VERSION ""

NS_ :

BS_:

BU_: CHUD_LS VKM_LS RCRM_LS MSM_RR_LS MSM_LR_LS CGM_LS BSM_LS VPM_LS ISRVM_LS DCAC_LS TouchPad_LS RSC_LS LVMPC_LS EOCM2B_K1_LS EOCM2A_K1_LS LCM_LS TIM_B_LS V2V_LS TCP_LS CSM_LS EOCM2B_K2_LS EOCM2A_K2_LS TIM_A_LS LVMNav_LS HFP_LS EDI_LS ARB_LS RSE_LS Dummy_LS VIS2_LS ICS_LS FCM_LS EOCM_F_LS VICM_LS AGC_LS MSM_P_LS OTIM_LS HVSM_R_LS HVSM_F_LS DVB_T_LS SBZA_R_LS PSD_R_LS PSD_L_LS UHP_Low UPA_LS STC_LS SBZA_L_LS PTM_LS ONSTAR_LS APA_LS TestTool_LS PHS_LS PDIM_LS CHM_LS RSA_LS AMP_LS HUD_LS MSM_LS HBSM_LS SCL_LS ECC_LS RadioHead_LS PEPS_LS IPC_LS AOS_LS SDM_LS TIM_LS BCM_LS

BO_ 2152775680 Front_360_Camera_On_LS: 8 VPM_LS
 SG_ CrgBdVwLtCustSetVal : 49|2@0+ (1,0) [0|3] ""  CSM_LS,RadioHead_LS
 SG_ CrgBdVwLtCustSetAvl : 54|1@0+ (1,0) [0|1] ""  CSM_LS,RadioHead_LS
 SG_ TrlrMirVGlnCustSetVal : 51|2@0+ (1,0) [0|3] ""  CSM_LS,RadioHead_LS
 SG_ TrlrMirVGlnCustSetAvl : 55|1@0+ (1,0) [0|1] ""  CSM_LS,RadioHead_LS
 SG_ TrlrMirVEnCustSetVal : 30|2@0+ (1,0) [0|3] ""  CSM_LS,RadioHead_LS
 SG_ TrlrMirVEnCustSetAvl : 31|1@0+ (1,0) [0|1] ""  CSM_LS,RadioHead_LS
 SG_ TrlrArtcltnAnglCalStat : 62|2@0+ (1,0) [0|3] ""  CSM_LS,RadioHead_LS
 SG_ InvTrlrAx1CamRollAlgnd : 57|1@0+ (1,0) [0|1] ""  CSM_LS,RadioHead_LS
 SG_ InvTrlrAx1CamPtchAlgnd : 58|1@0+ (1,0) [0|1] ""  CSM_LS,RadioHead_LS
 SG_ InvTrlrAx1CamYAlgnd : 59|1@0+ (1,0) [0|1] ""  CSM_LS,RadioHead_LS
 SG_ InvTrlrAx1CamXAlgnd : 60|1@0+ (1,0) [0|1] ""  CSM_LS,RadioHead_LS
 SG_ RPDCA_Resrv3Avail : 17|1@0+ (1,0) [0|1] ""  CSM_LS,RadioHead_LS
 SG_ RPDCA_Resrv2Avail : 18|1@0+ (1,0) [0|1] ""  CSM_LS,RadioHead_LS
 SG_ RPDCA_Resrv1Avail : 19|1@0+ (1,0) [0|1] ""  CSM_LS,RadioHead_LS
 SG_ RPDCA_AlrtBrkAvail : 20|1@0+ (1,0) [0|1] ""  CSM_LS,RadioHead_LS
 SG_ RPDCA_AlrtAvail : 21|1@0+ (1,0) [0|1] ""  CSM_LS,RadioHead_LS
 SG_ RPDCA_OnAvail : 22|1@0+ (1,0) [0|1] ""  CSM_LS,RadioHead_LS
 SG_ RPDCA_OfAvail : 23|1@0+ (1,0) [0|1] ""  CSM_LS,RadioHead_LS
 SG_ JacknfDetRHapSReqSN : 47|2@0+ (1,0) [0|3] ""  MSM_P_LS,MSM_LS
 SG_ JacknfDetRHapSReq : 45|6@0+ (1,0) [0|63] ""  MSM_P_LS,MSM_LS
 SG_ JacknfDetLHapSReqSN : 39|2@0+ (1,0) [0|3] ""  MSM_P_LS,MSM_LS
 SG_ JacknfDetLHapSReq : 37|6@0+ (1,0) [0|63] ""  MSM_P_LS,MSM_LS
 SG_ JacknfDetCustSetVal : 53|2@0+ (1,0) [0|3] ""  CSM_LS,RadioHead_LS
 SG_ JacknfDetCustSetAvl : 63|1@0+ (1,0) [0|1] ""  CSM_LS,RadioHead_LS
 SG_ DispTrgdVidOn : 14|1@0+ (1,0) [0|1] ""  CSM_LS,RadioHead_LS
 SG_ a_360DegVidFetrPrsnt : 15|1@0+ (1,0) [0|1] ""  CSM_LS,RadioHead_LS
 SG_ TrgdVidRecFetrPrsnt : 7|1@0+ (1,0) [0|1] ""  CSM_LS,RadioHead_LS
 SG_ RrPdDetHptcStVbRq : 13|6@0+ (1,0) [0|63] "Pulse"  MSM_P_LS,MSM_LS
 SG_ RrPdDetHptcStVbRqSeqN : 6|2@0+ (1,0) [0|3] ""  MSM_P_LS,MSM_LS
 SG_ RrPedDetCstStVal : 4|3@0+ (1,0) [0|7] ""  CSM_LS,RadioHead_LS
 SG_ RrPedDetCstStAvl : 1|1@0+ (1,0) [0|1] ""  CSM_LS,RadioHead_LS
 SG_ PudlLmpReqstd : 28|1@0+ (1,0) [0|1] ""  BCM_LS
 SG_ SurdVwLightgCsCurrSetVal : 26|3@0+ (1,0) [0|7] ""  CSM_LS,RadioHead_LS
 SG_ DispSmrtTwVidOn : 16|1@0+ (1,0) [0|1] ""  CSM_LS,RadioHead_LS
 SG_ DispFrt360CamOn : 0|1@0+ (1,0) [0|1] ""  CSM_LS,RadioHead_LS
 SG_ SurdVwLightgCsSetAvail : 27|1@0+ (1,0) [0|1] ""  CSM_LS,RadioHead_LS

BO_ 2153857024 Teen_Driver_Event_Report_2_LS: 8 BCM_LS
 SG_ TnDrvTrCtrlEvntsRpt : 49|10@0+ (1,0) [0|1023] "counts"  CGM_LS,CSM_LS,RadioHead_LS
 SG_ TnDrvDrowDrvAlrtsRpt : 43|10@0+ (1,0) [0|1023] "counts"  CGM_LS,CSM_LS,RadioHead_LS
 SG_ TDRCADD_WOTEvnts : 11|1@0+ (1,0) [0|1] ""  CGM_LS,CSM_LS,RadioHead_LS
 SG_ TDRCADD_LDWEvnts : 10|1@0+ (1,0) [0|1] ""  CGM_LS,CSM_LS,RadioHead_LS
 SG_ TDRCADD_FCMBrEvts : 13|1@0+ (1,0) [0|1] ""  CGM_LS,CSM_LS,RadioHead_LS
 SG_ TDRCADD_DrwDrvAlrt : 12|1@0+ (1,0) [0|1] ""  CGM_LS,CSM_LS,RadioHead_LS
 SG_ TDRCADD_RCMBrEvts : 14|1@0+ (1,0) [0|1] ""  CGM_LS,CSM_LS,RadioHead_LS
 SG_ TDRCADD_FCImntAlrts : 15|1@0+ (1,0) [0|1] ""  CGM_LS,CSM_LS,RadioHead_LS
 SG_ TDRCADD_FCHdwyAlrt : 0|1@0+ (1,0) [0|1] ""  CGM_LS,CSM_LS,RadioHead_LS
 SG_ TDRCADD_StCtrlEvnts : 2|1@0+ (1,0) [0|1] ""  CGM_LS,CSM_LS,RadioHead_LS
 SG_ TDRCADD_ABSAtvEvt : 1|1@0+ (1,0) [0|1] ""  CGM_LS,CSM_LS,RadioHead_LS
 SG_ TDRCADD_TrCtrlEvnts : 3|1@0+ (1,0) [0|1] ""  CGM_LS,CSM_LS,RadioHead_LS
 SG_ TDRCADD_OvSpdEvnt : 4|1@0+ (1,0) [0|1] ""  CGM_LS,CSM_LS,RadioHead_LS
 SG_ TDRCADD_DistDrvn : 5|1@0+ (1,0) [0|1] ""  CGM_LS,CSM_LS,RadioHead_LS
 SG_ TDRCADD_MaxSpd : 6|1@0+ (1,0) [0|1] ""  CGM_LS,CSM_LS,RadioHead_LS
 SG_ TnDrvStblCtrlEvntsRpt : 37|10@0+ (1,0) [0|1023] "counts"  CGM_LS,CSM_LS,RadioHead_LS
 SG_ TnDrvABSAtvEvntsRpt : 31|10@0+ (1,0) [0|1023] "counts"  CGM_LS,CSM_LS,RadioHead_LS
 SG_ TeenDrvWOTEvntsRpt : 9|10@0+ (1,0) [0|1023] "counts"  CGM_LS,CSM_LS,RadioHead_LS

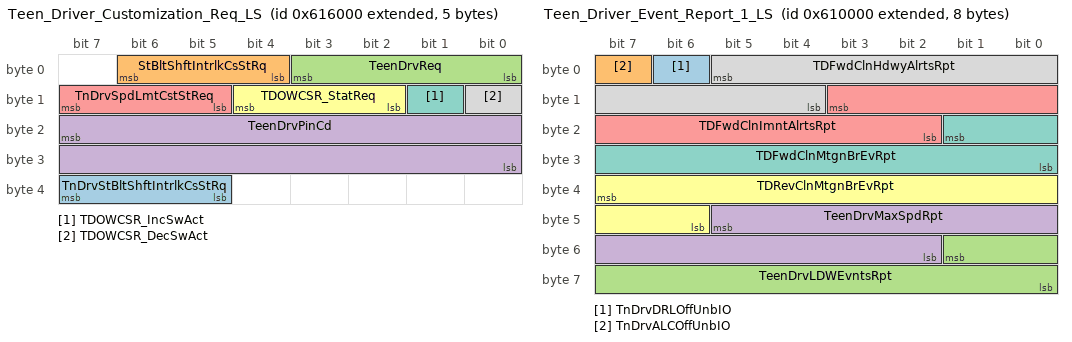
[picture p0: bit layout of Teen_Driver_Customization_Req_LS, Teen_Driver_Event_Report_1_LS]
BO_ 2153865216 Teen_Driver_Customization_Req_LS: 5 RadioHead_LS
 SG_ TnDrvStBltShftIntrlkCsStRq : 39|3@0+ (1,0) [0|7] ""  BCM_LS
 SG_ StBltShftIntrlkCsStRq : 6|3@0+ (1,0) [0|7] ""  BCM_LS
 SG_ TeenDrvReq : 3|4@0+ (1,0) [0|15] ""  BCM_LS
 SG_ TeenDrvPinCd : 23|16@0+ (1,0) [0|39321] ""  BCM_LS
 SG_ TnDrvSpdLmtCstStReq : 15|3@0+ (1,0) [0|7] ""  BCM_LS
 SG_ TDOWCSR_StatReq : 12|3@0+ (1,0) [0|7] ""  BCM_LS
 SG_ TDOWCSR_IncSwAct : 9|1@0+ (1,0) [0|1] ""  BCM_LS
 SG_ TDOWCSR_DecSwAct : 8|1@0+ (1,0) [0|1] ""  BCM_LS

BO_ 2153840640 Teen_Driver_Event_Report_1_LS: 8 BCM_LS
 SG_ TnDrvDRLOffUnbIO : 6|1@0+ (1,0) [0|1] ""  CGM_LS,IPC_LS
 SG_ TnDrvALCOffUnbIO : 7|1@0+ (1,0) [0|1] ""  CGM_LS,IPC_LS
 SG_ TeenDrvLDWEvntsRpt : 49|10@0+ (1,0) [0|1023] "counts"  CGM_LS,CSM_LS,RadioHead_LS
 SG_ TeenDrvMaxSpdRpt : 45|12@0+ (0.0625,0) [0|255.9375] "km/h"  CGM_LS,CSM_LS,RadioHead_LS
 SG_ TDFwdClnImntAlrtsRpt : 11|10@0+ (1,0) [0|1023] "counts"  CGM_LS,CSM_LS,RadioHead_LS
 SG_ TDRevClnMtgnBrEvRpt : 39|10@0+ (1,0) [0|1023] "counts"  CGM_LS,CSM_LS,RadioHead_LS
 SG_ TDFwdClnMtgnBrEvRpt : 17|10@0+ (1,0) [0|1023] "counts"  CGM_LS,CSM_LS,RadioHead_LS
 SG_ TDFwdClnHdwyAlrtsRpt : 5|10@0+ (1,0) [0|1023] "counts"  CGM_LS,CSM_LS,RadioHead_LS

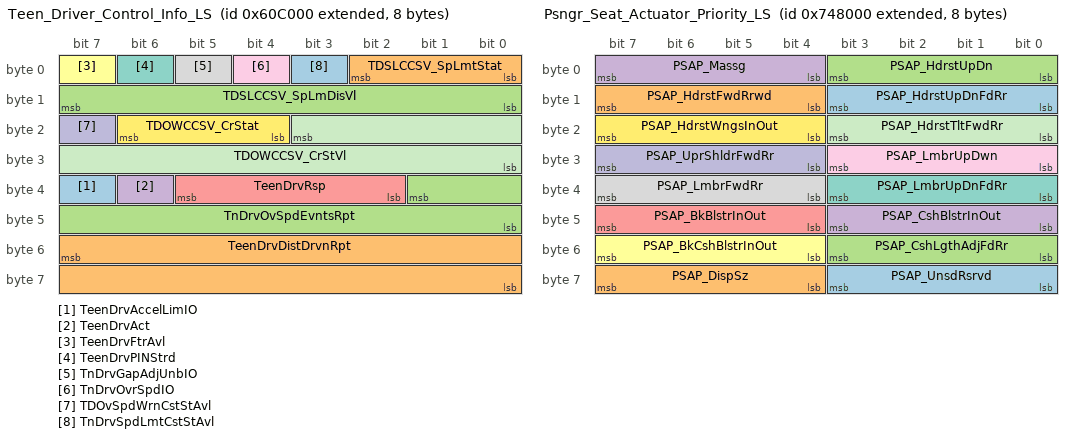
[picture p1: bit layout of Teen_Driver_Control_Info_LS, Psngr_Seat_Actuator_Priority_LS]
BO_ 2153824256 Teen_Driver_Control_Info_LS: 8 BCM_LS
 SG_ TeenDrvAccelLimIO : 39|1@0+ (1,0) [0|1] ""  IPC_LS,CGM_LS
 SG_ TeenDrvDistDrvnRpt : 55|16@0+ (1,0) [0|65535] "km"  EOCM2A_K2_LS,EOCM2B_K2_LS,CGM_LS,CSM_LS,RadioHead_LS
 SG_ TnDrvOvSpdEvntsRpt : 33|10@0+ (1,0) [0|1023] "counts"  EOCM2A_K2_LS,EOCM2B_K2_LS,CGM_LS,CSM_LS,RadioHead_LS
 SG_ TeenDrvAct : 38|1@0+ (1,0) [0|1] ""  EOCM2A_K2_LS,EOCM2B_K2_LS,V2V_LS,CGM_LS,SBZA_R_LS,IPC_LS,SBZA_L_LS,UPA_LS,APA_LS,LVMPC_LS,VIS2_LS,FCM_LS,EOCM_F_LS,CSM_LS,RadioHead_LS
 SG_ TeenDrvRsp : 37|4@0+ (1,0) [0|15] ""  EOCM2A_K2_LS,EOCM2B_K2_LS,CGM_LS,CSM_LS,RadioHead_LS
 SG_ TeenDrvFtrAvl : 7|1@0+ (1,0) [0|1] ""  EOCM2A_K2_LS,EOCM2B_K2_LS,CGM_LS,CSM_LS,RadioHead_LS
 SG_ TeenDrvPINStrd : 6|1@0+ (1,0) [0|1] ""  EOCM2A_K2_LS,EOCM2B_K2_LS,CGM_LS,CSM_LS,RadioHead_LS
 SG_ TnDrvGapAdjUnbIO : 5|1@0+ (1,0) [0|1] ""  EOCM2A_K2_LS,EOCM2B_K2_LS,CGM_LS,IPC_LS
 SG_ TnDrvOvrSpdIO : 4|1@0+ (1,0) [0|1] ""  EOCM2A_K2_LS,EOCM2B_K2_LS,CGM_LS,IPC_LS
 SG_ TDOvSpdWrnCstStAvl : 23|1@0+ (1,0) [0|1] ""  EOCM2A_K2_LS,EOCM2B_K2_LS,CGM_LS,CSM_LS,RadioHead_LS
 SG_ TDOWCCSV_CrStVl : 19|12@0+ (0.0625,0) [0|255.9375] "km/h"  EOCM2A_K2_LS,EOCM2B_K2_LS,CGM_LS,IPC_LS,CSM_LS,RadioHead_LS
 SG_ TDOWCCSV_CrStat : 22|3@0+ (1,0) [0|7] ""  EOCM2A_K2_LS,EOCM2B_K2_LS,CGM_LS,IPC_LS,CSM_LS,RadioHead_LS
 SG_ TnDrvSpdLmtCstStAvl : 3|1@0+ (1,0) [0|1] ""  EOCM2A_K2_LS,EOCM2B_K2_LS,CGM_LS,CSM_LS,RadioHead_LS
 SG_ TDSLCCSV_SpLmtStat : 2|3@0+ (1,0) [0|7] ""  EOCM2A_K2_LS,EOCM2B_K2_LS,CGM_LS,IPC_LS,CSM_LS,RadioHead_LS
 SG_ TDSLCCSV_SpLmDisVl : 15|8@0+ (2,0) [0|510] "km/h"  EOCM2A_K2_LS,EOCM2B_K2_LS,CGM_LS,IPC_LS,CSM_LS,RadioHead_LS

BO_ 2155151360 Psngr_Seat_Massage_Priority_LS: 8 MSM_P_LS
 SG_ PSMP_UnsdRsrvd : 56|1@0+ (1,0) [0|1] ""  CGM_LS,CSM_LS,RadioHead_LS
 SG_ PSMP_MaxDispVal : 59|3@0+ (1,0) [0|7] ""  CGM_LS,CSM_LS,RadioHead_LS
 SG_ PSMP_Type15 : 63|4@0+ (1,0) [0|15] ""  CGM_LS,CSM_LS,RadioHead_LS
 SG_ PSMP_Type14 : 51|4@0+ (1,0) [0|15] ""  CGM_LS,CSM_LS,RadioHead_LS
 SG_ PSMP_Type13 : 55|4@0+ (1,0) [0|15] ""  CGM_LS,CSM_LS,RadioHead_LS
 SG_ PSMP_Type12 : 43|4@0+ (1,0) [0|15] ""  CGM_LS,CSM_LS,RadioHead_LS
 SG_ PSMP_Type11 : 47|4@0+ (1,0) [0|15] ""  CGM_LS,CSM_LS,RadioHead_LS
 SG_ PSMP_Type10 : 35|4@0+ (1,0) [0|15] ""  CGM_LS,CSM_LS,RadioHead_LS
 SG_ PSMP_Type9 : 39|4@0+ (1,0) [0|15] ""  CGM_LS,CSM_LS,RadioHead_LS
 SG_ PSMP_Type8 : 27|4@0+ (1,0) [0|15] ""  CGM_LS,CSM_LS,RadioHead_LS
 SG_ PSMP_Type7 : 31|4@0+ (1,0) [0|15] ""  CGM_LS,CSM_LS,RadioHead_LS
 SG_ PSMP_Type6 : 19|4@0+ (1,0) [0|15] ""  CGM_LS,CSM_LS,RadioHead_LS
 SG_ PSMP_Type5 : 23|4@0+ (1,0) [0|15] ""  CGM_LS,CSM_LS,RadioHead_LS
 SG_ PSMP_Type4 : 11|4@0+ (1,0) [0|15] ""  CGM_LS,CSM_LS,RadioHead_LS
 SG_ PSMP_Type3 : 15|4@0+ (1,0) [0|15] ""  CGM_LS,CSM_LS,RadioHead_LS
 SG_ PSMP_Type2 : 3|4@0+ (1,0) [0|15] ""  CGM_LS,CSM_LS,RadioHead_LS
 SG_ PSMP_Type1 : 7|4@0+ (1,0) [0|15] ""  CGM_LS,CSM_LS,RadioHead_LS

BO_ 2155134976 Psngr_Seat_Control_Disp_Stat_LS: 6 MSM_P_LS
 SG_ PsngrSetRrwdMvmnt : 6|3@0+ (1,0) [0|7] ""  CGM_LS,MSM_RR_LS
 SG_ PSCDS_UnsdRsrvd : 42|3@0+ (1,0) [0|7] ""  CGM_LS,CSM_LS,RadioHead_LS
 SG_ PSCDS_DispReq : 43|1@0+ (1,0) [0|1] ""  CGM_LS,CSM_LS,RadioHead_LS
 SG_ PSCDS_DispSz : 45|2@0+ (1,0) [0|3] ""  CGM_LS,CSM_LS,RadioHead_LS
 SG_ PSCDS_CshLgAdjFdRr : 47|2@0+ (1,0) [0|3] ""  CGM_LS,CSM_LS,RadioHead_LS
 SG_ PSCDS_BkCshBlstInOt : 34|3@0+ (1,0) [0|7] ""  CGM_LS,CSM_LS,RadioHead_LS
 SG_ PSCDS_CshBlstrInOut : 36|2@0+ (1,0) [0|3] ""  CGM_LS,CSM_LS,RadioHead_LS
 SG_ PSCDS_BkBlstrInOut : 38|2@0+ (1,0) [0|3] ""  CGM_LS,CSM_LS,RadioHead_LS
 SG_ PSCDS_LmbrUDnFdRr : 25|3@0+ (1,0) [0|7] ""  CGM_LS,CSM_LS,RadioHead_LS
 SG_ PSCDS_LmbrFwdRr : 27|2@0+ (1,0) [0|3] ""  CGM_LS,CSM_LS,RadioHead_LS
 SG_ PSCDS_LmbrUpDwn : 29|2@0+ (1,0) [0|3] ""  CGM_LS,CSM_LS,RadioHead_LS
 SG_ PSCDS_UprShldrFdRr : 31|2@0+ (1,0) [0|3] ""  CGM_LS,CSM_LS,RadioHead_LS
 SG_ PSCDS_HdrstTltFwdRr : 17|2@0+ (1,0) [0|3] ""  CGM_LS,CSM_LS,RadioHead_LS
 SG_ PSCDS_HdrstWngInOt : 19|2@0+ (1,0) [0|3] ""  CGM_LS,CSM_LS,RadioHead_LS
 SG_ PSCDS_HdrstUDnFdRr : 22|3@0+ (1,0) [0|7] ""  CGM_LS,CSM_LS,RadioHead_LS
 SG_ PSCDS_HdrstFwdRrwd : 8|2@0+ (1,0) [0|3] ""  CGM_LS,CSM_LS,RadioHead_LS
 SG_ PSCDS_HdrstUpDn : 10|2@0+ (1,0) [0|3] ""  CGM_LS,CSM_LS,RadioHead_LS
 SG_ PSCDS_MassgIntsty : 13|3@0+ (1,0) [0|7] ""  CGM_LS,CSM_LS,RadioHead_LS
 SG_ PSCDS_MassgTyp : 1|4@0+ (1,0) [0|15] ""  CGM_LS,CSM_LS,RadioHead_LS
 SG_ PSCDS_Massg : 3|2@0+ (1,0) [0|3] ""  CGM_LS,CSM_LS,RadioHead_LS

BO_ 2155118592 Psngr_Seat_Actuator_Priority_LS: 8 MSM_P_LS
 SG_ PSAP_UnsdRsrvd : 59|4@0+ (1,0) [0|15] ""  CGM_LS,CSM_LS,RadioHead_LS
 SG_ PSAP_DispSz : 63|4@0+ (1,0) [0|15] ""  CGM_LS,CSM_LS,RadioHead_LS
 SG_ PSAP_CshLgthAdjFdRr : 51|4@0+ (1,0) [0|15] ""  CGM_LS,CSM_LS,RadioHead_LS
 SG_ PSAP_CshBlstrInOut : 43|4@0+ (1,0) [0|15] ""  CGM_LS,CSM_LS,RadioHead_LS
 SG_ PSAP_BkBlstrInOut : 47|4@0+ (1,0) [0|15] ""  CGM_LS,CSM_LS,RadioHead_LS
 SG_ PSAP_BkCshBlstrInOut : 55|4@0+ (1,0) [0|15] ""  CGM_LS,CSM_LS,RadioHead_LS
 SG_ PSAP_LmbrUpDnFdRr : 35|4@0+ (1,0) [0|15] ""  CGM_LS,CSM_LS,RadioHead_LS
 SG_ PSAP_LmbrFwdRr : 39|4@0+ (1,0) [0|15] ""  CGM_LS,CSM_LS,RadioHead_LS
 SG_ PSAP_LmbrUpDwn : 27|4@0+ (1,0) [0|15] ""  CGM_LS,CSM_LS,RadioHead_LS
 SG_ PSAP_UprShldrFwdRr : 31|4@0+ (1,0) [0|15] ""  CGM_LS,CSM_LS,RadioHead_LS
 SG_ PSAP_HdrstTltFwdRr : 19|4@0+ (1,0) [0|15] ""  CGM_LS,CSM_LS,RadioHead_LS
 SG_ PSAP_HdrstWngsInOut : 23|4@0+ (1,0) [0|15] ""  CGM_LS,CSM_LS,RadioHead_LS
 SG_ PSAP_HdrstUpDnFdRr : 11|4@0+ (1,0) [0|15] ""  CGM_LS,CSM_LS,RadioHead_LS
 SG_ PSAP_HdrstFwdRrwd : 15|4@0+ (1,0) [0|15] ""  CGM_LS,CSM_LS,RadioHead_LS
 SG_ PSAP_HdrstUpDn : 3|4@0+ (1,0) [0|15] ""  CGM_LS,CSM_LS,RadioHead_LS
 SG_ PSAP_Massg : 7|4@0+ (1,0) [0|15] ""  CGM_LS,CSM_LS,RadioHead_LS

BO_ 2155102208 Driver_Seat_Massage_Priority_LS: 8 MSM_LS
 SG_ DSMP_UnsdRsrvd : 56|1@0+ (1,0) [0|1] ""  CGM_LS,CSM_LS,RadioHead_LS
 SG_ DSMP_MaxDispVal : 59|3@0+ (1,0) [0|7] ""  CGM_LS,CSM_LS,RadioHead_LS
 SG_ DSMP_Type15 : 63|4@0+ (1,0) [0|15] ""  CGM_LS,CSM_LS,RadioHead_LS
 SG_ DSMP_Type14 : 51|4@0+ (1,0) [0|15] ""  CGM_LS,CSM_LS,RadioHead_LS
 SG_ DSMP_Type13 : 55|4@0+ (1,0) [0|15] ""  CGM_LS,CSM_LS,RadioHead_LS
 SG_ DSMP_Type12 : 43|4@0+ (1,0) [0|15] ""  CGM_LS,CSM_LS,RadioHead_LS
 SG_ DSMP_Type11 : 47|4@0+ (1,0) [0|15] ""  CGM_LS,CSM_LS,RadioHead_LS
 SG_ DSMP_Type10 : 35|4@0+ (1,0) [0|15] ""  CGM_LS,CSM_LS,RadioHead_LS
 SG_ DSMP_Type9 : 39|4@0+ (1,0) [0|15] ""  CGM_LS,CSM_LS,RadioHead_LS
 SG_ DSMP_Type8 : 27|4@0+ (1,0) [0|15] ""  CGM_LS,CSM_LS,RadioHead_LS
 SG_ DSMP_Type7 : 31|4@0+ (1,0) [0|15] ""  CGM_LS,CSM_LS,RadioHead_LS
 SG_ DSMP_Type6 : 19|4@0+ (1,0) [0|15] ""  CGM_LS,CSM_LS,RadioHead_LS
 SG_ DSMP_Type5 : 23|4@0+ (1,0) [0|15] ""  CGM_LS,CSM_LS,RadioHead_LS
 SG_ DSMP_Type4 : 11|4@0+ (1,0) [0|15] ""  CGM_LS,CSM_LS,RadioHead_LS
 SG_ DSMP_Type3 : 15|4@0+ (1,0) [0|15] ""  CGM_LS,CSM_LS,RadioHead_LS
 SG_ DSMP_Type2 : 3|4@0+ (1,0) [0|15] ""  CGM_LS,CSM_LS,RadioHead_LS
 SG_ DSMP_Type1 : 7|4@0+ (1,0) [0|15] ""  CGM_LS,CSM_LS,RadioHead_LS

BO_ 2155085824 Driver_Seat_Control_Disp_Stat_LS: 8 MSM_LS
 SG_ StrgColUpDwnPos : 63|8@0+ (1,0) [0|255] ""  EOCM2B_K1_LS,EOCM2A_K1_LS,CGM_LS
 SG_ CPMAPINFO4 : 5|1@0+ (1,0) [0|1] ""  EOCM2B_K1_LS,EOCM2A_K1_LS,CGM_LS
 SG_ StrgColInOutPos : 55|8@0+ (1,0) [0|255] ""  EOCM2B_K1_LS,EOCM2A_K1_LS,CGM_LS
 SG_ StrgColCommsFlt : 7|2@0+ (1,0) [0|3] ""  EOCM2B_K1_LS,EOCM2A_K1_LS,CGM_LS
 SG_ DSCDS_UnsdRsrvd : 42|3@0+ (1,0) [0|7] ""  CGM_LS,CSM_LS,RadioHead_LS
 SG_ DSCDS_DispReq : 43|1@0+ (1,0) [0|1] ""  CGM_LS,CSM_LS,RadioHead_LS
 SG_ DSCDS_DispSz : 45|2@0+ (1,0) [0|3] ""  CGM_LS,CSM_LS,RadioHead_LS
 SG_ DSCDS_CshLgAdjFdRr : 47|2@0+ (1,0) [0|3] ""  CGM_LS,CSM_LS,RadioHead_LS
 SG_ DSCDS_BkCshBlstInOt : 34|3@0+ (1,0) [0|7] ""  CGM_LS,CSM_LS,RadioHead_LS
 SG_ DSCDS_CshBlstrInOut : 36|2@0+ (1,0) [0|3] ""  CGM_LS,CSM_LS,RadioHead_LS
 SG_ DSCDS_BkBlstrInOut : 38|2@0+ (1,0) [0|3] ""  CGM_LS,CSM_LS,RadioHead_LS
 SG_ DSCDS_LmbrUDnFdRr : 25|3@0+ (1,0) [0|7] ""  CGM_LS,CSM_LS,RadioHead_LS
 SG_ DSCDS_LmbrFwdRr : 27|2@0+ (1,0) [0|3] ""  CGM_LS,CSM_LS,RadioHead_LS
 SG_ DSCDS_LmbrUpDwn : 29|2@0+ (1,0) [0|3] ""  CGM_LS,CSM_LS,RadioHead_LS
 SG_ DSCDS_UprShldrFdRr : 31|2@0+ (1,0) [0|3] ""  CGM_LS,CSM_LS,RadioHead_LS
 SG_ DSCDS_HdrstTltFwdRr : 17|2@0+ (1,0) [0|3] ""  CGM_LS,CSM_LS,RadioHead_LS
 SG_ DSCDS_HdrstWngInOt : 19|2@0+ (1,0) [0|3] ""  CGM_LS,CSM_LS,RadioHead_LS
 SG_ DSCDS_HdrstUDnFdRr : 22|3@0+ (1,0) [0|7] ""  CGM_LS,CSM_LS,RadioHead_LS
 SG_ DSCDS_HdrstFwdRrwd : 8|2@0+ (1,0) [0|3] ""  CGM_LS,CSM_LS,RadioHead_LS
 SG_ DSCDS_HdrstUpDn : 10|2@0+ (1,0) [0|3] ""  CGM_LS,CSM_LS,RadioHead_LS
 SG_ DSCDS_MassgIntsty : 13|3@0+ (1,0) [0|7] ""  CGM_LS,CSM_LS,RadioHead_LS
 SG_ DSCDS_MassgTyp : 1|4@0+ (1,0) [0|15] ""  CGM_LS,CSM_LS,RadioHead_LS
 SG_ DSCDS_Massg : 3|2@0+ (1,0) [0|3] ""  CGM_LS,CSM_LS,RadioHead_LS

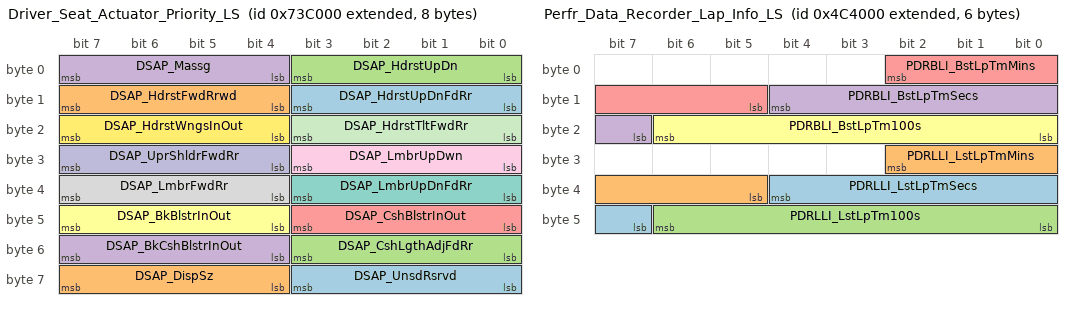
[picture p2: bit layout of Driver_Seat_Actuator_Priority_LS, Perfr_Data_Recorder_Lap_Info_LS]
BO_ 2155069440 Driver_Seat_Actuator_Priority_LS: 8 MSM_LS
 SG_ DSAP_UnsdRsrvd : 59|4@0+ (1,0) [0|15] ""  CGM_LS,CSM_LS,RadioHead_LS
 SG_ DSAP_DispSz : 63|4@0+ (1,0) [0|15] ""  CGM_LS,CSM_LS,RadioHead_LS
 SG_ DSAP_CshLgthAdjFdRr : 51|4@0+ (1,0) [0|15] ""  CGM_LS,CSM_LS,RadioHead_LS
 SG_ DSAP_BkCshBlstrInOut : 55|4@0+ (1,0) [0|15] ""  CGM_LS,CSM_LS,RadioHead_LS
 SG_ DSAP_CshBlstrInOut : 43|4@0+ (1,0) [0|15] ""  CGM_LS,CSM_LS,RadioHead_LS
 SG_ DSAP_BkBlstrInOut : 47|4@0+ (1,0) [0|15] ""  CGM_LS,CSM_LS,RadioHead_LS
 SG_ DSAP_LmbrUpDnFdRr : 35|4@0+ (1,0) [0|15] ""  CGM_LS,CSM_LS,RadioHead_LS
 SG_ DSAP_LmbrFwdRr : 39|4@0+ (1,0) [0|15] ""  CGM_LS,CSM_LS,RadioHead_LS
 SG_ DSAP_LmbrUpDwn : 27|4@0+ (1,0) [0|15] ""  CGM_LS,CSM_LS,RadioHead_LS
 SG_ DSAP_UprShldrFwdRr : 31|4@0+ (1,0) [0|15] ""  CGM_LS,CSM_LS,RadioHead_LS
 SG_ DSAP_HdrstTltFwdRr : 19|4@0+ (1,0) [0|15] ""  CGM_LS,CSM_LS,RadioHead_LS
 SG_ DSAP_HdrstWngsInOut : 23|4@0+ (1,0) [0|15] ""  CGM_LS,CSM_LS,RadioHead_LS
 SG_ DSAP_HdrstUpDnFdRr : 11|4@0+ (1,0) [0|15] ""  CGM_LS,CSM_LS,RadioHead_LS
 SG_ DSAP_HdrstFwdRrwd : 15|4@0+ (1,0) [0|15] ""  CGM_LS,CSM_LS,RadioHead_LS
 SG_ DSAP_HdrstUpDn : 3|4@0+ (1,0) [0|15] ""  CGM_LS,CSM_LS,RadioHead_LS
 SG_ DSAP_Massg : 7|4@0+ (1,0) [0|15] ""  CGM_LS,CSM_LS,RadioHead_LS

BO_ 2156937216 PassPhrase_Digits_17_to_24_LS: 8 ONSTAR_LS
 SG_ WiFiPssPhrsDgts17to24 : 7|64@0+ (1,0) [0|0] ""  CGM_LS,CSM_LS,RadioHead_LS

BO_ 2156929024 PassPhrase_Digits_9_to_16_LS: 8 ONSTAR_LS
 SG_ WiFiPssPhrsDgts9to16 : 7|64@0+ (1,0) [0|0] ""  CGM_LS,CSM_LS,RadioHead_LS

BO_ 2156920832 PassPhrase_Digits_1_to_8_LS: 8 ONSTAR_LS
 SG_ WiFiPssPhrsDgts1to8 : 7|64@0+ (1,0) [0|0] ""  CGM_LS,CSM_LS,RadioHead_LS

BO_ 2156871680 SSID_Digits_17_to_24_LS: 8 ONSTAR_LS
 SG_ WiFiSSIDDgts17to24 : 7|64@0+ (1,0) [0|0] ""  CGM_LS,RadioHead_LS

BO_ 2156863488 SSID_Digits_9_to_16_LS: 8 ONSTAR_LS
 SG_ WiFiSSIDDgts9to16 : 7|64@0+ (1,0) [0|0] ""  CGM_LS,RadioHead_LS

BO_ 2156855296 SSID_Digits_1_to_8_LS: 8 ONSTAR_LS
 SG_ WiFiSSIDDgts1to8 : 7|64@0+ (1,0) [0|0] ""  CGM_LS,RadioHead_LS

BO_ 2152480768 Perfr_Data_Recorder_Lap_Info_LS: 6 LVMPC_LS
 SG_ PDRLLI_LstLpTmSecs : 36|6@0+ (1,0) [0|63] "sec"  CGM_LS,IPC_LS
 SG_ PDRLLI_LstLpTmMins : 26|6@0+ (1,0) [0|63] "min"  CGM_LS,IPC_LS
 SG_ PDRLLI_LstLpTm100s : 46|7@0+ (0.01,0) [0|1.27] "sec"  CGM_LS,IPC_LS
 SG_ PDRBLI_BstLpTmSecs : 12|6@0+ (1,0) [0|63] "sec"  CGM_LS,IPC_LS
 SG_ PDRBLI_BstLpTmMins : 2|6@0+ (1,0) [0|63] "min"  CGM_LS,IPC_LS
 SG_ PDRBLI_BstLpTm100s : 22|7@0+ (0.01,0) [0|1.27] "sec"  CGM_LS,IPC_LS

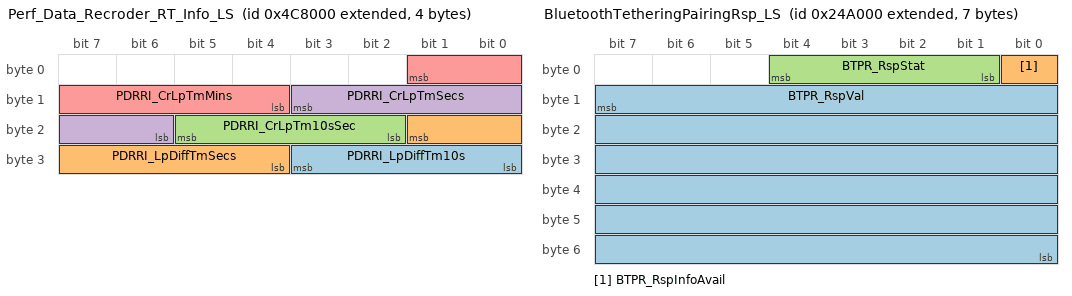
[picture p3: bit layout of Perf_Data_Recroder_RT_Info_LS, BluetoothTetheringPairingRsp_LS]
BO_ 2152497152 Perf_Data_Recroder_RT_Info_LS: 4 LVMPC_LS
 SG_ PDRRI_LpDiffTm10s : 27|4@0+ (0.1,0) [0|1.5] "sec"  CGM_LS,IPC_LS
 SG_ PDRRI_LpDiffTmSecs : 17|6@0+ (1,0) [0|63] "sec"  CGM_LS,IPC_LS
 SG_ PDRRI_CrLpTm10sSec : 21|4@0+ (0.1,0) [0|1.5] "sec"  CGM_LS,IPC_LS
 SG_ PDRRI_CrLpTmSecs : 11|6@0+ (1,0) [0|63] ""  CGM_LS,IPC_LS
 SG_ PDRRI_CrLpTmMins : 1|6@0+ (1,0) [0|63] "min"  CGM_LS,IPC_LS

BO_ 2153791488 ARB_State_LS: 1 ARB_LS
 SG_ ArtcldRngBrdSt : 2|3@0+ (1,0) [0|7] ""  CGM_LS,IPC_LS

BO_ 2149883904 BluetoothTetheringPairingRsp_LS: 7 RadioHead_LS
 SG_ BTPR_RspVal : 15|48@0+ (1,0) [0|281474976710655] ""  CGM_LS,ONSTAR_LS
 SG_ BTPR_RspInfoAvail : 0|1@0+ (1,0) [0|1] ""  CGM_LS,ONSTAR_LS
 SG_ BTPR_RspStat : 4|4@0+ (1,0) [0|15] ""  CGM_LS,ONSTAR_LS

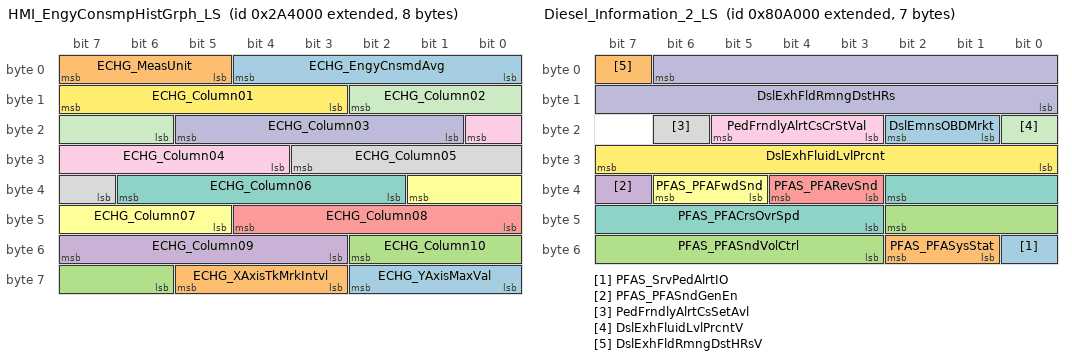
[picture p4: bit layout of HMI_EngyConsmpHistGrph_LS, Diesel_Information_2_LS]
BO_ 2150252544 HMI_EngyConsmpHistGrph_LS: 8 VICM_LS
 SG_ ECHG_YAxisMaxVal : 58|3@0+ (1,0) [0|7] ""  CGM_LS,CSM_LS,RadioHead_LS
 SG_ ECHG_XAxisTkMrkIntvl : 61|3@0+ (1,0) [0|7] ""  CGM_LS,CSM_LS,RadioHead_LS
 SG_ ECHG_Column10 : 50|5@0+ (1,0) [0|31] ""  CGM_LS,CSM_LS,RadioHead_LS
 SG_ ECHG_Column09 : 55|5@0+ (1,0) [0|31] ""  CGM_LS,CSM_LS,RadioHead_LS
 SG_ ECHG_Column08 : 44|5@0+ (1,0) [0|31] ""  CGM_LS,CSM_LS,RadioHead_LS
 SG_ ECHG_Column07 : 33|5@0+ (1,0) [0|31] ""  CGM_LS,CSM_LS,RadioHead_LS
 SG_ ECHG_Column06 : 38|5@0+ (1,0) [0|31] ""  CGM_LS,CSM_LS,RadioHead_LS
 SG_ ECHG_Column05 : 27|5@0+ (1,0) [0|31] ""  CGM_LS,CSM_LS,RadioHead_LS
 SG_ ECHG_Column04 : 16|5@0+ (1,0) [0|31] ""  CGM_LS,CSM_LS,RadioHead_LS
 SG_ ECHG_Column03 : 21|5@0+ (1,0) [0|31] ""  CGM_LS,CSM_LS,RadioHead_LS
 SG_ ECHG_Column02 : 10|5@0+ (1,0) [0|31] ""  CGM_LS,CSM_LS,RadioHead_LS
 SG_ ECHG_Column01 : 15|5@0+ (1,0) [0|31] ""  CGM_LS,CSM_LS,RadioHead_LS
 SG_ ECHG_EngyCnsmdAvg : 4|5@0+ (1,0) [0|31] ""  CGM_LS,CSM_LS,RadioHead_LS
 SG_ ECHG_MeasUnit : 7|3@0+ (1,0) [0|7] ""  CGM_LS,CSM_LS,RadioHead_LS

BO_ 2150391808 HMI_Hourmeter_Data_LS: 6 IPC_LS
 SG_ EngRunAtvTm : 31|24@0+ (1,0) [0|16777215] "min"  BCM_LS
 SG_ EngIdlAtvTm : 7|24@0+ (1,0) [0|16777215] "min"  BCM_LS

BO_ 2155913216 Diesel_Information_2_LS: 7 BCM_LS
 SG_ PFAS_SrvPedAlrtIO : 48|1@0+ (1,0) [0|1] ""  CGM_LS,IPC_LS
 SG_ PFAS_PFASysStat : 50|2@0+ (1,0) [0|3] ""  CGM_LS,IPC_LS
 SG_ PFAS_PFASndVolCtrl : 42|8@0+ (0.392157,0) [0|100.000035] "%"  CGM_LS,IPC_LS
 SG_ PFAS_PFASndGenEn : 39|1@0+ (1,0) [0|1] ""  CGM_LS,IPC_LS
 SG_ PFAS_PFARevSnd : 36|2@0+ (1,0) [0|3] ""  CGM_LS,IPC_LS
 SG_ PFAS_PFAFwdSnd : 38|2@0+ (1,0) [0|3] ""  CGM_LS,IPC_LS
 SG_ PFAS_PFACrsOvrSpd : 34|8@0+ (1,0) [0|255] "km/h"  CGM_LS,IPC_LS
 SG_ PedFrndlyAlrtCsSetAvl : 22|1@0+ (1,0) [0|1] ""  CGM_LS,CSM_LS,RadioHead_LS
 SG_ PedFrndlyAlrtCsCrStVal : 21|3@0+ (1,0) [0|7] ""  CGM_LS,CSM_LS,RadioHead_LS
 SG_ DslExhFldRmngDstHRs : 6|15@0+ (2,0) [0|65534] "km"  CSM_LS,CGM_LS,IPC_LS
 SG_ DslExhFluidLvlPrcntV : 16|1@0+ (1,0) [0|1] ""  CGM_LS,IPC_LS
 SG_ DslExhFluidLvlPrcnt : 31|8@0+ (0.392157,0) [0|100.000035] "%"  CGM_LS,IPC_LS
 SG_ DslEmnsOBDMrkt : 18|2@0+ (1,0) [0|3] ""  CGM_LS,IPC_LS
 SG_ DslExhFldRmngDstHRsV : 7|1@0+ (1,0) [0|1] ""  CSM_LS,CGM_LS,IPC_LS

BO_ 2034 CCP_Data_Transmission_Object_LS: 8 PTM_LS
 SG_ DgnInf : 7|64@0+ (1,0) [0|1.84467440737096E+019] ""  CGM_LS,TestTool_LS

BO_ 2032 CCP_Command_Receive_Object_LS: 8 TestTool_LS
 SG_ DgnInf : 7|64@0+ (1,0) [0|1.84467440737096E+019] ""  VIS2_LS,FCM_LS,PTM_LS

BO_ 2152095744 HSGMLAN_Customization_Setings_LS: 5 BCM_LS
 SG_ SPMCA_SusPrfMd6Avl : 32|1@0+ (1,0) [0|1] ""  CGM_LS,CSM_LS,RadioHead_LS
 SG_ SPMCA_SusPrfMd5Avl : 33|1@0+ (1,0) [0|1] ""  CGM_LS,CSM_LS,RadioHead_LS
 SG_ SPMCA_SusPrfMd4Avl : 34|1@0+ (1,0) [0|1] ""  CGM_LS,CSM_LS,RadioHead_LS
 SG_ SPMCA_SusPrfMd3Avl : 35|1@0+ (1,0) [0|1] ""  CGM_LS,CSM_LS,RadioHead_LS
 SG_ SPMCA_SusPrfMd2Avl : 36|1@0+ (1,0) [0|1] ""  CGM_LS,CSM_LS,RadioHead_LS
 SG_ SPMCA_SusPrfMd1Avl : 37|1@0+ (1,0) [0|1] ""  CGM_LS,CSM_LS,RadioHead_LS
 SG_ SPMCA_StrPrfMd6Avl : 24|1@0+ (1,0) [0|1] ""  CGM_LS,CSM_LS,RadioHead_LS
 SG_ SPMCA_StrPrfMd5Avl : 25|1@0+ (1,0) [0|1] ""  CGM_LS,CSM_LS,RadioHead_LS
 SG_ SPMCA_StrPrfMd4Avl : 26|1@0+ (1,0) [0|1] ""  CGM_LS,CSM_LS,RadioHead_LS
 SG_ SPMCA_StrPrfMd3Avl : 27|1@0+ (1,0) [0|1] ""  CGM_LS,CSM_LS,RadioHead_LS
 SG_ SPMCA_StrPrfMd2Avl : 28|1@0+ (1,0) [0|1] ""  CGM_LS,CSM_LS,RadioHead_LS
 SG_ SPMCA_StrPrfMd1Avl : 29|1@0+ (1,0) [0|1] ""  CGM_LS,CSM_LS,RadioHead_LS
 SG_ SPMCA_SndPrfMd6Avl : 16|1@0+ (1,0) [0|1] ""  CGM_LS,CSM_LS,RadioHead_LS
 SG_ SPMCA_SndPrfMd5Avl : 17|1@0+ (1,0) [0|1] ""  CGM_LS,CSM_LS,RadioHead_LS
 SG_ SPMCA_SndPrfMd4Avl : 18|1@0+ (1,0) [0|1] ""  CGM_LS,CSM_LS,RadioHead_LS
 SG_ SPMCA_SndPrfMd3Avl : 19|1@0+ (1,0) [0|1] ""  CGM_LS,CSM_LS,RadioHead_LS
 SG_ SPMCA_SndPrfMd2Avl : 20|1@0+ (1,0) [0|1] ""  CGM_LS,CSM_LS,RadioHead_LS
 SG_ SPMCA_SndPrfMd1Avl : 21|1@0+ (1,0) [0|1] ""  CGM_LS,CSM_LS,RadioHead_LS
 SG_ DPMCA_DispPrfMd6Avl : 8|1@0+ (1,0) [0|1] ""  CGM_LS,CSM_LS,RadioHead_LS
 SG_ DPMCA_DispPrfMd5Avl : 9|1@0+ (1,0) [0|1] ""  CGM_LS,CSM_LS,RadioHead_LS
 SG_ DPMCA_DispPrfMd4Avl : 10|1@0+ (1,0) [0|1] ""  CGM_LS,CSM_LS,RadioHead_LS
 SG_ DPMCA_DispPrfMd3Avl : 11|1@0+ (1,0) [0|1] ""  CGM_LS,CSM_LS,RadioHead_LS
 SG_ DPMCA_DispPrfMd2Avl : 12|1@0+ (1,0) [0|1] ""  CGM_LS,CSM_LS,RadioHead_LS
 SG_ DPMCA_DispPrfMd1Avl : 13|1@0+ (1,0) [0|1] ""  CGM_LS,CSM_LS,RadioHead_LS
 SG_ DPMCA_DrvlPrfMd6Avl : 0|1@0+ (1,0) [0|1] ""  CGM_LS,CSM_LS,RadioHead_LS
 SG_ DPMCA_DrvlPrfMd5Avl : 1|1@0+ (1,0) [0|1] ""  CGM_LS,CSM_LS,RadioHead_LS
 SG_ DPMCA_DrvlPrfMd4Avl : 2|1@0+ (1,0) [0|1] ""  CGM_LS,CSM_LS,RadioHead_LS
 SG_ DPMCA_DrvlPrfMd3Avl : 3|1@0+ (1,0) [0|1] ""  CGM_LS,CSM_LS,RadioHead_LS
 SG_ DPMCA_DrvlPrfMd2Avl : 4|1@0+ (1,0) [0|1] ""  CGM_LS,CSM_LS,RadioHead_LS
 SG_ DPMCA_DrvlPrfMd1Avl : 5|1@0+ (1,0) [0|1] ""  CGM_LS,CSM_LS,RadioHead_LS

BO_ 2156945408 SSID_AMM_1_LS: 8 CGM_LS
 SG_ WiFiSSIDDgts1to8_Mp : 7|64@0+ (1,0) [0|0] ""  EOCM2A_K1_LS,EOCM2B_K1_LS

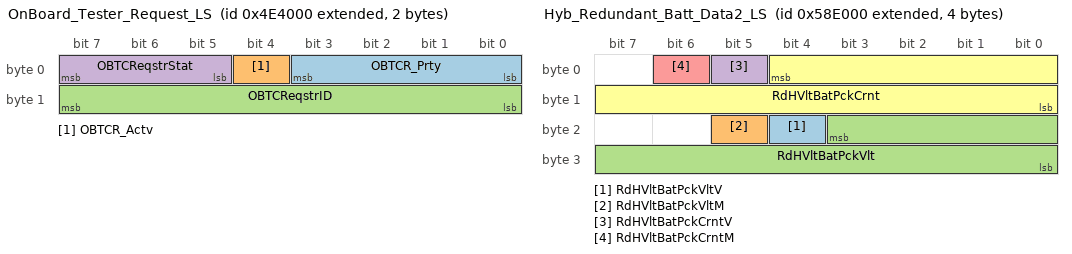
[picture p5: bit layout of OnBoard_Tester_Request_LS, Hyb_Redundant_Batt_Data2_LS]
BO_ 2152611840 OnBoard_Tester_Request_LS: 2 CSM_LS
 SG_ OBTCR_Prty : 3|4@0+ (1,0) [0|15] ""  CGM_LS,TCP_LS
 SG_ OBTCR_Actv : 4|1@0+ (1,0) [0|1] ""  CGM_LS,TCP_LS
 SG_ OBTCReqstrID : 15|8@0+ (1,0) [0|255] ""  CGM_LS,TCP_LS
 SG_ OBTCReqstrStat : 7|3@0+ (1,0) [0|7] ""  CGM_LS,TCP_LS

BO_ 2153308160 Hyb_Redundant_Batt_Data2_LS: 4 VICM_LS
 SG_ RdHVltBatPckVltV : 20|1@0+ (1,0) [0|1] ""  CGM_LS,IPC_LS,CSM_LS,RadioHead_LS
 SG_ RdHVltBatPckVltM : 21|1@0+ (1,0) [0|1] ""  CGM_LS,IPC_LS,CSM_LS,RadioHead_LS
 SG_ RdHVltBatPckVlt : 19|12@0+ (0.125,0) [0|511.875] "V"  CGM_LS,IPC_LS,CSM_LS,RadioHead_LS
 SG_ RdHVltBatPckCrntV : 5|1@0+ (1,0) [0|1] ""  CGM_LS,IPC_LS,CSM_LS,RadioHead_LS
 SG_ RdHVltBatPckCrntM : 6|1@0+ (1,0) [0|1] ""  CGM_LS,IPC_LS,CSM_LS,RadioHead_LS
 SG_ RdHVltBatPckCrnt : 4|13@0- (0.15,0) [-614.4|614.25] "A"  CGM_LS,IPC_LS,CSM_LS,RadioHead_LS

BO_ 2155970560 HVAC_PowerManager_Status_LS: 1 ECC_LS
 SG_ ClmCntLdShdLvlRq : 3|4@0+ (1,0) [0|15] ""  BCM_LS,CGM_LS,HVSM_R_LS,MSM_P_LS,HVSM_F_LS,MSM_LS
 SG_ ClmCntBatSaverIO : 5|1@0+ (1,0) [0|1] ""  CGM_LS,IPC_LS

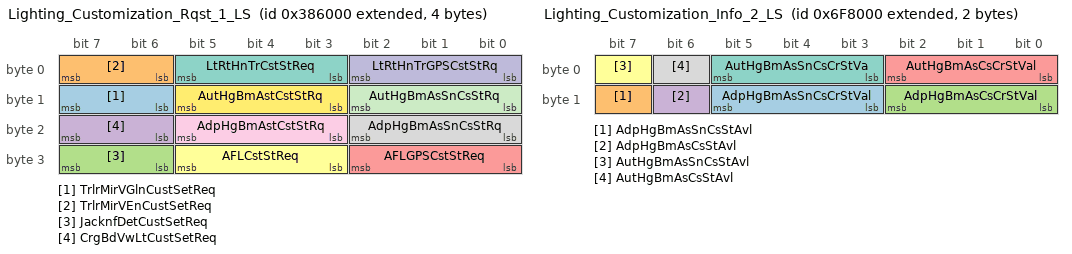
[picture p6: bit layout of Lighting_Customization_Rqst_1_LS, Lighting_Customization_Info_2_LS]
BO_ 2151178240 Lighting_Customization_Rqst_1_LS: 4 RadioHead_LS
 SG_ TrlrMirVGlnCustSetReq : 15|2@0+ (1,0) [0|3] ""  VPM_LS
 SG_ TrlrMirVEnCustSetReq : 7|2@0+ (1,0) [0|3] ""  VPM_LS
 SG_ JacknfDetCustSetReq : 31|2@0+ (1,0) [0|3] ""  VPM_LS
 SG_ CrgBdVwLtCustSetReq : 23|2@0+ (1,0) [0|3] ""  VPM_LS
 SG_ AFLGPSCstStReq : 26|3@0+ (1,0) [0|7] ""  EOCM2B_K2_LS,EOCM2A_K2_LS,VIS2_LS,FCM_LS,HBSM_LS,BCM_LS
 SG_ AFLCstStReq : 29|3@0+ (1,0) [0|7] ""  EOCM2B_K2_LS,EOCM2A_K2_LS,VIS2_LS,FCM_LS,HBSM_LS,BCM_LS
 SG_ LtRtHnTrCstStReq : 5|3@0+ (1,0) [0|7] ""  BCM_LS
 SG_ AdpHgBmAsSnCsStRq : 18|3@0+ (1,0) [0|7] ""  EOCM2B_K2_LS,EOCM2A_K2_LS,VIS2_LS,FCM_LS,HBSM_LS,BCM_LS
 SG_ AdpHgBmAstCstStRq : 21|3@0+ (1,0) [0|7] ""  EOCM2B_K2_LS,EOCM2A_K2_LS,VIS2_LS,FCM_LS,HBSM_LS,BCM_LS
 SG_ LtRtHnTrGPSCstStRq : 2|3@0+ (1,0) [0|7] ""  BCM_LS
 SG_ AutHgBmAsSnCsStRq : 10|3@0+ (1,0) [0|7] ""  EOCM2B_K2_LS,EOCM2A_K2_LS,VIS2_LS,EOCM_F_LS,FCM_LS,HBSM_LS,BCM_LS
 SG_ AutHgBmAstCstStRq : 13|3@0+ (1,0) [0|7] ""  EOCM2B_K2_LS,EOCM2A_K2_LS,VIS2_LS,EOCM_F_LS,FCM_LS,HBSM_LS,BCM_LS

BO_ 2154790912 Lighting_Customization_Info_2_LS: 2 BCM_LS
 SG_ AdpHgBmAsSnCsCrStVal : 13|3@0+ (1,0) [0|7] ""  CGM_LS,CSM_LS,RadioHead_LS
 SG_ AdpHgBmAsSnCsStAvl : 15|1@0+ (1,0) [0|1] ""  CGM_LS,CSM_LS,RadioHead_LS
 SG_ AdpHgBmAsCsCrStVal : 10|3@0+ (1,0) [0|7] ""  CGM_LS,CSM_LS,RadioHead_LS
 SG_ AdpHgBmAsCsStAvl : 14|1@0+ (1,0) [0|1] ""  CGM_LS,CSM_LS,RadioHead_LS
 SG_ AutHgBmAsCsCrStVal : 2|3@0+ (1,0) [0|7] ""  CGM_LS,CSM_LS,RadioHead_LS
 SG_ AutHgBmAsSnCsStAvl : 7|1@0+ (1,0) [0|1] ""  CGM_LS,CSM_LS,RadioHead_LS
 SG_ AutHgBmAsSnCsCrStVa : 5|3@0+ (1,0) [0|7] ""  CGM_LS,CSM_LS,RadioHead_LS
 SG_ AutHgBmAsCsStAvl : 6|1@0+ (1,0) [0|1] ""  CGM_LS,CSM_LS,RadioHead_LS

BO_TX_BU_ 2152775680 : CGM_LS,VPM_LS;
BO_TX_BU_ 2153865216 : CGM_LS,CSM_LS,RadioHead_LS;
BO_TX_BU_ 2156937216 : TCP_LS,ONSTAR_LS;
BO_TX_BU_ 2156929024 : TCP_LS,ONSTAR_LS;
BO_TX_BU_ 2156920832 : TCP_LS,ONSTAR_LS;
BO_TX_BU_ 2150252544 : BSM_LS,VICM_LS;
BO_TX_BU_ 2150391808 : CGM_LS,IPC_LS;
BO_TX_BU_ 2034 : VIS2_LS,FCM_LS,PTM_LS;
BO_TX_BU_ 2032 : CGM_LS,TestTool_LS;
BO_TX_BU_ 2156945408 : CSM_LS,ONSTAR_LS,CGM_LS;
BO_TX_BU_ 2153308160 : BSM_LS,VICM_LS;
BO_TX_BU_ 2151178240 : CGM_LS,CSM_LS,RadioHead_LS;
BO_TX_BU_ 2154790912 : EOCM2A_K2_LS,VIS2_LS,EOCM_F_LS,FCM_LS,HBSM_LS,BCM_LS;
BA_DEF_ SG_  "VNSigPrimaryTriggering" ENUM  "No","Yes","DLCLS","DLCHS","DLCCE","DLCFO";
BA_DEF_ SG_  "VNSigRemoteDiagnostics" ENUM  "No","Yes","DLCLS","DLCHS","DLCCE","DLCFO";
BA_DEF_ SG_  "VNSigInfotainment" ENUM  "No","Yes","DLCLS","DLCHS","DLCCE","DLCFO";
BA_DEF_ SG_  "VNSigParkedVehicle" ENUM  "No","Yes","DLCLS","DLCHS","DLCCE","DLCFO";
BA_DEF_ SG_  "VNSigIntermediate" ENUM  "No","Yes","DLCLS","DLCHS","DLCCE","DLCFO";
BA_DEF_ SG_  "VNSigUnused_4" ENUM  "No","Yes","DLCLS","DLCHS","DLCCE","DLCFO";
BA_DEF_ SG_  "SignalType" STRING ;
BA_DEF_ SG_  "PacketOrder" INT 0 65535;
BA_DEF_ SG_  "SignalLongName" STRING ;
BA_DEF_ SG_  "GenSigStartValue" INT 0 65535;
BA_DEF_ SG_  "VNSigDiagnostic" ENUM  "No","Yes","DLCLS","DLCHS","DLCCE","DLCFO";
BA_DEF_ SG_  "VNSigAllNodes" ENUM  "No","Yes","DLCLS","DLCHS","DLCCE","DLCFO";
BA_DEF_ SG_  "GenSigDeltaValue" INT 0 0;
BA_DEF_ SG_  "GenSigInactiveValue" INT 0 0;
BA_DEF_ SG_  "GenSigSendType" ENUM  "not used","not used","not used","not used","not used","not used","not used","NoSigSendType","not used","not used","OnAnyChange","OnChangeIfActive","OnDelta","DLCLS","DLCHS","DLCCE","DLCFO";
BA_DEF_ SG_  "GenSigSendOnInit" ENUM  "Not Initialized","Application","Handler","DLCLS","DLCHS","DLCCE","DLCFO";
BA_DEF_ BO_  "AppGenMsgCycleTime" INT 0 0;
BA_DEF_ BO_  "TpTxIndex" INT 0 99;
BA_DEF_ BO_  "GenMsgILSupport" ENUM  "No","Yes","DLCLS","DLCHS","DLCCE","DLCFO";
BA_DEF_ BO_  "TpApplType" STRING ;
BA_DEF_ BO_  "Prio" INT 0 7;
BA_DEF_ BO_  "MessageSubnet" ENUM  "LS","MS","HS","CE","PE","HV","FO","S1","HE","LE","HE2","DLCLS","DLCHS","DLCCE","DLCFO";
BA_DEF_ BO_  "GenMsgMandatoryToSupervision" ENUM  "No","Yes","DLCLS","DLCHS","DLCCE","DLCFO";
BA_DEF_ BO_  "DiagState" ENUM  "No","Yes","DLCLS","DLCHS","DLCCE","DLCFO";
BA_DEF_ BO_  "GenMsgStartDelayTime" INT 0 100000;
BA_DEF_ BO_  "GenMsgDelayTime" INT 0 100000;
BA_DEF_ BO_  "GenMsgCycleTime" INT 0 100000;
BA_DEF_ BO_  "GenMsgSendType" ENUM  "cyclicX","spontanX","cyclicIfActiveX","spontanWithDelay","cyclicAndSpontanX","cyclicAndSpontanWithDelay","spontanWithRepitition","cyclicIfActiveAndSpontanWD","DLCLS","DLCHS","DLCCE","DLCFO";
BA_DEF_ BO_  "DiagResponse" ENUM  "No","Yes","DLCLS","DLCHS","DLCCE","DLCFO";
BA_DEF_ BO_  "DiagRequest" ENUM  "No","Yes","DLCLS","DLCHS","DLCCE","DLCFO";
BA_DEF_ BO_  "NmMessage" ENUM  "No","Yes","DLCLS","DLCHS","DLCCE","DLCFO";
BA_DEF_REL_ BU_SG_REL_  "GenSigSuprvRespComment" STRING ;
BA_DEF_REL_ BU_SG_REL_  "GenSigVBitResp" ENUM  "No","Yes","DLCLS","DLCHS","DLCCE","DLCFO";
BA_DEF_REL_ BU_SG_REL_  "GenSigVBitRespComment" STRING ;
BA_DEF_REL_ BU_SG_REL_  "GenSigVDAFailComment" STRING ;
BA_DEF_REL_ BU_SG_REL_  "GenSigVDAFailResp" ENUM  "No","Yes","DLCLS","DLCHS","DLCCE","DLCFO";
BA_DEF_REL_ BU_SG_REL_  "GenSigRxStartValue" STRING ;
BA_DEF_REL_ BU_SG_REL_  "GenSigSuprvRespSubValue" INT 0 65535;
BA_DEF_REL_ BU_SG_REL_  "GenSigSuprvResp" ENUM  "None","Notify App","Substitute Default","DLCLS","DLCHS","DLCCE","DLCFO";
BA_DEF_REL_ BU_SG_REL_  "GenSigTimeoutMsg" HEX -2147483648 268435455;
BA_DEF_REL_ BU_SG_REL_  "GenSigTimeoutTime" INT 0 15000;
BA_DEF_DEF_  "VNSigPrimaryTriggering" "No";
BA_DEF_DEF_  "VNSigRemoteDiagnostics" "No";
BA_DEF_DEF_  "VNSigInfotainment" "No";
BA_DEF_DEF_  "VNSigParkedVehicle" "No";
BA_DEF_DEF_  "VNSigIntermediate" "No";
BA_DEF_DEF_  "VNSigUnused_4" "No";
BA_DEF_DEF_  "SignalType" "";
BA_DEF_DEF_  "PacketOrder" 0;
BA_DEF_DEF_  "SignalLongName" "";
BA_DEF_DEF_  "GenSigStartValue" 0;
BA_DEF_DEF_  "VNSigDiagnostic" "No";
BA_DEF_DEF_  "VNSigAllNodes" "No";
BA_DEF_DEF_  "GenSigDeltaValue" 0;
BA_DEF_DEF_  "GenSigInactiveValue" 0;
BA_DEF_DEF_  "GenSigSendType" "NoSigSendType";
BA_DEF_DEF_  "GenSigSendOnInit" "Not Initialized";
BA_DEF_DEF_  "AppGenMsgCycleTime" 0;
BA_DEF_DEF_  "TpTxIndex" 0;
BA_DEF_DEF_  "GenMsgILSupport" "Yes";
BA_DEF_DEF_  "TpApplType" "";
BA_DEF_DEF_  "Prio" 4;
BA_DEF_DEF_  "MessageSubnet" "FO";
BA_DEF_DEF_  "GenMsgMandatoryToSupervision" "No";
BA_DEF_DEF_  "DiagState" "No";
BA_DEF_DEF_  "GenMsgStartDelayTime" 0;
BA_DEF_DEF_  "GenMsgDelayTime" 0;
BA_DEF_DEF_  "GenMsgCycleTime" 0;
BA_DEF_DEF_  "GenMsgSendType" "spontanX";
BA_DEF_DEF_  "DiagResponse" "No";
BA_DEF_DEF_  "DiagRequest" "No";
BA_DEF_DEF_  "NmMessage" "No";
BA_DEF_DEF_REL_ "GenSigSuprvRespComment" "";
BA_DEF_DEF_REL_ "GenSigVBitResp" "No";
BA_DEF_DEF_REL_ "GenSigVBitRespComment" "";
BA_DEF_DEF_REL_ "GenSigVDAFailComment" "";
BA_DEF_DEF_REL_ "GenSigVDAFailResp" "No";
BA_DEF_DEF_REL_ "GenSigRxStartValue" "";
BA_DEF_DEF_REL_ "GenSigSuprvRespSubValue" 0;
BA_DEF_DEF_REL_ "GenSigSuprvResp" "None";
BA_DEF_DEF_REL_ "GenSigTimeoutMsg" 0;
BA_DEF_DEF_REL_ "GenSigTimeoutTime" 0;
BA_ "MessageSubnet" BO_ 2152775680 0;
BA_ "GenMsgDelayTime" BO_ 2152775680 100;
BA_ "MessageSubnet" BO_ 2153857024 0;
BA_ "GenMsgDelayTime" BO_ 2153857024 100;
BA_ "MessageSubnet" BO_ 2153865216 0;
BA_ "GenMsgDelayTime" BO_ 2153865216 100;
BA_ "MessageSubnet" BO_ 2153840640 0;
BA_ "GenMsgDelayTime" BO_ 2153840640 100;
BA_ "MessageSubnet" BO_ 2153824256 0;
BA_ "GenMsgDelayTime" BO_ 2153824256 100;
BA_ "MessageSubnet" BO_ 2155151360 0;
BA_ "GenMsgDelayTime" BO_ 2155151360 100;
BA_ "MessageSubnet" BO_ 2155134976 0;
BA_ "GenMsgDelayTime" BO_ 2155134976 100;
BA_ "MessageSubnet" BO_ 2155118592 0;
BA_ "GenMsgDelayTime" BO_ 2155118592 100;
BA_ "MessageSubnet" BO_ 2155102208 0;
BA_ "GenMsgDelayTime" BO_ 2155102208 100;
BA_ "MessageSubnet" BO_ 2155085824 0;
BA_ "GenMsgDelayTime" BO_ 2155085824 100;
BA_ "MessageSubnet" BO_ 2155069440 0;
BA_ "GenMsgDelayTime" BO_ 2155069440 100;
BA_ "MessageSubnet" BO_ 2156937216 0;
BA_ "GenMsgDelayTime" BO_ 2156937216 100;
BA_ "MessageSubnet" BO_ 2156929024 0;
BA_ "GenMsgDelayTime" BO_ 2156929024 100;
BA_ "MessageSubnet" BO_ 2156920832 0;
BA_ "GenMsgDelayTime" BO_ 2156920832 100;
BA_ "MessageSubnet" BO_ 2156871680 0;
BA_ "GenMsgDelayTime" BO_ 2156871680 100;
BA_ "MessageSubnet" BO_ 2156863488 0;
BA_ "GenMsgDelayTime" BO_ 2156863488 100;
BA_ "MessageSubnet" BO_ 2156855296 0;
BA_ "GenMsgDelayTime" BO_ 2156855296 100;
BA_ "MessageSubnet" BO_ 2152480768 0;
BA_ "GenMsgDelayTime" BO_ 2152480768 1000;
BA_ "MessageSubnet" BO_ 2152497152 0;
BA_ "GenMsgDelayTime" BO_ 2152497152 1000;
BA_ "GenMsgCycleTime" BO_ 2152497152 1000;
BA_ "GenMsgSendType" BO_ 2152497152 0;
BA_ "MessageSubnet" BO_ 2153791488 0;
BA_ "GenMsgDelayTime" BO_ 2153791488 100;
BA_ "MessageSubnet" BO_ 2149883904 0;
BA_ "GenMsgDelayTime" BO_ 2149883904 100;
BA_ "MessageSubnet" BO_ 2150252544 0;
BA_ "GenMsgDelayTime" BO_ 2150252544 100;
BA_ "MessageSubnet" BO_ 2150391808 0;
BA_ "GenMsgDelayTime" BO_ 2150391808 100;
BA_ "MessageSubnet" BO_ 2155913216 0;
BA_ "GenMsgCycleTime" BO_ 2155913216 1000;
BA_ "GenMsgSendType" BO_ 2155913216 0;
BA_ "Prio" BO_ 2034 0;
BA_ "MessageSubnet" BO_ 2034 0;
BA_ "DiagResponse" BO_ 2034 1;
BA_ "Prio" BO_ 2032 0;
BA_ "MessageSubnet" BO_ 2032 0;
BA_ "DiagRequest" BO_ 2032 1;
BA_ "MessageSubnet" BO_ 2152095744 0;
BA_ "GenMsgStartDelayTime" BO_ 2152095744 120;
BA_ "GenMsgCycleTime" BO_ 2152095744 2000;
BA_ "GenMsgSendType" BO_ 2152095744 0;
BA_ "MessageSubnet" BO_ 2156945408 0;
BA_ "GenMsgDelayTime" BO_ 2156945408 100;
BA_ "MessageSubnet" BO_ 2152611840 0;
BA_ "GenMsgDelayTime" BO_ 2152611840 100;
BA_ "GenMsgCycleTime" BO_ 2152611840 3000;
BA_ "GenMsgSendType" BO_ 2152611840 0;
BA_ "MessageSubnet" BO_ 2153308160 0;
BA_ "GenMsgStartDelayTime" BO_ 2153308160 100;
BA_ "GenMsgCycleTime" BO_ 2153308160 1000;
BA_ "GenMsgSendType" BO_ 2153308160 0;
BA_ "MessageSubnet" BO_ 2155970560 0;
BA_ "GenMsgDelayTime" BO_ 2155970560 100;
BA_ "MessageSubnet" BO_ 2151178240 0;
BA_ "GenMsgDelayTime" BO_ 2151178240 100;
BA_ "MessageSubnet" BO_ 2154790912 0;
BA_ "GenMsgDelayTime" BO_ 2154790912 100;
BA_ "GenSigSendType" SG_ 2152775680 CrgBdVwLtCustSetVal 10;
BA_ "GenSigSendOnInit" SG_ 2152775680 CrgBdVwLtCustSetVal 2;
BA_ "SignalType" SG_ 2152775680 CrgBdVwLtCustSetVal "ENM";
BA_ "SignalLongName" SG_ 2152775680 CrgBdVwLtCustSetVal "Cargo Bed View Auto Lighting Customization Current Setting Value";
BA_ "VNSigAllNodes" SG_ 2152775680 CrgBdVwLtCustSetVal 1;
BA_ "GenSigSendType" SG_ 2152775680 CrgBdVwLtCustSetAvl 10;
BA_ "GenSigSendOnInit" SG_ 2152775680 CrgBdVwLtCustSetAvl 2;
BA_ "SignalType" SG_ 2152775680 CrgBdVwLtCustSetAvl "BLN";
BA_ "SignalLongName" SG_ 2152775680 CrgBdVwLtCustSetAvl "Cargo Bed View Auto Lighting Customization Setting Available";
BA_ "VNSigAllNodes" SG_ 2152775680 CrgBdVwLtCustSetAvl 1;
BA_ "GenSigSendType" SG_ 2152775680 TrlrMirVGlnCustSetVal 10;
BA_ "GenSigSendOnInit" SG_ 2152775680 TrlrMirVGlnCustSetVal 2;
BA_ "SignalType" SG_ 2152775680 TrlrMirVGlnCustSetVal "ENM";
BA_ "SignalLongName" SG_ 2152775680 TrlrMirVGlnCustSetVal "Trailering Mirror Video Guidelines Customization Current Setting Value";
BA_ "VNSigAllNodes" SG_ 2152775680 TrlrMirVGlnCustSetVal 1;
BA_ "GenSigSendType" SG_ 2152775680 TrlrMirVGlnCustSetAvl 10;
BA_ "GenSigSendOnInit" SG_ 2152775680 TrlrMirVGlnCustSetAvl 2;
BA_ "SignalType" SG_ 2152775680 TrlrMirVGlnCustSetAvl "BLN";
BA_ "SignalLongName" SG_ 2152775680 TrlrMirVGlnCustSetAvl "Trailering Mirror Video Guidelines Customization Setting Available";
BA_ "VNSigAllNodes" SG_ 2152775680 TrlrMirVGlnCustSetAvl 1;
BA_ "GenSigSendType" SG_ 2152775680 TrlrMirVEnCustSetVal 10;
BA_ "GenSigSendOnInit" SG_ 2152775680 TrlrMirVEnCustSetVal 2;
BA_ "SignalType" SG_ 2152775680 TrlrMirVEnCustSetVal "ENM";
BA_ "SignalLongName" SG_ 2152775680 TrlrMirVEnCustSetVal "Trailering Mirror Video Enable Customization Current Setting Value";
BA_ "VNSigAllNodes" SG_ 2152775680 TrlrMirVEnCustSetVal 1;
BA_ "GenSigSendType" SG_ 2152775680 TrlrMirVEnCustSetAvl 10;
BA_ "GenSigSendOnInit" SG_ 2152775680 TrlrMirVEnCustSetAvl 2;
BA_ "SignalType" SG_ 2152775680 TrlrMirVEnCustSetAvl "BLN";
BA_ "SignalLongName" SG_ 2152775680 TrlrMirVEnCustSetAvl "Trailering Mirror Video Enable Customization Setting Available";
BA_ "VNSigAllNodes" SG_ 2152775680 TrlrMirVEnCustSetAvl 1;
BA_ "GenSigSendType" SG_ 2152775680 TrlrArtcltnAnglCalStat 10;
BA_ "SignalType" SG_ 2152775680 TrlrArtcltnAnglCalStat "ENM";
BA_ "SignalLongName" SG_ 2152775680 TrlrArtcltnAnglCalStat "Trailer Articulation Angle Calibration Status";
BA_ "VNSigAllNodes" SG_ 2152775680 TrlrArtcltnAnglCalStat 1;
BA_ "GenSigSendType" SG_ 2152775680 InvTrlrAx1CamRollAlgnd 10;
BA_ "SignalType" SG_ 2152775680 InvTrlrAx1CamRollAlgnd "BLN";
BA_ "SignalLongName" SG_ 2152775680 InvTrlrAx1CamRollAlgnd "Invisible Trailer Aux1 Camera Roll Aligned";
BA_ "VNSigAllNodes" SG_ 2152775680 InvTrlrAx1CamRollAlgnd 1;
BA_ "GenSigSendType" SG_ 2152775680 InvTrlrAx1CamPtchAlgnd 10;
BA_ "SignalType" SG_ 2152775680 InvTrlrAx1CamPtchAlgnd "BLN";
BA_ "SignalLongName" SG_ 2152775680 InvTrlrAx1CamPtchAlgnd "Invisible Trailer Aux1 Camera Pitch Aligned";
BA_ "VNSigAllNodes" SG_ 2152775680 InvTrlrAx1CamPtchAlgnd 1;
BA_ "GenSigSendType" SG_ 2152775680 InvTrlrAx1CamYAlgnd 10;
BA_ "SignalType" SG_ 2152775680 InvTrlrAx1CamYAlgnd "BLN";
BA_ "SignalLongName" SG_ 2152775680 InvTrlrAx1CamYAlgnd "Invisible Trailer Aux1 Camera Y Aligned";
BA_ "VNSigAllNodes" SG_ 2152775680 InvTrlrAx1CamYAlgnd 1;
BA_ "GenSigSendType" SG_ 2152775680 InvTrlrAx1CamXAlgnd 10;
BA_ "SignalType" SG_ 2152775680 InvTrlrAx1CamXAlgnd "BLN";
BA_ "SignalLongName" SG_ 2152775680 InvTrlrAx1CamXAlgnd "Invisible Trailer Aux1 Camera X Aligned";
BA_ "VNSigAllNodes" SG_ 2152775680 InvTrlrAx1CamXAlgnd 1;
BA_ "GenSigSendType" SG_ 2152775680 RPDCA_Resrv3Avail 10;
BA_ "GenSigSendOnInit" SG_ 2152775680 RPDCA_Resrv3Avail 2;
BA_ "SignalType" SG_ 2152775680 RPDCA_Resrv3Avail "BLN";
BA_ "PacketOrder" SG_ 2152775680 RPDCA_Resrv3Avail 7;
BA_ "SignalLongName" SG_ 2152775680 RPDCA_Resrv3Avail "Rear Pedestrian Detection Customization Available : Reserved3 Available";
BA_ "VNSigAllNodes" SG_ 2152775680 RPDCA_Resrv3Avail 1;
BA_ "GenSigSendType" SG_ 2152775680 RPDCA_Resrv2Avail 10;
BA_ "GenSigSendOnInit" SG_ 2152775680 RPDCA_Resrv2Avail 2;
BA_ "SignalType" SG_ 2152775680 RPDCA_Resrv2Avail "BLN";
BA_ "PacketOrder" SG_ 2152775680 RPDCA_Resrv2Avail 6;
BA_ "SignalLongName" SG_ 2152775680 RPDCA_Resrv2Avail "Rear Pedestrian Detection Customization Available : Reserved2 Available";
BA_ "VNSigAllNodes" SG_ 2152775680 RPDCA_Resrv2Avail 1;
BA_ "GenSigSendType" SG_ 2152775680 RPDCA_Resrv1Avail 10;
BA_ "GenSigSendOnInit" SG_ 2152775680 RPDCA_Resrv1Avail 2;
BA_ "SignalType" SG_ 2152775680 RPDCA_Resrv1Avail "BLN";
BA_ "PacketOrder" SG_ 2152775680 RPDCA_Resrv1Avail 5;
BA_ "SignalLongName" SG_ 2152775680 RPDCA_Resrv1Avail "Rear Pedestrian Detection Customization Available : Reserved1 Available";
BA_ "VNSigAllNodes" SG_ 2152775680 RPDCA_Resrv1Avail 1;
BA_ "GenSigSendType" SG_ 2152775680 RPDCA_AlrtBrkAvail 10;
BA_ "GenSigSendOnInit" SG_ 2152775680 RPDCA_AlrtBrkAvail 2;
BA_ "PacketOrder" SG_ 2152775680 RPDCA_AlrtBrkAvail 4;
BA_ "SignalType" SG_ 2152775680 RPDCA_AlrtBrkAvail "BLN";
BA_ "SignalLongName" SG_ 2152775680 RPDCA_AlrtBrkAvail "Rear Pedestrian Detection Customization Available : Alert and Brake Available";
BA_ "VNSigAllNodes" SG_ 2152775680 RPDCA_AlrtBrkAvail 1;
BA_ "GenSigSendType" SG_ 2152775680 RPDCA_AlrtAvail 10;
BA_ "GenSigSendOnInit" SG_ 2152775680 RPDCA_AlrtAvail 2;
BA_ "PacketOrder" SG_ 2152775680 RPDCA_AlrtAvail 3;
BA_ "SignalType" SG_ 2152775680 RPDCA_AlrtAvail "BLN";
BA_ "SignalLongName" SG_ 2152775680 RPDCA_AlrtAvail "Rear Pedestrian Detection Customization Available : Alert Available";
BA_ "VNSigAllNodes" SG_ 2152775680 RPDCA_AlrtAvail 1;
BA_ "GenSigSendType" SG_ 2152775680 RPDCA_OnAvail 10;
BA_ "GenSigSendOnInit" SG_ 2152775680 RPDCA_OnAvail 2;
BA_ "SignalType" SG_ 2152775680 RPDCA_OnAvail "BLN";
BA_ "PacketOrder" SG_ 2152775680 RPDCA_OnAvail 2;
BA_ "SignalLongName" SG_ 2152775680 RPDCA_OnAvail "Rear Pedestrian Detection Customization Available : On Available";
BA_ "GenSigStartValue" SG_ 2152775680 RPDCA_OnAvail 1;
BA_ "VNSigAllNodes" SG_ 2152775680 RPDCA_OnAvail 1;
BA_ "GenSigSendType" SG_ 2152775680 RPDCA_OfAvail 10;
BA_ "GenSigSendOnInit" SG_ 2152775680 RPDCA_OfAvail 2;
BA_ "SignalType" SG_ 2152775680 RPDCA_OfAvail "BLN";
BA_ "PacketOrder" SG_ 2152775680 RPDCA_OfAvail 1;
BA_ "SignalLongName" SG_ 2152775680 RPDCA_OfAvail "Rear Pedestrian Detection Customization Available : Off Available";
BA_ "GenSigStartValue" SG_ 2152775680 RPDCA_OfAvail 1;
BA_ "VNSigAllNodes" SG_ 2152775680 RPDCA_OfAvail 1;
BA_ "GenSigDeltaValue" SG_ 2152775680 JacknfDetRHapSReqSN 1;
BA_ "GenSigSendType" SG_ 2152775680 JacknfDetRHapSReqSN 12;
BA_ "GenSigSendOnInit" SG_ 2152775680 JacknfDetRHapSReqSN 2;
BA_ "SignalType" SG_ 2152775680 JacknfDetRHapSReqSN "UNM";
BA_ "SignalLongName" SG_ 2152775680 JacknfDetRHapSReqSN "Jack Knife Detection Right Haptic Seat Request Sequence Number";
BA_ "VNSigAllNodes" SG_ 2152775680 JacknfDetRHapSReqSN 1;
BA_ "GenSigDeltaValue" SG_ 2152775680 JacknfDetRHapSReq 1;
BA_ "GenSigSendType" SG_ 2152775680 JacknfDetRHapSReq 12;
BA_ "GenSigSendOnInit" SG_ 2152775680 JacknfDetRHapSReq 2;
BA_ "SignalType" SG_ 2152775680 JacknfDetRHapSReq "UNM";
BA_ "SignalLongName" SG_ 2152775680 JacknfDetRHapSReq "Jack Knife Detection Right Haptic Seat Request";
BA_ "VNSigAllNodes" SG_ 2152775680 JacknfDetRHapSReq 1;
BA_ "GenSigDeltaValue" SG_ 2152775680 JacknfDetLHapSReqSN 1;
BA_ "GenSigSendType" SG_ 2152775680 JacknfDetLHapSReqSN 12;
BA_ "GenSigSendOnInit" SG_ 2152775680 JacknfDetLHapSReqSN 2;
BA_ "SignalType" SG_ 2152775680 JacknfDetLHapSReqSN "UNM";
BA_ "SignalLongName" SG_ 2152775680 JacknfDetLHapSReqSN "Jack Knife Detection Left Haptic Seat Request Sequence Number";
BA_ "VNSigAllNodes" SG_ 2152775680 JacknfDetLHapSReqSN 1;
BA_ "GenSigDeltaValue" SG_ 2152775680 JacknfDetLHapSReq 1;
BA_ "GenSigSendType" SG_ 2152775680 JacknfDetLHapSReq 12;
BA_ "GenSigSendOnInit" SG_ 2152775680 JacknfDetLHapSReq 2;
BA_ "SignalType" SG_ 2152775680 JacknfDetLHapSReq "UNM";
BA_ "SignalLongName" SG_ 2152775680 JacknfDetLHapSReq "Jack Knife Detection Left Haptic Seat Request";
BA_ "VNSigAllNodes" SG_ 2152775680 JacknfDetLHapSReq 1;
BA_ "GenSigSendType" SG_ 2152775680 JacknfDetCustSetVal 10;
BA_ "GenSigSendOnInit" SG_ 2152775680 JacknfDetCustSetVal 2;
BA_ "SignalType" SG_ 2152775680 JacknfDetCustSetVal "ENM";
BA_ "SignalLongName" SG_ 2152775680 JacknfDetCustSetVal "Jack Knife Detection Customization Current Setting Value";
BA_ "VNSigAllNodes" SG_ 2152775680 JacknfDetCustSetVal 1;
BA_ "GenSigSendType" SG_ 2152775680 JacknfDetCustSetAvl 10;
BA_ "GenSigSendOnInit" SG_ 2152775680 JacknfDetCustSetAvl 2;
BA_ "SignalType" SG_ 2152775680 JacknfDetCustSetAvl "BLN";
BA_ "SignalLongName" SG_ 2152775680 JacknfDetCustSetAvl "Jack Knife Detection Customization Setting Available";
BA_ "VNSigAllNodes" SG_ 2152775680 JacknfDetCustSetAvl 1;
BA_ "GenSigSendType" SG_ 2152775680 DispTrgdVidOn 10;
BA_ "GenSigSendOnInit" SG_ 2152775680 DispTrgdVidOn 2;
BA_ "SignalType" SG_ 2152775680 DispTrgdVidOn "BLN";
BA_ "SignalLongName" SG_ 2152775680 DispTrgdVidOn "Display Triggered Video On";
BA_ "VNSigAllNodes" SG_ 2152775680 DispTrgdVidOn 1;
BA_ "GenSigSendType" SG_ 2152775680 a_360DegVidFetrPrsnt 10;
BA_ "GenSigSendOnInit" SG_ 2152775680 a_360DegVidFetrPrsnt 2;
BA_ "SignalType" SG_ 2152775680 a_360DegVidFetrPrsnt "BLN";
BA_ "SignalLongName" SG_ 2152775680 a_360DegVidFetrPrsnt "360 Degree Video Feature Present";
BA_ "VNSigAllNodes" SG_ 2152775680 a_360DegVidFetrPrsnt 1;
BA_ "GenSigSendType" SG_ 2152775680 TrgdVidRecFetrPrsnt 10;
BA_ "GenSigSendOnInit" SG_ 2152775680 TrgdVidRecFetrPrsnt 2;
BA_ "SignalType" SG_ 2152775680 TrgdVidRecFetrPrsnt "BLN";
BA_ "SignalLongName" SG_ 2152775680 TrgdVidRecFetrPrsnt "Triggered Video Recorder Feature Present";
BA_ "VNSigAllNodes" SG_ 2152775680 TrgdVidRecFetrPrsnt 1;
BA_ "GenSigDeltaValue" SG_ 2152775680 RrPdDetHptcStVbRq 1;
BA_ "GenSigSendType" SG_ 2152775680 RrPdDetHptcStVbRq 12;
BA_ "SignalType" SG_ 2152775680 RrPdDetHptcStVbRq "UNM";
BA_ "SignalLongName" SG_ 2152775680 RrPdDetHptcStVbRq "Rear Pedestrian Detection Haptic Seat Vibration Request";
BA_ "VNSigAllNodes" SG_ 2152775680 RrPdDetHptcStVbRq 1;
BA_ "GenSigDeltaValue" SG_ 2152775680 RrPdDetHptcStVbRqSeqN 1;
BA_ "GenSigSendType" SG_ 2152775680 RrPdDetHptcStVbRqSeqN 12;
BA_ "SignalType" SG_ 2152775680 RrPdDetHptcStVbRqSeqN "UNM";
BA_ "SignalLongName" SG_ 2152775680 RrPdDetHptcStVbRqSeqN "Rear Pedestrian Detection Haptic Seat Vibration Request Sequence Number";
BA_ "VNSigAllNodes" SG_ 2152775680 RrPdDetHptcStVbRqSeqN 1;
BA_ "GenSigSendType" SG_ 2152775680 RrPedDetCstStVal 10;
BA_ "GenSigSendOnInit" SG_ 2152775680 RrPedDetCstStVal 2;
BA_ "SignalType" SG_ 2152775680 RrPedDetCstStVal "ENM";
BA_ "SignalLongName" SG_ 2152775680 RrPedDetCstStVal "Rear Pedestrian Detection Customization Current Setting Value";
BA_ "VNSigAllNodes" SG_ 2152775680 RrPedDetCstStVal 1;
BA_ "GenSigSendType" SG_ 2152775680 RrPedDetCstStAvl 10;
BA_ "GenSigSendOnInit" SG_ 2152775680 RrPedDetCstStAvl 2;
BA_ "SignalType" SG_ 2152775680 RrPedDetCstStAvl "BLN";
BA_ "SignalLongName" SG_ 2152775680 RrPedDetCstStAvl "Rear Pedestrian Detection Customization Setting Available";
BA_ "VNSigAllNodes" SG_ 2152775680 RrPedDetCstStAvl 1;
BA_ "GenSigSendType" SG_ 2152775680 PudlLmpReqstd 10;
BA_ "SignalType" SG_ 2152775680 PudlLmpReqstd "BLN";
BA_ "SignalLongName" SG_ 2152775680 PudlLmpReqstd "Puddle Lamp Requested";
BA_ "VNSigAllNodes" SG_ 2152775680 PudlLmpReqstd 1;
BA_ "GenSigSendType" SG_ 2152775680 SurdVwLightgCsCurrSetVal 10;
BA_ "GenSigSendOnInit" SG_ 2152775680 SurdVwLightgCsCurrSetVal 2;
BA_ "SignalType" SG_ 2152775680 SurdVwLightgCsCurrSetVal "ENM";
BA_ "SignalLongName" SG_ 2152775680 SurdVwLightgCsCurrSetVal "Surround View Lighting Customization Current Setting Value";
BA_ "VNSigAllNodes" SG_ 2152775680 SurdVwLightgCsCurrSetVal 1;
BA_ "GenSigSendType" SG_ 2152775680 DispSmrtTwVidOn 10;
BA_ "GenSigSendOnInit" SG_ 2152775680 DispSmrtTwVidOn 2;
BA_ "SignalType" SG_ 2152775680 DispSmrtTwVidOn "BLN";
BA_ "SignalLongName" SG_ 2152775680 DispSmrtTwVidOn "Display Smart Tow Video On";
BA_ "VNSigAllNodes" SG_ 2152775680 DispSmrtTwVidOn 1;
BA_ "GenSigSendType" SG_ 2152775680 DispFrt360CamOn 10;
BA_ "GenSigSendOnInit" SG_ 2152775680 DispFrt360CamOn 2;
BA_ "SignalType" SG_ 2152775680 DispFrt360CamOn "BLN";
BA_ "SignalLongName" SG_ 2152775680 DispFrt360CamOn "Display Front 360 Camera On";
BA_ "VNSigAllNodes" SG_ 2152775680 DispFrt360CamOn 1;
BA_ "GenSigSendType" SG_ 2152775680 SurdVwLightgCsSetAvail 10;
BA_ "GenSigSendOnInit" SG_ 2152775680 SurdVwLightgCsSetAvail 2;
BA_ "SignalType" SG_ 2152775680 SurdVwLightgCsSetAvail "BLN";
BA_ "SignalLongName" SG_ 2152775680 SurdVwLightgCsSetAvail "Surround View Lighting Customization Setting Available";
BA_ "VNSigAllNodes" SG_ 2152775680 SurdVwLightgCsSetAvail 1;
BA_ "GenSigDeltaValue" SG_ 2153857024 TnDrvTrCtrlEvntsRpt 1;
BA_ "GenSigSendType" SG_ 2153857024 TnDrvTrCtrlEvntsRpt 12;
BA_ "GenSigSendOnInit" SG_ 2153857024 TnDrvTrCtrlEvntsRpt 2;
BA_ "SignalType" SG_ 2153857024 TnDrvTrCtrlEvntsRpt "UNM";
BA_ "SignalLongName" SG_ 2153857024 TnDrvTrCtrlEvntsRpt "Teen Driver Traction Control Events Report";
BA_ "VNSigAllNodes" SG_ 2153857024 TnDrvTrCtrlEvntsRpt 1;
BA_ "GenSigDeltaValue" SG_ 2153857024 TnDrvDrowDrvAlrtsRpt 1;
BA_ "GenSigSendType" SG_ 2153857024 TnDrvDrowDrvAlrtsRpt 12;
BA_ "GenSigSendOnInit" SG_ 2153857024 TnDrvDrowDrvAlrtsRpt 2;
BA_ "SignalType" SG_ 2153857024 TnDrvDrowDrvAlrtsRpt "UNM";
BA_ "SignalLongName" SG_ 2153857024 TnDrvDrowDrvAlrtsRpt "Teen Driver Drowsy Driver Alerts Report";
BA_ "VNSigAllNodes" SG_ 2153857024 TnDrvDrowDrvAlrtsRpt 1;
BA_ "GenSigSendType" SG_ 2153857024 TDRCADD_WOTEvnts 10;
BA_ "GenSigSendOnInit" SG_ 2153857024 TDRCADD_WOTEvnts 2;
BA_ "SignalType" SG_ 2153857024 TDRCADD_WOTEvnts "BLN";
BA_ "PacketOrder" SG_ 2153857024 TDRCADD_WOTEvnts 12;
BA_ "SignalLongName" SG_ 2153857024 TDRCADD_WOTEvnts "Teen Driver Report Card Available Display Data : Wide Open Throttle Events";
BA_ "VNSigAllNodes" SG_ 2153857024 TDRCADD_WOTEvnts 1;
BA_ "GenSigSendType" SG_ 2153857024 TDRCADD_LDWEvnts 10;
BA_ "GenSigSendOnInit" SG_ 2153857024 TDRCADD_LDWEvnts 2;
BA_ "SignalType" SG_ 2153857024 TDRCADD_LDWEvnts "BLN";
BA_ "PacketOrder" SG_ 2153857024 TDRCADD_LDWEvnts 13;
BA_ "SignalLongName" SG_ 2153857024 TDRCADD_LDWEvnts "Teen Driver Report Card Available Display Data : Lane Departure Warning Events";
BA_ "VNSigAllNodes" SG_ 2153857024 TDRCADD_LDWEvnts 1;
BA_ "GenSigSendType" SG_ 2153857024 TDRCADD_FCMBrEvts 10;
BA_ "GenSigSendOnInit" SG_ 2153857024 TDRCADD_FCMBrEvts 2;
BA_ "SignalType" SG_ 2153857024 TDRCADD_FCMBrEvts "BLN";
BA_ "PacketOrder" SG_ 2153857024 TDRCADD_FCMBrEvts 10;
BA_ "SignalLongName" SG_ 2153857024 TDRCADD_FCMBrEvts "Teen Driver Report Card Available Display Data : Forward Collision Mitigation Braking Events";
BA_ "VNSigAllNodes" SG_ 2153857024 TDRCADD_FCMBrEvts 1;
BA_ "GenSigSendType" SG_ 2153857024 TDRCADD_DrwDrvAlrt 10;
BA_ "GenSigSendOnInit" SG_ 2153857024 TDRCADD_DrwDrvAlrt 2;
BA_ "SignalType" SG_ 2153857024 TDRCADD_DrwDrvAlrt "BLN";
BA_ "PacketOrder" SG_ 2153857024 TDRCADD_DrwDrvAlrt 11;
BA_ "SignalLongName" SG_ 2153857024 TDRCADD_DrwDrvAlrt "Teen Driver Report Card Available Display Data : Drowsy Driver Alerts";
BA_ "VNSigAllNodes" SG_ 2153857024 TDRCADD_DrwDrvAlrt 1;
BA_ "GenSigSendType" SG_ 2153857024 TDRCADD_RCMBrEvts 10;
BA_ "GenSigSendOnInit" SG_ 2153857024 TDRCADD_RCMBrEvts 2;
BA_ "SignalType" SG_ 2153857024 TDRCADD_RCMBrEvts "BLN";
BA_ "PacketOrder" SG_ 2153857024 TDRCADD_RCMBrEvts 9;
BA_ "SignalLongName" SG_ 2153857024 TDRCADD_RCMBrEvts "Teen Driver Report Card Available Display Data : Reverse Collision Mitigation Braking Events";
BA_ "VNSigAllNodes" SG_ 2153857024 TDRCADD_RCMBrEvts 1;
BA_ "GenSigSendType" SG_ 2153857024 TDRCADD_FCImntAlrts 10;
BA_ "GenSigSendOnInit" SG_ 2153857024 TDRCADD_FCImntAlrts 2;
BA_ "SignalType" SG_ 2153857024 TDRCADD_FCImntAlrts "BLN";
BA_ "PacketOrder" SG_ 2153857024 TDRCADD_FCImntAlrts 8;
BA_ "SignalLongName" SG_ 2153857024 TDRCADD_FCImntAlrts "Teen Driver Report Card Available Display Data : Forward Collision Imminent Alerts";
BA_ "VNSigAllNodes" SG_ 2153857024 TDRCADD_FCImntAlrts 1;
BA_ "GenSigSendType" SG_ 2153857024 TDRCADD_FCHdwyAlrt 10;
BA_ "GenSigSendOnInit" SG_ 2153857024 TDRCADD_FCHdwyAlrt 2;
BA_ "SignalType" SG_ 2153857024 TDRCADD_FCHdwyAlrt "BLN";
BA_ "PacketOrder" SG_ 2153857024 TDRCADD_FCHdwyAlrt 7;
BA_ "SignalLongName" SG_ 2153857024 TDRCADD_FCHdwyAlrt "Teen Driver Report Card Available Display Data : Forward Collision Headway Alerts";
BA_ "VNSigAllNodes" SG_ 2153857024 TDRCADD_FCHdwyAlrt 1;
BA_ "GenSigSendType" SG_ 2153857024 TDRCADD_StCtrlEvnts 10;
BA_ "GenSigSendOnInit" SG_ 2153857024 TDRCADD_StCtrlEvnts 2;
BA_ "SignalType" SG_ 2153857024 TDRCADD_StCtrlEvnts "BLN";
BA_ "PacketOrder" SG_ 2153857024 TDRCADD_StCtrlEvnts 5;
BA_ "SignalLongName" SG_ 2153857024 TDRCADD_StCtrlEvnts "Teen Driver Report Card Available Display Data : Stability Control Events";
BA_ "VNSigAllNodes" SG_ 2153857024 TDRCADD_StCtrlEvnts 1;
BA_ "GenSigSendType" SG_ 2153857024 TDRCADD_ABSAtvEvt 10;
BA_ "GenSigSendOnInit" SG_ 2153857024 TDRCADD_ABSAtvEvt 2;
BA_ "SignalType" SG_ 2153857024 TDRCADD_ABSAtvEvt "BLN";
BA_ "PacketOrder" SG_ 2153857024 TDRCADD_ABSAtvEvt 6;
BA_ "SignalLongName" SG_ 2153857024 TDRCADD_ABSAtvEvt "Teen Driver Report Card Available Display Data : Antilock Braking System Active Events";
BA_ "VNSigAllNodes" SG_ 2153857024 TDRCADD_ABSAtvEvt 1;
BA_ "GenSigSendType" SG_ 2153857024 TDRCADD_TrCtrlEvnts 10;
BA_ "GenSigSendOnInit" SG_ 2153857024 TDRCADD_TrCtrlEvnts 2;
BA_ "SignalType" SG_ 2153857024 TDRCADD_TrCtrlEvnts "BLN";
BA_ "PacketOrder" SG_ 2153857024 TDRCADD_TrCtrlEvnts 4;
BA_ "SignalLongName" SG_ 2153857024 TDRCADD_TrCtrlEvnts "Teen Driver Report Card Available Display Data : Traction Control Events";
BA_ "VNSigAllNodes" SG_ 2153857024 TDRCADD_TrCtrlEvnts 1;
BA_ "GenSigSendType" SG_ 2153857024 TDRCADD_OvSpdEvnt 10;
BA_ "GenSigSendOnInit" SG_ 2153857024 TDRCADD_OvSpdEvnt 2;
BA_ "SignalType" SG_ 2153857024 TDRCADD_OvSpdEvnt "BLN";
BA_ "PacketOrder" SG_ 2153857024 TDRCADD_OvSpdEvnt 3;
BA_ "SignalLongName" SG_ 2153857024 TDRCADD_OvSpdEvnt "Teen Driver Report Card Available Display Data : Overspeed Events";
BA_ "VNSigAllNodes" SG_ 2153857024 TDRCADD_OvSpdEvnt 1;
BA_ "GenSigSendType" SG_ 2153857024 TDRCADD_DistDrvn 10;
BA_ "GenSigSendOnInit" SG_ 2153857024 TDRCADD_DistDrvn 2;
BA_ "SignalType" SG_ 2153857024 TDRCADD_DistDrvn "BLN";
BA_ "PacketOrder" SG_ 2153857024 TDRCADD_DistDrvn 2;
BA_ "SignalLongName" SG_ 2153857024 TDRCADD_DistDrvn "Teen Driver Report Card Available Display Data : Distance Driven";
BA_ "VNSigAllNodes" SG_ 2153857024 TDRCADD_DistDrvn 1;
BA_ "GenSigSendType" SG_ 2153857024 TDRCADD_MaxSpd 10;
BA_ "GenSigSendOnInit" SG_ 2153857024 TDRCADD_MaxSpd 2;
BA_ "SignalType" SG_ 2153857024 TDRCADD_MaxSpd "BLN";
BA_ "PacketOrder" SG_ 2153857024 TDRCADD_MaxSpd 1;
BA_ "SignalLongName" SG_ 2153857024 TDRCADD_MaxSpd "Teen Driver Report Card Available Display Data : Maximum Speed";
BA_ "VNSigAllNodes" SG_ 2153857024 TDRCADD_MaxSpd 1;
BA_ "GenSigDeltaValue" SG_ 2153857024 TnDrvStblCtrlEvntsRpt 1;
BA_ "GenSigSendType" SG_ 2153857024 TnDrvStblCtrlEvntsRpt 12;
BA_ "GenSigSendOnInit" SG_ 2153857024 TnDrvStblCtrlEvntsRpt 2;
BA_ "SignalType" SG_ 2153857024 TnDrvStblCtrlEvntsRpt "UNM";
BA_ "SignalLongName" SG_ 2153857024 TnDrvStblCtrlEvntsRpt "Teen Driver Stability Control Events Report";
BA_ "VNSigAllNodes" SG_ 2153857024 TnDrvStblCtrlEvntsRpt 1;
BA_ "GenSigDeltaValue" SG_ 2153857024 TnDrvABSAtvEvntsRpt 1;
BA_ "GenSigSendType" SG_ 2153857024 TnDrvABSAtvEvntsRpt 12;
BA_ "GenSigSendOnInit" SG_ 2153857024 TnDrvABSAtvEvntsRpt 2;
BA_ "SignalType" SG_ 2153857024 TnDrvABSAtvEvntsRpt "UNM";
BA_ "SignalLongName" SG_ 2153857024 TnDrvABSAtvEvntsRpt "Teen Driver Antilock Brake System Active Events Report";
BA_ "VNSigAllNodes" SG_ 2153857024 TnDrvABSAtvEvntsRpt 1;
BA_ "GenSigDeltaValue" SG_ 2153857024 TeenDrvWOTEvntsRpt 1;
BA_ "GenSigSendType" SG_ 2153857024 TeenDrvWOTEvntsRpt 12;
BA_ "GenSigSendOnInit" SG_ 2153857024 TeenDrvWOTEvntsRpt 2;
BA_ "SignalType" SG_ 2153857024 TeenDrvWOTEvntsRpt "UNM";
BA_ "SignalLongName" SG_ 2153857024 TeenDrvWOTEvntsRpt "Teen Driver Wide Open Throttle Events Report";
BA_ "VNSigAllNodes" SG_ 2153857024 TeenDrvWOTEvntsRpt 1;
BA_ "GenSigSendType" SG_ 2153865216 TnDrvStBltShftIntrlkCsStRq 10;
BA_ "SignalType" SG_ 2153865216 TnDrvStBltShftIntrlkCsStRq "ENM";
BA_ "SignalLongName" SG_ 2153865216 TnDrvStBltShftIntrlkCsStRq "Teen Driver Seat Belt Shift Interlock Customization Setting Request";
BA_ "VNSigAllNodes" SG_ 2153865216 TnDrvStBltShftIntrlkCsStRq 1;
BA_ "GenSigSendType" SG_ 2153865216 StBltShftIntrlkCsStRq 10;
BA_ "SignalType" SG_ 2153865216 StBltShftIntrlkCsStRq "ENM";
BA_ "SignalLongName" SG_ 2153865216 StBltShftIntrlkCsStRq "Seat Belt Shift Interlock Customization Setting Request";
BA_ "VNSigAllNodes" SG_ 2153865216 StBltShftIntrlkCsStRq 1;
BA_ "GenSigSendType" SG_ 2153865216 TeenDrvReq 10;
BA_ "SignalType" SG_ 2153865216 TeenDrvReq "ENM";
BA_ "SignalLongName" SG_ 2153865216 TeenDrvReq "Teen Driver Request";
BA_ "VNSigAllNodes" SG_ 2153865216 TeenDrvReq 1;
BA_ "GenSigDeltaValue" SG_ 2153865216 TeenDrvPinCd 1;
BA_ "GenSigSendType" SG_ 2153865216 TeenDrvPinCd 12;
BA_ "SignalType" SG_ 2153865216 TeenDrvPinCd "BCD";
BA_ "SignalLongName" SG_ 2153865216 TeenDrvPinCd "Teen Driver PIN Code";
BA_ "VNSigAllNodes" SG_ 2153865216 TeenDrvPinCd 1;
BA_ "GenSigSendType" SG_ 2153865216 TnDrvSpdLmtCstStReq 10;
BA_ "SignalType" SG_ 2153865216 TnDrvSpdLmtCstStReq "ENM";
BA_ "SignalLongName" SG_ 2153865216 TnDrvSpdLmtCstStReq "Teen Driver Speed Limit Customization Setting Request";
BA_ "VNSigAllNodes" SG_ 2153865216 TnDrvSpdLmtCstStReq 1;
BA_ "GenSigSendType" SG_ 2153865216 TDOWCSR_StatReq 10;
BA_ "SignalType" SG_ 2153865216 TDOWCSR_StatReq "ENM";
BA_ "PacketOrder" SG_ 2153865216 TDOWCSR_StatReq 1;
BA_ "SignalLongName" SG_ 2153865216 TDOWCSR_StatReq "Teen Driver Overspeed Warning Customization Setting Request : Status Request";
BA_ "VNSigAllNodes" SG_ 2153865216 TDOWCSR_StatReq 1;
BA_ "GenSigSendType" SG_ 2153865216 TDOWCSR_IncSwAct 10;
BA_ "SignalType" SG_ 2153865216 TDOWCSR_IncSwAct "BLN";
BA_ "PacketOrder" SG_ 2153865216 TDOWCSR_IncSwAct 2;
BA_ "SignalLongName" SG_ 2153865216 TDOWCSR_IncSwAct "Teen Driver Overspeed Warning Customization Setting Request : Increment  Switch Active";
BA_ "VNSigAllNodes" SG_ 2153865216 TDOWCSR_IncSwAct 1;
BA_ "GenSigSendType" SG_ 2153865216 TDOWCSR_DecSwAct 10;
BA_ "SignalType" SG_ 2153865216 TDOWCSR_DecSwAct "BLN";
BA_ "PacketOrder" SG_ 2153865216 TDOWCSR_DecSwAct 3;
BA_ "SignalLongName" SG_ 2153865216 TDOWCSR_DecSwAct "Teen Driver Overspeed Warning Customization Setting Request : Decrement  Switch Active";
BA_ "VNSigAllNodes" SG_ 2153865216 TDOWCSR_DecSwAct 1;
BA_ "GenSigSendType" SG_ 2153840640 TnDrvDRLOffUnbIO 10;
BA_ "SignalType" SG_ 2153840640 TnDrvDRLOffUnbIO "BLN";
BA_ "SignalLongName" SG_ 2153840640 TnDrvDRLOffUnbIO "Teen Driver Daytime Running Lights Off Unavailable Indication On";
BA_ "VNSigAllNodes" SG_ 2153840640 TnDrvDRLOffUnbIO 1;
BA_ "GenSigSendType" SG_ 2153840640 TnDrvALCOffUnbIO 10;
BA_ "SignalType" SG_ 2153840640 TnDrvALCOffUnbIO "BLN";
BA_ "SignalLongName" SG_ 2153840640 TnDrvALCOffUnbIO "Teen Driver Automatic Light Control Off Unavailable Indication On";
BA_ "VNSigAllNodes" SG_ 2153840640 TnDrvALCOffUnbIO 1;
BA_ "GenSigDeltaValue" SG_ 2153840640 TeenDrvLDWEvntsRpt 1;
BA_ "GenSigSendType" SG_ 2153840640 TeenDrvLDWEvntsRpt 12;
BA_ "GenSigSendOnInit" SG_ 2153840640 TeenDrvLDWEvntsRpt 2;
BA_ "SignalType" SG_ 2153840640 TeenDrvLDWEvntsRpt "UNM";
BA_ "SignalLongName" SG_ 2153840640 TeenDrvLDWEvntsRpt "Teen Driver Lane Departure Warning Events Report";
BA_ "VNSigAllNodes" SG_ 2153840640 TeenDrvLDWEvntsRpt 1;
BA_ "GenSigDeltaValue" SG_ 2153840640 TeenDrvMaxSpdRpt 1;
BA_ "GenSigSendType" SG_ 2153840640 TeenDrvMaxSpdRpt 12;
BA_ "GenSigSendOnInit" SG_ 2153840640 TeenDrvMaxSpdRpt 2;
BA_ "SignalType" SG_ 2153840640 TeenDrvMaxSpdRpt "UNM";
BA_ "SignalLongName" SG_ 2153840640 TeenDrvMaxSpdRpt "Teen Driver Maximum Speed Report";
BA_ "VNSigAllNodes" SG_ 2153840640 TeenDrvMaxSpdRpt 1;
BA_ "GenSigDeltaValue" SG_ 2153840640 TDFwdClnImntAlrtsRpt 1;
BA_ "GenSigSendType" SG_ 2153840640 TDFwdClnImntAlrtsRpt 12;
BA_ "GenSigSendOnInit" SG_ 2153840640 TDFwdClnImntAlrtsRpt 2;
BA_ "SignalType" SG_ 2153840640 TDFwdClnImntAlrtsRpt "UNM";
BA_ "SignalLongName" SG_ 2153840640 TDFwdClnImntAlrtsRpt "Teen Driver Forward Collision Imminent Alerts Report";
BA_ "VNSigAllNodes" SG_ 2153840640 TDFwdClnImntAlrtsRpt 1;
BA_ "GenSigDeltaValue" SG_ 2153840640 TDRevClnMtgnBrEvRpt 1;
BA_ "GenSigSendType" SG_ 2153840640 TDRevClnMtgnBrEvRpt 12;
BA_ "GenSigSendOnInit" SG_ 2153840640 TDRevClnMtgnBrEvRpt 2;
BA_ "SignalType" SG_ 2153840640 TDRevClnMtgnBrEvRpt "UNM";
BA_ "SignalLongName" SG_ 2153840640 TDRevClnMtgnBrEvRpt "Teen Driver Reverse Collision Mitigation Braking Events Report";
BA_ "VNSigAllNodes" SG_ 2153840640 TDRevClnMtgnBrEvRpt 1;
BA_ "GenSigDeltaValue" SG_ 2153840640 TDFwdClnMtgnBrEvRpt 1;
BA_ "GenSigSendType" SG_ 2153840640 TDFwdClnMtgnBrEvRpt 12;
BA_ "GenSigSendOnInit" SG_ 2153840640 TDFwdClnMtgnBrEvRpt 2;
BA_ "SignalType" SG_ 2153840640 TDFwdClnMtgnBrEvRpt "UNM";
BA_ "SignalLongName" SG_ 2153840640 TDFwdClnMtgnBrEvRpt "Teen Driver Forward Collision Mitigation Braking Events Report";
BA_ "VNSigAllNodes" SG_ 2153840640 TDFwdClnMtgnBrEvRpt 1;
BA_ "GenSigDeltaValue" SG_ 2153840640 TDFwdClnHdwyAlrtsRpt 1;
BA_ "GenSigSendType" SG_ 2153840640 TDFwdClnHdwyAlrtsRpt 12;
BA_ "GenSigSendOnInit" SG_ 2153840640 TDFwdClnHdwyAlrtsRpt 2;
BA_ "SignalType" SG_ 2153840640 TDFwdClnHdwyAlrtsRpt "UNM";
BA_ "SignalLongName" SG_ 2153840640 TDFwdClnHdwyAlrtsRpt "Teen Driver Forward Collision Headway Alerts Report";
BA_ "VNSigAllNodes" SG_ 2153840640 TDFwdClnHdwyAlrtsRpt 1;
BA_ "GenSigSendType" SG_ 2153824256 TeenDrvAccelLimIO 10;
BA_ "GenSigSendOnInit" SG_ 2153824256 TeenDrvAccelLimIO 2;
BA_ "SignalType" SG_ 2153824256 TeenDrvAccelLimIO "BLN";
BA_ "SignalLongName" SG_ 2153824256 TeenDrvAccelLimIO "Teen Driver Acceleration Limit Indication On";
BA_ "VNSigAllNodes" SG_ 2153824256 TeenDrvAccelLimIO 1;
BA_ "GenSigDeltaValue" SG_ 2153824256 TeenDrvDistDrvnRpt 1;
BA_ "GenSigSendType" SG_ 2153824256 TeenDrvDistDrvnRpt 12;
BA_ "GenSigSendOnInit" SG_ 2153824256 TeenDrvDistDrvnRpt 2;
BA_ "SignalType" SG_ 2153824256 TeenDrvDistDrvnRpt "UNM";
BA_ "SignalLongName" SG_ 2153824256 TeenDrvDistDrvnRpt "Teen Driver Distance Driven Report";
BA_ "VNSigAllNodes" SG_ 2153824256 TeenDrvDistDrvnRpt 1;
BA_ "GenSigDeltaValue" SG_ 2153824256 TnDrvOvSpdEvntsRpt 1;
BA_ "GenSigSendType" SG_ 2153824256 TnDrvOvSpdEvntsRpt 12;
BA_ "GenSigSendOnInit" SG_ 2153824256 TnDrvOvSpdEvntsRpt 2;
BA_ "SignalType" SG_ 2153824256 TnDrvOvSpdEvntsRpt "UNM";
BA_ "SignalLongName" SG_ 2153824256 TnDrvOvSpdEvntsRpt "Teen Driver Overspeed Events Report";
BA_ "VNSigAllNodes" SG_ 2153824256 TnDrvOvSpdEvntsRpt 1;
BA_ "GenSigSendType" SG_ 2153824256 TeenDrvAct 10;
BA_ "GenSigSendOnInit" SG_ 2153824256 TeenDrvAct 2;
BA_ "SignalType" SG_ 2153824256 TeenDrvAct "BLN";
BA_ "SignalLongName" SG_ 2153824256 TeenDrvAct "Teen Driver Active";
BA_ "VNSigAllNodes" SG_ 2153824256 TeenDrvAct 1;
BA_ "GenSigSendType" SG_ 2153824256 TeenDrvRsp 10;
BA_ "GenSigSendOnInit" SG_ 2153824256 TeenDrvRsp 2;
BA_ "SignalType" SG_ 2153824256 TeenDrvRsp "ENM";
BA_ "SignalLongName" SG_ 2153824256 TeenDrvRsp "Teen Driver Response";
BA_ "VNSigAllNodes" SG_ 2153824256 TeenDrvRsp 1;
BA_ "GenSigSendType" SG_ 2153824256 TeenDrvFtrAvl 10;
BA_ "GenSigSendOnInit" SG_ 2153824256 TeenDrvFtrAvl 2;
BA_ "SignalType" SG_ 2153824256 TeenDrvFtrAvl "BLN";
BA_ "SignalLongName" SG_ 2153824256 TeenDrvFtrAvl "Teen Driver Feature Available";
BA_ "VNSigAllNodes" SG_ 2153824256 TeenDrvFtrAvl 1;
BA_ "GenSigSendType" SG_ 2153824256 TeenDrvPINStrd 10;
BA_ "GenSigSendOnInit" SG_ 2153824256 TeenDrvPINStrd 2;
BA_ "SignalType" SG_ 2153824256 TeenDrvPINStrd "BLN";
BA_ "SignalLongName" SG_ 2153824256 TeenDrvPINStrd "Teen Driver PIN Stored";
BA_ "VNSigAllNodes" SG_ 2153824256 TeenDrvPINStrd 1;
BA_ "GenSigSendType" SG_ 2153824256 TnDrvGapAdjUnbIO 10;
BA_ "SignalType" SG_ 2153824256 TnDrvGapAdjUnbIO "BLN";
BA_ "SignalLongName" SG_ 2153824256 TnDrvGapAdjUnbIO "Teen Driver Gap Adjust Unavailable Indication On";
BA_ "VNSigAllNodes" SG_ 2153824256 TnDrvGapAdjUnbIO 1;
BA_ "GenSigSendType" SG_ 2153824256 TnDrvOvrSpdIO 10;
BA_ "SignalType" SG_ 2153824256 TnDrvOvrSpdIO "BLN";
BA_ "SignalLongName" SG_ 2153824256 TnDrvOvrSpdIO "Teen Driver Overspeed Indication On";
BA_ "VNSigAllNodes" SG_ 2153824256 TnDrvOvrSpdIO 1;
BA_ "GenSigSendType" SG_ 2153824256 TDOvSpdWrnCstStAvl 10;
BA_ "GenSigSendOnInit" SG_ 2153824256 TDOvSpdWrnCstStAvl 2;
BA_ "SignalType" SG_ 2153824256 TDOvSpdWrnCstStAvl "BLN";
BA_ "SignalLongName" SG_ 2153824256 TDOvSpdWrnCstStAvl "Teen Driver Overspeed Warning Customization Setting Available";
BA_ "VNSigAllNodes" SG_ 2153824256 TDOvSpdWrnCstStAvl 1;
BA_ "GenSigDeltaValue" SG_ 2153824256 TDOWCCSV_CrStVl 1;
BA_ "GenSigSendType" SG_ 2153824256 TDOWCCSV_CrStVl 12;
BA_ "GenSigSendOnInit" SG_ 2153824256 TDOWCCSV_CrStVl 2;
BA_ "SignalType" SG_ 2153824256 TDOWCCSV_CrStVl "UNM";
BA_ "PacketOrder" SG_ 2153824256 TDOWCCSV_CrStVl 2;
BA_ "SignalLongName" SG_ 2153824256 TDOWCCSV_CrStVl "Teen Driver Overspeed Warning Customization Current Setting Value : Current Setting Value";
BA_ "VNSigAllNodes" SG_ 2153824256 TDOWCCSV_CrStVl 1;
BA_ "GenSigSendType" SG_ 2153824256 TDOWCCSV_CrStat 10;
BA_ "GenSigSendOnInit" SG_ 2153824256 TDOWCCSV_CrStat 2;
BA_ "SignalType" SG_ 2153824256 TDOWCCSV_CrStat "ENM";
BA_ "PacketOrder" SG_ 2153824256 TDOWCCSV_CrStat 1;
BA_ "SignalLongName" SG_ 2153824256 TDOWCCSV_CrStat "Teen Driver Overspeed Warning Customization Current Setting Value : Current Status";
BA_ "VNSigAllNodes" SG_ 2153824256 TDOWCCSV_CrStat 1;
BA_ "GenSigSendType" SG_ 2153824256 TnDrvSpdLmtCstStAvl 10;
BA_ "GenSigSendOnInit" SG_ 2153824256 TnDrvSpdLmtCstStAvl 2;
BA_ "SignalType" SG_ 2153824256 TnDrvSpdLmtCstStAvl "BLN";
BA_ "SignalLongName" SG_ 2153824256 TnDrvSpdLmtCstStAvl "Teen Driver Speed Limit Customization Setting Available";
BA_ "VNSigAllNodes" SG_ 2153824256 TnDrvSpdLmtCstStAvl 1;
BA_ "GenSigSendType" SG_ 2153824256 TDSLCCSV_SpLmtStat 10;
BA_ "GenSigSendOnInit" SG_ 2153824256 TDSLCCSV_SpLmtStat 2;
BA_ "SignalType" SG_ 2153824256 TDSLCCSV_SpLmtStat "ENM";
BA_ "PacketOrder" SG_ 2153824256 TDSLCCSV_SpLmtStat 1;
BA_ "SignalLongName" SG_ 2153824256 TDSLCCSV_SpLmtStat "Teen Driver Speed Limit Customization Current Setting Value : Speed Limit Status";
BA_ "VNSigAllNodes" SG_ 2153824256 TDSLCCSV_SpLmtStat 1;
BA_ "GenSigDeltaValue" SG_ 2153824256 TDSLCCSV_SpLmDisVl 1;
BA_ "GenSigSendType" SG_ 2153824256 TDSLCCSV_SpLmDisVl 12;
BA_ "GenSigSendOnInit" SG_ 2153824256 TDSLCCSV_SpLmDisVl 2;
BA_ "SignalType" SG_ 2153824256 TDSLCCSV_SpLmDisVl "UNM";
BA_ "PacketOrder" SG_ 2153824256 TDSLCCSV_SpLmDisVl 2;
BA_ "SignalLongName" SG_ 2153824256 TDSLCCSV_SpLmDisVl "Teen Driver Speed Limit Customization Current Setting Value : Speed Limit Display Value";
BA_ "VNSigAllNodes" SG_ 2153824256 TDSLCCSV_SpLmDisVl 1;
BA_ "GenSigSendType" SG_ 2155151360 PSMP_UnsdRsrvd 10;
BA_ "GenSigSendOnInit" SG_ 2155151360 PSMP_UnsdRsrvd 2;
BA_ "SignalType" SG_ 2155151360 PSMP_UnsdRsrvd "BLN";
BA_ "PacketOrder" SG_ 2155151360 PSMP_UnsdRsrvd 17;
BA_ "SignalLongName" SG_ 2155151360 PSMP_UnsdRsrvd "Passenger Seat Massage Priority : Unused and Reserved";
BA_ "VNSigAllNodes" SG_ 2155151360 PSMP_UnsdRsrvd 1;
BA_ "GenSigDeltaValue" SG_ 2155151360 PSMP_MaxDispVal 1;
BA_ "GenSigSendType" SG_ 2155151360 PSMP_MaxDispVal 12;
BA_ "GenSigSendOnInit" SG_ 2155151360 PSMP_MaxDispVal 2;
BA_ "SignalType" SG_ 2155151360 PSMP_MaxDispVal "UNM";
BA_ "PacketOrder" SG_ 2155151360 PSMP_MaxDispVal 16;
BA_ "SignalLongName" SG_ 2155151360 PSMP_MaxDispVal "Passenger Seat Massage Priority : Maximum Display Value";
BA_ "VNSigAllNodes" SG_ 2155151360 PSMP_MaxDispVal 1;
BA_ "GenSigDeltaValue" SG_ 2155151360 PSMP_Type15 1;
BA_ "GenSigSendType" SG_ 2155151360 PSMP_Type15 12;
BA_ "GenSigSendOnInit" SG_ 2155151360 PSMP_Type15 2;
BA_ "SignalType" SG_ 2155151360 PSMP_Type15 "UNM";
BA_ "PacketOrder" SG_ 2155151360 PSMP_Type15 15;
BA_ "SignalLongName" SG_ 2155151360 PSMP_Type15 "Passenger Seat Massage Priority : Type 15";
BA_ "VNSigAllNodes" SG_ 2155151360 PSMP_Type15 1;
BA_ "GenSigDeltaValue" SG_ 2155151360 PSMP_Type14 1;
BA_ "GenSigSendType" SG_ 2155151360 PSMP_Type14 12;
BA_ "GenSigSendOnInit" SG_ 2155151360 PSMP_Type14 2;
BA_ "SignalType" SG_ 2155151360 PSMP_Type14 "UNM";
BA_ "PacketOrder" SG_ 2155151360 PSMP_Type14 14;
BA_ "SignalLongName" SG_ 2155151360 PSMP_Type14 "Passenger Seat Massage Priority : Type 14";
BA_ "VNSigAllNodes" SG_ 2155151360 PSMP_Type14 1;
BA_ "GenSigDeltaValue" SG_ 2155151360 PSMP_Type13 1;
BA_ "GenSigSendType" SG_ 2155151360 PSMP_Type13 12;
BA_ "GenSigSendOnInit" SG_ 2155151360 PSMP_Type13 2;
BA_ "SignalType" SG_ 2155151360 PSMP_Type13 "UNM";
BA_ "PacketOrder" SG_ 2155151360 PSMP_Type13 13;
BA_ "SignalLongName" SG_ 2155151360 PSMP_Type13 "Passenger Seat Massage Priority : Type 13";
BA_ "VNSigAllNodes" SG_ 2155151360 PSMP_Type13 1;
BA_ "GenSigDeltaValue" SG_ 2155151360 PSMP_Type12 1;
BA_ "GenSigSendType" SG_ 2155151360 PSMP_Type12 12;
BA_ "GenSigSendOnInit" SG_ 2155151360 PSMP_Type12 2;
BA_ "SignalType" SG_ 2155151360 PSMP_Type12 "UNM";
BA_ "PacketOrder" SG_ 2155151360 PSMP_Type12 12;
BA_ "SignalLongName" SG_ 2155151360 PSMP_Type12 "Passenger Seat Massage Priority : Type 12";
BA_ "VNSigAllNodes" SG_ 2155151360 PSMP_Type12 1;
BA_ "GenSigDeltaValue" SG_ 2155151360 PSMP_Type11 1;
BA_ "GenSigSendType" SG_ 2155151360 PSMP_Type11 12;
BA_ "GenSigSendOnInit" SG_ 2155151360 PSMP_Type11 2;
BA_ "SignalType" SG_ 2155151360 PSMP_Type11 "UNM";
BA_ "PacketOrder" SG_ 2155151360 PSMP_Type11 11;
BA_ "SignalLongName" SG_ 2155151360 PSMP_Type11 "Passenger Seat Massage Priority : Type 11";
BA_ "VNSigAllNodes" SG_ 2155151360 PSMP_Type11 1;
BA_ "GenSigDeltaValue" SG_ 2155151360 PSMP_Type10 1;
BA_ "GenSigSendType" SG_ 2155151360 PSMP_Type10 12;
BA_ "GenSigSendOnInit" SG_ 2155151360 PSMP_Type10 2;
BA_ "SignalType" SG_ 2155151360 PSMP_Type10 "UNM";
BA_ "PacketOrder" SG_ 2155151360 PSMP_Type10 10;
BA_ "SignalLongName" SG_ 2155151360 PSMP_Type10 "Passenger Seat Massage Priority : Type 10";
BA_ "VNSigAllNodes" SG_ 2155151360 PSMP_Type10 1;
BA_ "GenSigDeltaValue" SG_ 2155151360 PSMP_Type9 1;
BA_ "GenSigSendType" SG_ 2155151360 PSMP_Type9 12;
BA_ "GenSigSendOnInit" SG_ 2155151360 PSMP_Type9 2;
BA_ "SignalType" SG_ 2155151360 PSMP_Type9 "UNM";
BA_ "PacketOrder" SG_ 2155151360 PSMP_Type9 9;
BA_ "SignalLongName" SG_ 2155151360 PSMP_Type9 "Passenger Seat Massage Priority : Type 9";
BA_ "VNSigAllNodes" SG_ 2155151360 PSMP_Type9 1;
BA_ "GenSigDeltaValue" SG_ 2155151360 PSMP_Type8 1;
BA_ "GenSigSendType" SG_ 2155151360 PSMP_Type8 12;
BA_ "GenSigSendOnInit" SG_ 2155151360 PSMP_Type8 2;
BA_ "SignalType" SG_ 2155151360 PSMP_Type8 "UNM";
BA_ "PacketOrder" SG_ 2155151360 PSMP_Type8 8;
BA_ "SignalLongName" SG_ 2155151360 PSMP_Type8 "Passenger Seat Massage Priority : Type 8";
BA_ "VNSigAllNodes" SG_ 2155151360 PSMP_Type8 1;
BA_ "GenSigDeltaValue" SG_ 2155151360 PSMP_Type7 1;
BA_ "GenSigSendType" SG_ 2155151360 PSMP_Type7 12;
BA_ "GenSigSendOnInit" SG_ 2155151360 PSMP_Type7 2;
BA_ "SignalType" SG_ 2155151360 PSMP_Type7 "UNM";
BA_ "PacketOrder" SG_ 2155151360 PSMP_Type7 7;
BA_ "SignalLongName" SG_ 2155151360 PSMP_Type7 "Passenger Seat Massage Priority : Type 7";
BA_ "VNSigAllNodes" SG_ 2155151360 PSMP_Type7 1;
BA_ "GenSigDeltaValue" SG_ 2155151360 PSMP_Type6 1;
BA_ "GenSigSendType" SG_ 2155151360 PSMP_Type6 12;
BA_ "GenSigSendOnInit" SG_ 2155151360 PSMP_Type6 2;
BA_ "SignalType" SG_ 2155151360 PSMP_Type6 "UNM";
BA_ "PacketOrder" SG_ 2155151360 PSMP_Type6 6;
BA_ "SignalLongName" SG_ 2155151360 PSMP_Type6 "Passenger Seat Massage Priority : Type 6";
BA_ "VNSigAllNodes" SG_ 2155151360 PSMP_Type6 1;
BA_ "GenSigDeltaValue" SG_ 2155151360 PSMP_Type5 1;
BA_ "GenSigSendType" SG_ 2155151360 PSMP_Type5 12;
BA_ "GenSigSendOnInit" SG_ 2155151360 PSMP_Type5 2;
BA_ "SignalType" SG_ 2155151360 PSMP_Type5 "UNM";
BA_ "PacketOrder" SG_ 2155151360 PSMP_Type5 5;
BA_ "SignalLongName" SG_ 2155151360 PSMP_Type5 "Passenger Seat Massage Priority : Type 5";
BA_ "VNSigAllNodes" SG_ 2155151360 PSMP_Type5 1;
BA_ "GenSigDeltaValue" SG_ 2155151360 PSMP_Type4 1;
BA_ "GenSigSendType" SG_ 2155151360 PSMP_Type4 12;
BA_ "GenSigSendOnInit" SG_ 2155151360 PSMP_Type4 2;
BA_ "SignalType" SG_ 2155151360 PSMP_Type4 "UNM";
BA_ "PacketOrder" SG_ 2155151360 PSMP_Type4 4;
BA_ "SignalLongName" SG_ 2155151360 PSMP_Type4 "Passenger Seat Massage Priority : Type 4";
BA_ "VNSigAllNodes" SG_ 2155151360 PSMP_Type4 1;
BA_ "GenSigDeltaValue" SG_ 2155151360 PSMP_Type3 1;
BA_ "GenSigSendType" SG_ 2155151360 PSMP_Type3 12;
BA_ "GenSigSendOnInit" SG_ 2155151360 PSMP_Type3 2;
BA_ "SignalType" SG_ 2155151360 PSMP_Type3 "UNM";
BA_ "PacketOrder" SG_ 2155151360 PSMP_Type3 3;
BA_ "SignalLongName" SG_ 2155151360 PSMP_Type3 "Passenger Seat Massage Priority : Type 3";
BA_ "VNSigAllNodes" SG_ 2155151360 PSMP_Type3 1;
BA_ "GenSigDeltaValue" SG_ 2155151360 PSMP_Type2 1;
BA_ "GenSigSendType" SG_ 2155151360 PSMP_Type2 12;
BA_ "GenSigSendOnInit" SG_ 2155151360 PSMP_Type2 2;
BA_ "SignalType" SG_ 2155151360 PSMP_Type2 "UNM";
BA_ "PacketOrder" SG_ 2155151360 PSMP_Type2 2;
BA_ "SignalLongName" SG_ 2155151360 PSMP_Type2 "Passenger Seat Massage Priority : Type 2";
BA_ "VNSigAllNodes" SG_ 2155151360 PSMP_Type2 1;
BA_ "GenSigDeltaValue" SG_ 2155151360 PSMP_Type1 1;
BA_ "GenSigSendType" SG_ 2155151360 PSMP_Type1 12;
BA_ "GenSigSendOnInit" SG_ 2155151360 PSMP_Type1 2;
BA_ "SignalType" SG_ 2155151360 PSMP_Type1 "UNM";
BA_ "PacketOrder" SG_ 2155151360 PSMP_Type1 1;
BA_ "SignalLongName" SG_ 2155151360 PSMP_Type1 "Passenger Seat Massage Priority : Type 1";
BA_ "VNSigAllNodes" SG_ 2155151360 PSMP_Type1 1;
BA_ "GenSigSendType" SG_ 2155134976 PsngrSetRrwdMvmnt 10;
BA_ "GenSigSendOnInit" SG_ 2155134976 PsngrSetRrwdMvmnt 2;
BA_ "SignalType" SG_ 2155134976 PsngrSetRrwdMvmnt "ENM";
BA_ "SignalLongName" SG_ 2155134976 PsngrSetRrwdMvmnt "Passenger Seat Rearward Movement";
BA_ "VNSigAllNodes" SG_ 2155134976 PsngrSetRrwdMvmnt 1;
BA_ "GenSigDeltaValue" SG_ 2155134976 PSCDS_UnsdRsrvd 1;
BA_ "GenSigSendType" SG_ 2155134976 PSCDS_UnsdRsrvd 12;
BA_ "GenSigSendOnInit" SG_ 2155134976 PSCDS_UnsdRsrvd 2;
BA_ "SignalType" SG_ 2155134976 PSCDS_UnsdRsrvd "UNM";
BA_ "PacketOrder" SG_ 2155134976 PSCDS_UnsdRsrvd 19;
BA_ "SignalLongName" SG_ 2155134976 PSCDS_UnsdRsrvd "Passenger Seat Control Display Status : Unused and Reserved";
BA_ "VNSigAllNodes" SG_ 2155134976 PSCDS_UnsdRsrvd 1;
BA_ "GenSigSendType" SG_ 2155134976 PSCDS_DispReq 10;
BA_ "GenSigSendOnInit" SG_ 2155134976 PSCDS_DispReq 2;
BA_ "SignalType" SG_ 2155134976 PSCDS_DispReq "BLN";
BA_ "PacketOrder" SG_ 2155134976 PSCDS_DispReq 18;
BA_ "SignalLongName" SG_ 2155134976 PSCDS_DispReq "Passenger Seat Control Display Status : Display Request";
BA_ "VNSigAllNodes" SG_ 2155134976 PSCDS_DispReq 1;
BA_ "GenSigSendType" SG_ 2155134976 PSCDS_DispSz 10;
BA_ "GenSigSendOnInit" SG_ 2155134976 PSCDS_DispSz 2;
BA_ "SignalType" SG_ 2155134976 PSCDS_DispSz "ENM";
BA_ "PacketOrder" SG_ 2155134976 PSCDS_DispSz 17;
BA_ "SignalLongName" SG_ 2155134976 PSCDS_DispSz "Passenger Seat Control Display Status : Display Size";
BA_ "VNSigAllNodes" SG_ 2155134976 PSCDS_DispSz 1;
BA_ "GenSigSendType" SG_ 2155134976 PSCDS_CshLgAdjFdRr 10;
BA_ "GenSigSendOnInit" SG_ 2155134976 PSCDS_CshLgAdjFdRr 2;
BA_ "SignalType" SG_ 2155134976 PSCDS_CshLgAdjFdRr "ENM";
BA_ "PacketOrder" SG_ 2155134976 PSCDS_CshLgAdjFdRr 16;
BA_ "SignalLongName" SG_ 2155134976 PSCDS_CshLgAdjFdRr "Passenger Seat Control Display Status : Cushion Length Adjustment Forward/Rearward";
BA_ "VNSigAllNodes" SG_ 2155134976 PSCDS_CshLgAdjFdRr 1;
BA_ "GenSigSendType" SG_ 2155134976 PSCDS_BkCshBlstInOt 10;
BA_ "GenSigSendOnInit" SG_ 2155134976 PSCDS_BkCshBlstInOt 2;
BA_ "SignalType" SG_ 2155134976 PSCDS_BkCshBlstInOt "ENM";
BA_ "PacketOrder" SG_ 2155134976 PSCDS_BkCshBlstInOt 15;
BA_ "SignalLongName" SG_ 2155134976 PSCDS_BkCshBlstInOt "Passenger Seat Control Display Status : Back and Cushion Bolster In/Out";
BA_ "VNSigAllNodes" SG_ 2155134976 PSCDS_BkCshBlstInOt 1;
BA_ "GenSigSendType" SG_ 2155134976 PSCDS_CshBlstrInOut 10;
BA_ "GenSigSendOnInit" SG_ 2155134976 PSCDS_CshBlstrInOut 2;
BA_ "SignalType" SG_ 2155134976 PSCDS_CshBlstrInOut "ENM";
BA_ "PacketOrder" SG_ 2155134976 PSCDS_CshBlstrInOut 14;
BA_ "SignalLongName" SG_ 2155134976 PSCDS_CshBlstrInOut "Passenger Seat Control Display Status : Cushion Bolster In/Out";
BA_ "VNSigAllNodes" SG_ 2155134976 PSCDS_CshBlstrInOut 1;
BA_ "GenSigSendType" SG_ 2155134976 PSCDS_BkBlstrInOut 10;
BA_ "GenSigSendOnInit" SG_ 2155134976 PSCDS_BkBlstrInOut 2;
BA_ "SignalType" SG_ 2155134976 PSCDS_BkBlstrInOut "ENM";
BA_ "PacketOrder" SG_ 2155134976 PSCDS_BkBlstrInOut 13;
BA_ "SignalLongName" SG_ 2155134976 PSCDS_BkBlstrInOut "Passenger Seat Control Display Status : Back Bolster In/Out";
BA_ "VNSigAllNodes" SG_ 2155134976 PSCDS_BkBlstrInOut 1;
BA_ "GenSigSendType" SG_ 2155134976 PSCDS_LmbrUDnFdRr 10;
BA_ "GenSigSendOnInit" SG_ 2155134976 PSCDS_LmbrUDnFdRr 2;
BA_ "SignalType" SG_ 2155134976 PSCDS_LmbrUDnFdRr "ENM";
BA_ "PacketOrder" SG_ 2155134976 PSCDS_LmbrUDnFdRr 12;
BA_ "SignalLongName" SG_ 2155134976 PSCDS_LmbrUDnFdRr "Passenger Seat Control Display Status : Lumbar Up/Down and Forward/Rearward";
BA_ "VNSigAllNodes" SG_ 2155134976 PSCDS_LmbrUDnFdRr 1;
BA_ "GenSigSendType" SG_ 2155134976 PSCDS_LmbrFwdRr 10;
BA_ "GenSigSendOnInit" SG_ 2155134976 PSCDS_LmbrFwdRr 2;
BA_ "SignalType" SG_ 2155134976 PSCDS_LmbrFwdRr "ENM";
BA_ "PacketOrder" SG_ 2155134976 PSCDS_LmbrFwdRr 11;
BA_ "SignalLongName" SG_ 2155134976 PSCDS_LmbrFwdRr "Passenger Seat Control Display Status : Lumbar Forward/Rearward";
BA_ "VNSigAllNodes" SG_ 2155134976 PSCDS_LmbrFwdRr 1;
BA_ "GenSigSendType" SG_ 2155134976 PSCDS_LmbrUpDwn 10;
BA_ "GenSigSendOnInit" SG_ 2155134976 PSCDS_LmbrUpDwn 2;
BA_ "SignalType" SG_ 2155134976 PSCDS_LmbrUpDwn "ENM";
BA_ "PacketOrder" SG_ 2155134976 PSCDS_LmbrUpDwn 10;
BA_ "SignalLongName" SG_ 2155134976 PSCDS_LmbrUpDwn "Passenger Seat Control Display Status : Lumbar Up/Down";
BA_ "VNSigAllNodes" SG_ 2155134976 PSCDS_LmbrUpDwn 1;
BA_ "GenSigSendType" SG_ 2155134976 PSCDS_UprShldrFdRr 10;
BA_ "GenSigSendOnInit" SG_ 2155134976 PSCDS_UprShldrFdRr 2;
BA_ "SignalType" SG_ 2155134976 PSCDS_UprShldrFdRr "ENM";
BA_ "PacketOrder" SG_ 2155134976 PSCDS_UprShldrFdRr 9;
BA_ "SignalLongName" SG_ 2155134976 PSCDS_UprShldrFdRr "Passenger Seat Control Display Status : Upper Shoulder Forward/Rearward";
BA_ "VNSigAllNodes" SG_ 2155134976 PSCDS_UprShldrFdRr 1;
BA_ "GenSigSendType" SG_ 2155134976 PSCDS_HdrstTltFwdRr 10;
BA_ "GenSigSendOnInit" SG_ 2155134976 PSCDS_HdrstTltFwdRr 2;
BA_ "SignalType" SG_ 2155134976 PSCDS_HdrstTltFwdRr "ENM";
BA_ "PacketOrder" SG_ 2155134976 PSCDS_HdrstTltFwdRr 8;
BA_ "SignalLongName" SG_ 2155134976 PSCDS_HdrstTltFwdRr "Passenger Seat Control Display Status : Headrest Tilt Forward/Rearward";
BA_ "VNSigAllNodes" SG_ 2155134976 PSCDS_HdrstTltFwdRr 1;
BA_ "GenSigSendType" SG_ 2155134976 PSCDS_HdrstWngInOt 10;
BA_ "GenSigSendOnInit" SG_ 2155134976 PSCDS_HdrstWngInOt 2;
BA_ "SignalType" SG_ 2155134976 PSCDS_HdrstWngInOt "ENM";
BA_ "PacketOrder" SG_ 2155134976 PSCDS_HdrstWngInOt 7;
BA_ "SignalLongName" SG_ 2155134976 PSCDS_HdrstWngInOt "Passenger Seat Control Display Status : Headrest Wings In/Out";
BA_ "VNSigAllNodes" SG_ 2155134976 PSCDS_HdrstWngInOt 1;
BA_ "GenSigSendType" SG_ 2155134976 PSCDS_HdrstUDnFdRr 10;
BA_ "GenSigSendOnInit" SG_ 2155134976 PSCDS_HdrstUDnFdRr 2;
BA_ "SignalType" SG_ 2155134976 PSCDS_HdrstUDnFdRr "ENM";
BA_ "PacketOrder" SG_ 2155134976 PSCDS_HdrstUDnFdRr 6;
BA_ "SignalLongName" SG_ 2155134976 PSCDS_HdrstUDnFdRr "Passenger Seat Control Display Status : Headrest Forward/Rearward and Up/Down";
BA_ "VNSigAllNodes" SG_ 2155134976 PSCDS_HdrstUDnFdRr 1;
BA_ "GenSigSendType" SG_ 2155134976 PSCDS_HdrstFwdRrwd 10;
BA_ "GenSigSendOnInit" SG_ 2155134976 PSCDS_HdrstFwdRrwd 2;
BA_ "SignalType" SG_ 2155134976 PSCDS_HdrstFwdRrwd "ENM";
BA_ "PacketOrder" SG_ 2155134976 PSCDS_HdrstFwdRrwd 5;
BA_ "SignalLongName" SG_ 2155134976 PSCDS_HdrstFwdRrwd "Passenger Seat Control Display Status : Headrest Forward/Rearward";
BA_ "VNSigAllNodes" SG_ 2155134976 PSCDS_HdrstFwdRrwd 1;
BA_ "GenSigSendType" SG_ 2155134976 PSCDS_HdrstUpDn 10;
BA_ "GenSigSendOnInit" SG_ 2155134976 PSCDS_HdrstUpDn 2;
BA_ "SignalType" SG_ 2155134976 PSCDS_HdrstUpDn "ENM";
BA_ "PacketOrder" SG_ 2155134976 PSCDS_HdrstUpDn 4;
BA_ "SignalLongName" SG_ 2155134976 PSCDS_HdrstUpDn "Passenger Seat Control Display Status : Headrest Up/Down";
BA_ "VNSigAllNodes" SG_ 2155134976 PSCDS_HdrstUpDn 1;
BA_ "GenSigSendType" SG_ 2155134976 PSCDS_MassgIntsty 10;
BA_ "GenSigSendOnInit" SG_ 2155134976 PSCDS_MassgIntsty 2;
BA_ "SignalType" SG_ 2155134976 PSCDS_MassgIntsty "ENM";
BA_ "PacketOrder" SG_ 2155134976 PSCDS_MassgIntsty 3;
BA_ "SignalLongName" SG_ 2155134976 PSCDS_MassgIntsty "Passenger Seat Control Display Status : Massage Intensity";
BA_ "VNSigAllNodes" SG_ 2155134976 PSCDS_MassgIntsty 1;
BA_ "GenSigSendType" SG_ 2155134976 PSCDS_MassgTyp 10;
BA_ "GenSigSendOnInit" SG_ 2155134976 PSCDS_MassgTyp 2;
BA_ "SignalType" SG_ 2155134976 PSCDS_MassgTyp "ENM";
BA_ "PacketOrder" SG_ 2155134976 PSCDS_MassgTyp 2;
BA_ "SignalLongName" SG_ 2155134976 PSCDS_MassgTyp "Passenger Seat Control Display Status : Massage Type";
BA_ "VNSigAllNodes" SG_ 2155134976 PSCDS_MassgTyp 1;
BA_ "GenSigSendType" SG_ 2155134976 PSCDS_Massg 10;
BA_ "GenSigSendOnInit" SG_ 2155134976 PSCDS_Massg 2;
BA_ "SignalType" SG_ 2155134976 PSCDS_Massg "ENM";
BA_ "PacketOrder" SG_ 2155134976 PSCDS_Massg 1;
BA_ "SignalLongName" SG_ 2155134976 PSCDS_Massg "Passenger Seat Control Display Status : Massage";
BA_ "VNSigAllNodes" SG_ 2155134976 PSCDS_Massg 1;
BA_ "GenSigDeltaValue" SG_ 2155118592 PSAP_UnsdRsrvd 1;
BA_ "GenSigSendType" SG_ 2155118592 PSAP_UnsdRsrvd 12;
BA_ "GenSigSendOnInit" SG_ 2155118592 PSAP_UnsdRsrvd 2;
BA_ "SignalType" SG_ 2155118592 PSAP_UnsdRsrvd "UNM";
BA_ "PacketOrder" SG_ 2155118592 PSAP_UnsdRsrvd 16;
BA_ "SignalLongName" SG_ 2155118592 PSAP_UnsdRsrvd "Passenger Seat Actuator Priority : Unused and Reserved";
BA_ "VNSigAllNodes" SG_ 2155118592 PSAP_UnsdRsrvd 1;
BA_ "GenSigDeltaValue" SG_ 2155118592 PSAP_DispSz 1;
BA_ "GenSigSendType" SG_ 2155118592 PSAP_DispSz 12;
BA_ "GenSigSendOnInit" SG_ 2155118592 PSAP_DispSz 2;
BA_ "SignalType" SG_ 2155118592 PSAP_DispSz "UNM";
BA_ "PacketOrder" SG_ 2155118592 PSAP_DispSz 15;
BA_ "SignalLongName" SG_ 2155118592 PSAP_DispSz "Passenger Seat Actuator Priority : Display Size";
BA_ "VNSigAllNodes" SG_ 2155118592 PSAP_DispSz 1;
BA_ "GenSigDeltaValue" SG_ 2155118592 PSAP_CshLgthAdjFdRr 1;
BA_ "GenSigSendType" SG_ 2155118592 PSAP_CshLgthAdjFdRr 12;
BA_ "GenSigSendOnInit" SG_ 2155118592 PSAP_CshLgthAdjFdRr 2;
BA_ "SignalType" SG_ 2155118592 PSAP_CshLgthAdjFdRr "UNM";
BA_ "PacketOrder" SG_ 2155118592 PSAP_CshLgthAdjFdRr 14;
BA_ "SignalLongName" SG_ 2155118592 PSAP_CshLgthAdjFdRr "Passenger Seat Actuator Priority : Cushion Length Adjustment Forward/Rearward";
BA_ "VNSigAllNodes" SG_ 2155118592 PSAP_CshLgthAdjFdRr 1;
BA_ "GenSigDeltaValue" SG_ 2155118592 PSAP_CshBlstrInOut 1;
BA_ "GenSigSendType" SG_ 2155118592 PSAP_CshBlstrInOut 12;
BA_ "GenSigSendOnInit" SG_ 2155118592 PSAP_CshBlstrInOut 2;
BA_ "SignalType" SG_ 2155118592 PSAP_CshBlstrInOut "UNM";
BA_ "PacketOrder" SG_ 2155118592 PSAP_CshBlstrInOut 12;
BA_ "SignalLongName" SG_ 2155118592 PSAP_CshBlstrInOut "Passenger Seat Actuator Priority : Cushion Bolster In/Out";
BA_ "VNSigAllNodes" SG_ 2155118592 PSAP_CshBlstrInOut 1;
BA_ "GenSigDeltaValue" SG_ 2155118592 PSAP_BkBlstrInOut 1;
BA_ "GenSigSendType" SG_ 2155118592 PSAP_BkBlstrInOut 12;
BA_ "GenSigSendOnInit" SG_ 2155118592 PSAP_BkBlstrInOut 2;
BA_ "SignalType" SG_ 2155118592 PSAP_BkBlstrInOut "UNM";
BA_ "PacketOrder" SG_ 2155118592 PSAP_BkBlstrInOut 11;
BA_ "SignalLongName" SG_ 2155118592 PSAP_BkBlstrInOut "Passenger Seat Actuator Priority : Back Bolster In/Out";
BA_ "VNSigAllNodes" SG_ 2155118592 PSAP_BkBlstrInOut 1;
BA_ "GenSigDeltaValue" SG_ 2155118592 PSAP_BkCshBlstrInOut 1;
BA_ "GenSigSendType" SG_ 2155118592 PSAP_BkCshBlstrInOut 12;
BA_ "GenSigSendOnInit" SG_ 2155118592 PSAP_BkCshBlstrInOut 2;
BA_ "SignalType" SG_ 2155118592 PSAP_BkCshBlstrInOut "UNM";
BA_ "PacketOrder" SG_ 2155118592 PSAP_BkCshBlstrInOut 13;
BA_ "SignalLongName" SG_ 2155118592 PSAP_BkCshBlstrInOut "Passenger Seat Actuator Priority : Back and Cushion Bolster In/Out";
BA_ "VNSigAllNodes" SG_ 2155118592 PSAP_BkCshBlstrInOut 1;
BA_ "GenSigDeltaValue" SG_ 2155118592 PSAP_LmbrUpDnFdRr 1;
BA_ "GenSigSendType" SG_ 2155118592 PSAP_LmbrUpDnFdRr 12;
BA_ "GenSigSendOnInit" SG_ 2155118592 PSAP_LmbrUpDnFdRr 2;
BA_ "SignalType" SG_ 2155118592 PSAP_LmbrUpDnFdRr "UNM";
BA_ "PacketOrder" SG_ 2155118592 PSAP_LmbrUpDnFdRr 10;
BA_ "SignalLongName" SG_ 2155118592 PSAP_LmbrUpDnFdRr "Passenger Seat Actuator Priority : Lumbar Up/Down and Forward/Rearward";
BA_ "VNSigAllNodes" SG_ 2155118592 PSAP_LmbrUpDnFdRr 1;
BA_ "GenSigDeltaValue" SG_ 2155118592 PSAP_LmbrFwdRr 1;
BA_ "GenSigSendType" SG_ 2155118592 PSAP_LmbrFwdRr 12;
BA_ "GenSigSendOnInit" SG_ 2155118592 PSAP_LmbrFwdRr 2;
BA_ "SignalType" SG_ 2155118592 PSAP_LmbrFwdRr "UNM";
BA_ "PacketOrder" SG_ 2155118592 PSAP_LmbrFwdRr 9;
BA_ "SignalLongName" SG_ 2155118592 PSAP_LmbrFwdRr "Passenger Seat Actuator Priority : Lumbar Forward/Rearward";
BA_ "VNSigAllNodes" SG_ 2155118592 PSAP_LmbrFwdRr 1;
BA_ "GenSigDeltaValue" SG_ 2155118592 PSAP_LmbrUpDwn 1;
BA_ "GenSigSendType" SG_ 2155118592 PSAP_LmbrUpDwn 12;
BA_ "GenSigSendOnInit" SG_ 2155118592 PSAP_LmbrUpDwn 2;
BA_ "SignalType" SG_ 2155118592 PSAP_LmbrUpDwn "UNM";
BA_ "PacketOrder" SG_ 2155118592 PSAP_LmbrUpDwn 8;
BA_ "SignalLongName" SG_ 2155118592 PSAP_LmbrUpDwn "Passenger Seat Actuator Priority : Lumbar Up/Down";
BA_ "VNSigAllNodes" SG_ 2155118592 PSAP_LmbrUpDwn 1;
BA_ "GenSigDeltaValue" SG_ 2155118592 PSAP_UprShldrFwdRr 1;
BA_ "GenSigSendType" SG_ 2155118592 PSAP_UprShldrFwdRr 12;
BA_ "GenSigSendOnInit" SG_ 2155118592 PSAP_UprShldrFwdRr 2;
BA_ "SignalType" SG_ 2155118592 PSAP_UprShldrFwdRr "UNM";
BA_ "PacketOrder" SG_ 2155118592 PSAP_UprShldrFwdRr 7;
BA_ "SignalLongName" SG_ 2155118592 PSAP_UprShldrFwdRr "Passenger Seat Actuator Priority : Upper Shoulder Forward/Rearward";
BA_ "VNSigAllNodes" SG_ 2155118592 PSAP_UprShldrFwdRr 1;
BA_ "GenSigDeltaValue" SG_ 2155118592 PSAP_HdrstTltFwdRr 1;
BA_ "GenSigSendType" SG_ 2155118592 PSAP_HdrstTltFwdRr 12;
BA_ "GenSigSendOnInit" SG_ 2155118592 PSAP_HdrstTltFwdRr 2;
BA_ "SignalType" SG_ 2155118592 PSAP_HdrstTltFwdRr "UNM";
BA_ "PacketOrder" SG_ 2155118592 PSAP_HdrstTltFwdRr 6;
BA_ "SignalLongName" SG_ 2155118592 PSAP_HdrstTltFwdRr "Passenger Seat Actuator Priority : Headrest Tilt Forward/Rearward";
BA_ "VNSigAllNodes" SG_ 2155118592 PSAP_HdrstTltFwdRr 1;
BA_ "GenSigDeltaValue" SG_ 2155118592 PSAP_HdrstWngsInOut 1;
BA_ "GenSigSendType" SG_ 2155118592 PSAP_HdrstWngsInOut 12;
BA_ "GenSigSendOnInit" SG_ 2155118592 PSAP_HdrstWngsInOut 2;
BA_ "SignalType" SG_ 2155118592 PSAP_HdrstWngsInOut "UNM";
BA_ "PacketOrder" SG_ 2155118592 PSAP_HdrstWngsInOut 5;
BA_ "SignalLongName" SG_ 2155118592 PSAP_HdrstWngsInOut "Passenger Seat Actuator Priority : Headrest Wings Inward/Outward";
BA_ "VNSigAllNodes" SG_ 2155118592 PSAP_HdrstWngsInOut 1;
BA_ "GenSigDeltaValue" SG_ 2155118592 PSAP_HdrstUpDnFdRr 1;
BA_ "GenSigSendType" SG_ 2155118592 PSAP_HdrstUpDnFdRr 12;
BA_ "GenSigSendOnInit" SG_ 2155118592 PSAP_HdrstUpDnFdRr 2;
BA_ "SignalType" SG_ 2155118592 PSAP_HdrstUpDnFdRr "UNM";
BA_ "PacketOrder" SG_ 2155118592 PSAP_HdrstUpDnFdRr 4;
BA_ "SignalLongName" SG_ 2155118592 PSAP_HdrstUpDnFdRr "Passenger Seat Actuator Priority : Headrest Up/Down and Forward/Rearward";
BA_ "VNSigAllNodes" SG_ 2155118592 PSAP_HdrstUpDnFdRr 1;
BA_ "GenSigDeltaValue" SG_ 2155118592 PSAP_HdrstFwdRrwd 1;
BA_ "GenSigSendType" SG_ 2155118592 PSAP_HdrstFwdRrwd 12;
BA_ "GenSigSendOnInit" SG_ 2155118592 PSAP_HdrstFwdRrwd 2;
BA_ "SignalType" SG_ 2155118592 PSAP_HdrstFwdRrwd "UNM";
BA_ "PacketOrder" SG_ 2155118592 PSAP_HdrstFwdRrwd 3;
BA_ "SignalLongName" SG_ 2155118592 PSAP_HdrstFwdRrwd "Passenger Seat Actuator Priority : Headrest Forward/Rearward";
BA_ "VNSigAllNodes" SG_ 2155118592 PSAP_HdrstFwdRrwd 1;
BA_ "GenSigDeltaValue" SG_ 2155118592 PSAP_HdrstUpDn 1;
BA_ "GenSigSendType" SG_ 2155118592 PSAP_HdrstUpDn 12;
BA_ "GenSigSendOnInit" SG_ 2155118592 PSAP_HdrstUpDn 2;
BA_ "SignalType" SG_ 2155118592 PSAP_HdrstUpDn "UNM";
BA_ "PacketOrder" SG_ 2155118592 PSAP_HdrstUpDn 2;
BA_ "SignalLongName" SG_ 2155118592 PSAP_HdrstUpDn "Passenger Seat Actuator Priority : Headrest Up/Down";
BA_ "VNSigAllNodes" SG_ 2155118592 PSAP_HdrstUpDn 1;
BA_ "GenSigDeltaValue" SG_ 2155118592 PSAP_Massg 1;
BA_ "GenSigSendType" SG_ 2155118592 PSAP_Massg 12;
BA_ "GenSigSendOnInit" SG_ 2155118592 PSAP_Massg 2;
BA_ "SignalType" SG_ 2155118592 PSAP_Massg "UNM";
BA_ "PacketOrder" SG_ 2155118592 PSAP_Massg 1;
BA_ "SignalLongName" SG_ 2155118592 PSAP_Massg "Passenger Seat Actuator Priority : Massage";
BA_ "VNSigAllNodes" SG_ 2155118592 PSAP_Massg 1;
BA_ "GenSigSendType" SG_ 2155102208 DSMP_UnsdRsrvd 10;
BA_ "GenSigSendOnInit" SG_ 2155102208 DSMP_UnsdRsrvd 2;
BA_ "SignalType" SG_ 2155102208 DSMP_UnsdRsrvd "BLN";
BA_ "PacketOrder" SG_ 2155102208 DSMP_UnsdRsrvd 17;
BA_ "SignalLongName" SG_ 2155102208 DSMP_UnsdRsrvd "Driver Seat Massage Priority : Unused and Reserved";
BA_ "VNSigAllNodes" SG_ 2155102208 DSMP_UnsdRsrvd 1;
BA_ "GenSigSendType" SG_ 2155102208 DSMP_MaxDispVal 12;
BA_ "GenSigSendOnInit" SG_ 2155102208 DSMP_MaxDispVal 2;
BA_ "SignalType" SG_ 2155102208 DSMP_MaxDispVal "UNM";
BA_ "PacketOrder" SG_ 2155102208 DSMP_MaxDispVal 16;
BA_ "SignalLongName" SG_ 2155102208 DSMP_MaxDispVal "Driver Seat Massage Priority : Maximum Display Value";
BA_ "VNSigAllNodes" SG_ 2155102208 DSMP_MaxDispVal 1;
BA_ "GenSigDeltaValue" SG_ 2155102208 DSMP_Type15 1;
BA_ "GenSigSendType" SG_ 2155102208 DSMP_Type15 12;
BA_ "GenSigSendOnInit" SG_ 2155102208 DSMP_Type15 2;
BA_ "SignalType" SG_ 2155102208 DSMP_Type15 "UNM";
BA_ "PacketOrder" SG_ 2155102208 DSMP_Type15 15;
BA_ "SignalLongName" SG_ 2155102208 DSMP_Type15 "Driver Seat Massage Priority : Type 15";
BA_ "VNSigAllNodes" SG_ 2155102208 DSMP_Type15 1;
BA_ "GenSigDeltaValue" SG_ 2155102208 DSMP_Type14 1;
BA_ "GenSigSendType" SG_ 2155102208 DSMP_Type14 12;
BA_ "GenSigSendOnInit" SG_ 2155102208 DSMP_Type14 2;
BA_ "SignalType" SG_ 2155102208 DSMP_Type14 "UNM";
BA_ "PacketOrder" SG_ 2155102208 DSMP_Type14 14;
BA_ "SignalLongName" SG_ 2155102208 DSMP_Type14 "Driver Seat Massage Priority : Type 14";
BA_ "VNSigAllNodes" SG_ 2155102208 DSMP_Type14 1;
BA_ "GenSigDeltaValue" SG_ 2155102208 DSMP_Type13 1;
BA_ "GenSigSendType" SG_ 2155102208 DSMP_Type13 12;
BA_ "GenSigSendOnInit" SG_ 2155102208 DSMP_Type13 2;
BA_ "SignalType" SG_ 2155102208 DSMP_Type13 "UNM";
BA_ "PacketOrder" SG_ 2155102208 DSMP_Type13 13;
BA_ "SignalLongName" SG_ 2155102208 DSMP_Type13 "Driver Seat Massage Priority : Type 13";
BA_ "VNSigAllNodes" SG_ 2155102208 DSMP_Type13 1;
BA_ "GenSigDeltaValue" SG_ 2155102208 DSMP_Type12 1;
BA_ "GenSigSendType" SG_ 2155102208 DSMP_Type12 12;
BA_ "GenSigSendOnInit" SG_ 2155102208 DSMP_Type12 2;
BA_ "SignalType" SG_ 2155102208 DSMP_Type12 "UNM";
BA_ "PacketOrder" SG_ 2155102208 DSMP_Type12 12;
BA_ "SignalLongName" SG_ 2155102208 DSMP_Type12 "Driver Seat Massage Priority : Type 12";
BA_ "VNSigAllNodes" SG_ 2155102208 DSMP_Type12 1;
BA_ "GenSigDeltaValue" SG_ 2155102208 DSMP_Type11 1;
BA_ "GenSigSendType" SG_ 2155102208 DSMP_Type11 12;
BA_ "GenSigSendOnInit" SG_ 2155102208 DSMP_Type11 2;
BA_ "SignalType" SG_ 2155102208 DSMP_Type11 "UNM";
BA_ "PacketOrder" SG_ 2155102208 DSMP_Type11 11;
BA_ "SignalLongName" SG_ 2155102208 DSMP_Type11 "Driver Seat Massage Priority : Type 11";
BA_ "VNSigAllNodes" SG_ 2155102208 DSMP_Type11 1;
BA_ "GenSigDeltaValue" SG_ 2155102208 DSMP_Type10 1;
BA_ "GenSigSendType" SG_ 2155102208 DSMP_Type10 12;
BA_ "GenSigSendOnInit" SG_ 2155102208 DSMP_Type10 2;
BA_ "SignalType" SG_ 2155102208 DSMP_Type10 "UNM";
BA_ "PacketOrder" SG_ 2155102208 DSMP_Type10 10;
BA_ "SignalLongName" SG_ 2155102208 DSMP_Type10 "Driver Seat Massage Priority : Type 10";
BA_ "VNSigAllNodes" SG_ 2155102208 DSMP_Type10 1;
BA_ "GenSigDeltaValue" SG_ 2155102208 DSMP_Type9 1;
BA_ "GenSigSendType" SG_ 2155102208 DSMP_Type9 12;
BA_ "GenSigSendOnInit" SG_ 2155102208 DSMP_Type9 2;
BA_ "SignalType" SG_ 2155102208 DSMP_Type9 "UNM";
BA_ "PacketOrder" SG_ 2155102208 DSMP_Type9 9;
BA_ "SignalLongName" SG_ 2155102208 DSMP_Type9 "Driver Seat Massage Priority : Type 9";
BA_ "VNSigAllNodes" SG_ 2155102208 DSMP_Type9 1;
BA_ "GenSigDeltaValue" SG_ 2155102208 DSMP_Type8 1;
BA_ "GenSigSendType" SG_ 2155102208 DSMP_Type8 12;
BA_ "GenSigSendOnInit" SG_ 2155102208 DSMP_Type8 2;
BA_ "SignalType" SG_ 2155102208 DSMP_Type8 "UNM";
BA_ "PacketOrder" SG_ 2155102208 DSMP_Type8 8;
BA_ "SignalLongName" SG_ 2155102208 DSMP_Type8 "Driver Seat Massage Priority : Type 8";
BA_ "VNSigAllNodes" SG_ 2155102208 DSMP_Type8 1;
BA_ "GenSigDeltaValue" SG_ 2155102208 DSMP_Type7 1;
BA_ "GenSigSendType" SG_ 2155102208 DSMP_Type7 12;
BA_ "GenSigSendOnInit" SG_ 2155102208 DSMP_Type7 2;
BA_ "SignalType" SG_ 2155102208 DSMP_Type7 "UNM";
BA_ "PacketOrder" SG_ 2155102208 DSMP_Type7 7;
BA_ "SignalLongName" SG_ 2155102208 DSMP_Type7 "Driver Seat Massage Priority : Type 7";
BA_ "VNSigAllNodes" SG_ 2155102208 DSMP_Type7 1;
BA_ "GenSigDeltaValue" SG_ 2155102208 DSMP_Type6 1;
BA_ "GenSigSendType" SG_ 2155102208 DSMP_Type6 12;
BA_ "GenSigSendOnInit" SG_ 2155102208 DSMP_Type6 2;
BA_ "SignalType" SG_ 2155102208 DSMP_Type6 "UNM";
BA_ "PacketOrder" SG_ 2155102208 DSMP_Type6 6;
BA_ "SignalLongName" SG_ 2155102208 DSMP_Type6 "Driver Seat Massage Priority : Type 6";
BA_ "VNSigAllNodes" SG_ 2155102208 DSMP_Type6 1;
BA_ "GenSigDeltaValue" SG_ 2155102208 DSMP_Type5 1;
BA_ "GenSigSendType" SG_ 2155102208 DSMP_Type5 12;
BA_ "GenSigSendOnInit" SG_ 2155102208 DSMP_Type5 2;
BA_ "SignalType" SG_ 2155102208 DSMP_Type5 "UNM";
BA_ "PacketOrder" SG_ 2155102208 DSMP_Type5 5;
BA_ "SignalLongName" SG_ 2155102208 DSMP_Type5 "Driver Seat Massage Priority : Type 5";
BA_ "VNSigAllNodes" SG_ 2155102208 DSMP_Type5 1;
BA_ "GenSigDeltaValue" SG_ 2155102208 DSMP_Type4 1;
BA_ "GenSigSendType" SG_ 2155102208 DSMP_Type4 12;
BA_ "GenSigSendOnInit" SG_ 2155102208 DSMP_Type4 2;
BA_ "SignalType" SG_ 2155102208 DSMP_Type4 "UNM";
BA_ "PacketOrder" SG_ 2155102208 DSMP_Type4 4;
BA_ "SignalLongName" SG_ 2155102208 DSMP_Type4 "Driver Seat Massage Priority : Type 4";
BA_ "VNSigAllNodes" SG_ 2155102208 DSMP_Type4 1;
BA_ "GenSigDeltaValue" SG_ 2155102208 DSMP_Type3 1;
BA_ "GenSigSendType" SG_ 2155102208 DSMP_Type3 12;
BA_ "GenSigSendOnInit" SG_ 2155102208 DSMP_Type3 2;
BA_ "SignalType" SG_ 2155102208 DSMP_Type3 "UNM";
BA_ "PacketOrder" SG_ 2155102208 DSMP_Type3 3;
BA_ "SignalLongName" SG_ 2155102208 DSMP_Type3 "Driver Seat Massage Priority : Type 3";
BA_ "VNSigAllNodes" SG_ 2155102208 DSMP_Type3 1;
BA_ "GenSigDeltaValue" SG_ 2155102208 DSMP_Type2 1;
BA_ "GenSigSendType" SG_ 2155102208 DSMP_Type2 12;
BA_ "GenSigSendOnInit" SG_ 2155102208 DSMP_Type2 2;
BA_ "SignalType" SG_ 2155102208 DSMP_Type2 "UNM";
BA_ "PacketOrder" SG_ 2155102208 DSMP_Type2 2;
BA_ "SignalLongName" SG_ 2155102208 DSMP_Type2 "Driver Seat Massage Priority : Type 2";
BA_ "VNSigAllNodes" SG_ 2155102208 DSMP_Type2 1;
BA_ "GenSigDeltaValue" SG_ 2155102208 DSMP_Type1 1;
BA_ "GenSigSendType" SG_ 2155102208 DSMP_Type1 12;
BA_ "GenSigSendOnInit" SG_ 2155102208 DSMP_Type1 2;
BA_ "SignalType" SG_ 2155102208 DSMP_Type1 "UNM";
BA_ "PacketOrder" SG_ 2155102208 DSMP_Type1 1;
BA_ "SignalLongName" SG_ 2155102208 DSMP_Type1 "Driver Seat Massage Priority : Type 1";
BA_ "VNSigAllNodes" SG_ 2155102208 DSMP_Type1 1;
BA_ "GenSigDeltaValue" SG_ 2155085824 StrgColUpDwnPos 1;
BA_ "GenSigSendType" SG_ 2155085824 StrgColUpDwnPos 12;
BA_ "GenSigSendOnInit" SG_ 2155085824 StrgColUpDwnPos 2;
BA_ "SignalType" SG_ 2155085824 StrgColUpDwnPos "UNM";
BA_ "SignalLongName" SG_ 2155085824 StrgColUpDwnPos "Steering Column Up Down Position";
BA_ "VNSigAllNodes" SG_ 2155085824 StrgColUpDwnPos 1;
BA_ "GenSigSendType" SG_ 2155085824 CPMAPINFO4 10;
BA_ "GenSigSendOnInit" SG_ 2155085824 CPMAPINFO4 2;
BA_ "SignalType" SG_ 2155085824 CPMAPINFO4 "ENM";
BA_ "SignalLongName" SG_ 2155085824 CPMAPINFO4 "Steering Column Internal Fault";
BA_ "VNSigAllNodes" SG_ 2155085824 CPMAPINFO4 1;
BA_ "GenSigDeltaValue" SG_ 2155085824 StrgColInOutPos 1;
BA_ "GenSigSendType" SG_ 2155085824 StrgColInOutPos 12;
BA_ "GenSigSendOnInit" SG_ 2155085824 StrgColInOutPos 2;
BA_ "SignalType" SG_ 2155085824 StrgColInOutPos "UNM";
BA_ "SignalLongName" SG_ 2155085824 StrgColInOutPos "Steering Column In Out Position";
BA_ "VNSigAllNodes" SG_ 2155085824 StrgColInOutPos 1;
BA_ "GenSigSendType" SG_ 2155085824 StrgColCommsFlt 10;
BA_ "GenSigSendOnInit" SG_ 2155085824 StrgColCommsFlt 2;
BA_ "SignalType" SG_ 2155085824 StrgColCommsFlt "ENM";
BA_ "SignalLongName" SG_ 2155085824 StrgColCommsFlt "Steering Column Communications Fault";
BA_ "VNSigAllNodes" SG_ 2155085824 StrgColCommsFlt 1;
BA_ "GenSigSendType" SG_ 2155085824 DSCDS_UnsdRsrvd 12;
BA_ "GenSigSendOnInit" SG_ 2155085824 DSCDS_UnsdRsrvd 2;
BA_ "SignalType" SG_ 2155085824 DSCDS_UnsdRsrvd "UNM";
BA_ "PacketOrder" SG_ 2155085824 DSCDS_UnsdRsrvd 19;
BA_ "SignalLongName" SG_ 2155085824 DSCDS_UnsdRsrvd "Driver Seat Control Display Status : Unused and Reserved";
BA_ "VNSigAllNodes" SG_ 2155085824 DSCDS_UnsdRsrvd 1;
BA_ "GenSigSendType" SG_ 2155085824 DSCDS_DispReq 10;
BA_ "GenSigSendOnInit" SG_ 2155085824 DSCDS_DispReq 2;
BA_ "SignalType" SG_ 2155085824 DSCDS_DispReq "BLN";
BA_ "PacketOrder" SG_ 2155085824 DSCDS_DispReq 18;
BA_ "SignalLongName" SG_ 2155085824 DSCDS_DispReq "Driver Seat Control Display Status : Display Request";
BA_ "VNSigAllNodes" SG_ 2155085824 DSCDS_DispReq 1;
BA_ "GenSigSendType" SG_ 2155085824 DSCDS_DispSz 10;
BA_ "GenSigSendOnInit" SG_ 2155085824 DSCDS_DispSz 2;
BA_ "SignalType" SG_ 2155085824 DSCDS_DispSz "ENM";
BA_ "PacketOrder" SG_ 2155085824 DSCDS_DispSz 17;
BA_ "SignalLongName" SG_ 2155085824 DSCDS_DispSz "Driver Seat Control Display Status : Display Size";
BA_ "VNSigAllNodes" SG_ 2155085824 DSCDS_DispSz 1;
BA_ "GenSigSendType" SG_ 2155085824 DSCDS_CshLgAdjFdRr 10;
BA_ "GenSigSendOnInit" SG_ 2155085824 DSCDS_CshLgAdjFdRr 2;
BA_ "SignalType" SG_ 2155085824 DSCDS_CshLgAdjFdRr "ENM";
BA_ "PacketOrder" SG_ 2155085824 DSCDS_CshLgAdjFdRr 16;
BA_ "SignalLongName" SG_ 2155085824 DSCDS_CshLgAdjFdRr "Driver Seat Control Display Status : Cushion Length Adjustment Forward/Rearward";
BA_ "VNSigAllNodes" SG_ 2155085824 DSCDS_CshLgAdjFdRr 1;
BA_ "GenSigSendType" SG_ 2155085824 DSCDS_BkCshBlstInOt 10;
BA_ "GenSigSendOnInit" SG_ 2155085824 DSCDS_BkCshBlstInOt 2;
BA_ "SignalType" SG_ 2155085824 DSCDS_BkCshBlstInOt "ENM";
BA_ "PacketOrder" SG_ 2155085824 DSCDS_BkCshBlstInOt 15;
BA_ "SignalLongName" SG_ 2155085824 DSCDS_BkCshBlstInOt "Driver Seat Control Display Status : Back and Cushion Bolster In/Out";
BA_ "VNSigAllNodes" SG_ 2155085824 DSCDS_BkCshBlstInOt 1;
BA_ "GenSigSendType" SG_ 2155085824 DSCDS_CshBlstrInOut 10;
BA_ "GenSigSendOnInit" SG_ 2155085824 DSCDS_CshBlstrInOut 2;
BA_ "SignalType" SG_ 2155085824 DSCDS_CshBlstrInOut "ENM";
BA_ "PacketOrder" SG_ 2155085824 DSCDS_CshBlstrInOut 14;
BA_ "SignalLongName" SG_ 2155085824 DSCDS_CshBlstrInOut "Driver Seat Control Display Status : Cushion Bolster In/Out";
BA_ "VNSigAllNodes" SG_ 2155085824 DSCDS_CshBlstrInOut 1;
BA_ "GenSigSendType" SG_ 2155085824 DSCDS_BkBlstrInOut 10;
BA_ "GenSigSendOnInit" SG_ 2155085824 DSCDS_BkBlstrInOut 2;
BA_ "SignalType" SG_ 2155085824 DSCDS_BkBlstrInOut "ENM";
BA_ "PacketOrder" SG_ 2155085824 DSCDS_BkBlstrInOut 13;
BA_ "SignalLongName" SG_ 2155085824 DSCDS_BkBlstrInOut "Driver Seat Control Display Status : Back Bolster In/Out";
BA_ "VNSigAllNodes" SG_ 2155085824 DSCDS_BkBlstrInOut 1;
BA_ "GenSigSendType" SG_ 2155085824 DSCDS_LmbrUDnFdRr 10;
BA_ "GenSigSendOnInit" SG_ 2155085824 DSCDS_LmbrUDnFdRr 2;
BA_ "SignalType" SG_ 2155085824 DSCDS_LmbrUDnFdRr "ENM";
BA_ "PacketOrder" SG_ 2155085824 DSCDS_LmbrUDnFdRr 12;
BA_ "SignalLongName" SG_ 2155085824 DSCDS_LmbrUDnFdRr "Driver Seat Control Display Status : Lumbar Up/Down and Forward/Rearward";
BA_ "VNSigAllNodes" SG_ 2155085824 DSCDS_LmbrUDnFdRr 1;
BA_ "GenSigSendType" SG_ 2155085824 DSCDS_LmbrFwdRr 10;
BA_ "GenSigSendOnInit" SG_ 2155085824 DSCDS_LmbrFwdRr 2;
BA_ "SignalType" SG_ 2155085824 DSCDS_LmbrFwdRr "ENM";
BA_ "PacketOrder" SG_ 2155085824 DSCDS_LmbrFwdRr 11;
BA_ "SignalLongName" SG_ 2155085824 DSCDS_LmbrFwdRr "Driver Seat Control Display Status : Lumbar Forward/Rearward";
BA_ "VNSigAllNodes" SG_ 2155085824 DSCDS_LmbrFwdRr 1;
BA_ "GenSigSendType" SG_ 2155085824 DSCDS_LmbrUpDwn 10;
BA_ "GenSigSendOnInit" SG_ 2155085824 DSCDS_LmbrUpDwn 2;
BA_ "SignalType" SG_ 2155085824 DSCDS_LmbrUpDwn "ENM";
BA_ "PacketOrder" SG_ 2155085824 DSCDS_LmbrUpDwn 10;
BA_ "SignalLongName" SG_ 2155085824 DSCDS_LmbrUpDwn "Driver Seat Control Display Status : Lumbar Up/Down";
BA_ "VNSigAllNodes" SG_ 2155085824 DSCDS_LmbrUpDwn 1;
BA_ "GenSigSendType" SG_ 2155085824 DSCDS_UprShldrFdRr 10;
BA_ "GenSigSendOnInit" SG_ 2155085824 DSCDS_UprShldrFdRr 2;
BA_ "SignalType" SG_ 2155085824 DSCDS_UprShldrFdRr "ENM";
BA_ "PacketOrder" SG_ 2155085824 DSCDS_UprShldrFdRr 9;
BA_ "SignalLongName" SG_ 2155085824 DSCDS_UprShldrFdRr "Driver Seat Control Display Status : Upper Shoulder Forward/Rearward";
BA_ "VNSigAllNodes" SG_ 2155085824 DSCDS_UprShldrFdRr 1;
BA_ "GenSigSendType" SG_ 2155085824 DSCDS_HdrstTltFwdRr 10;
BA_ "GenSigSendOnInit" SG_ 2155085824 DSCDS_HdrstTltFwdRr 2;
BA_ "SignalType" SG_ 2155085824 DSCDS_HdrstTltFwdRr "ENM";
BA_ "PacketOrder" SG_ 2155085824 DSCDS_HdrstTltFwdRr 8;
BA_ "SignalLongName" SG_ 2155085824 DSCDS_HdrstTltFwdRr "Driver Seat Control Display Status : Headrest Tilt Forward/Rearward";
BA_ "VNSigAllNodes" SG_ 2155085824 DSCDS_HdrstTltFwdRr 1;
BA_ "GenSigSendType" SG_ 2155085824 DSCDS_HdrstWngInOt 10;
BA_ "GenSigSendOnInit" SG_ 2155085824 DSCDS_HdrstWngInOt 2;
BA_ "SignalType" SG_ 2155085824 DSCDS_HdrstWngInOt "ENM";
BA_ "PacketOrder" SG_ 2155085824 DSCDS_HdrstWngInOt 7;
BA_ "SignalLongName" SG_ 2155085824 DSCDS_HdrstWngInOt "Driver Seat Control Display Status : Headrest Wings In/Out";
BA_ "VNSigAllNodes" SG_ 2155085824 DSCDS_HdrstWngInOt 1;
BA_ "GenSigSendType" SG_ 2155085824 DSCDS_HdrstUDnFdRr 10;
BA_ "GenSigSendOnInit" SG_ 2155085824 DSCDS_HdrstUDnFdRr 2;
BA_ "SignalType" SG_ 2155085824 DSCDS_HdrstUDnFdRr "ENM";
BA_ "PacketOrder" SG_ 2155085824 DSCDS_HdrstUDnFdRr 6;
BA_ "SignalLongName" SG_ 2155085824 DSCDS_HdrstUDnFdRr "Driver Seat Control Display Status : Headrest Forward/Rearward and Up/Down";
BA_ "VNSigAllNodes" SG_ 2155085824 DSCDS_HdrstUDnFdRr 1;
BA_ "GenSigSendType" SG_ 2155085824 DSCDS_HdrstFwdRrwd 10;
BA_ "GenSigSendOnInit" SG_ 2155085824 DSCDS_HdrstFwdRrwd 2;
BA_ "SignalType" SG_ 2155085824 DSCDS_HdrstFwdRrwd "ENM";
BA_ "PacketOrder" SG_ 2155085824 DSCDS_HdrstFwdRrwd 5;
BA_ "SignalLongName" SG_ 2155085824 DSCDS_HdrstFwdRrwd "Driver Seat Control Display Status : Headrest Forward/Rearward";
BA_ "VNSigAllNodes" SG_ 2155085824 DSCDS_HdrstFwdRrwd 1;
BA_ "GenSigSendType" SG_ 2155085824 DSCDS_HdrstUpDn 10;
BA_ "GenSigSendOnInit" SG_ 2155085824 DSCDS_HdrstUpDn 2;
BA_ "SignalType" SG_ 2155085824 DSCDS_HdrstUpDn "ENM";
BA_ "PacketOrder" SG_ 2155085824 DSCDS_HdrstUpDn 4;
BA_ "SignalLongName" SG_ 2155085824 DSCDS_HdrstUpDn "Driver Seat Control Display Status : Headrest Up/Down";
BA_ "VNSigAllNodes" SG_ 2155085824 DSCDS_HdrstUpDn 1;
BA_ "GenSigSendType" SG_ 2155085824 DSCDS_MassgIntsty 10;
BA_ "GenSigSendOnInit" SG_ 2155085824 DSCDS_MassgIntsty 2;
BA_ "SignalType" SG_ 2155085824 DSCDS_MassgIntsty "ENM";
BA_ "PacketOrder" SG_ 2155085824 DSCDS_MassgIntsty 3;
BA_ "SignalLongName" SG_ 2155085824 DSCDS_MassgIntsty "Driver Seat Control Display Status : Massage Intensity";
BA_ "VNSigAllNodes" SG_ 2155085824 DSCDS_MassgIntsty 1;
BA_ "GenSigSendType" SG_ 2155085824 DSCDS_MassgTyp 10;
BA_ "GenSigSendOnInit" SG_ 2155085824 DSCDS_MassgTyp 2;
BA_ "SignalType" SG_ 2155085824 DSCDS_MassgTyp "ENM";
BA_ "PacketOrder" SG_ 2155085824 DSCDS_MassgTyp 2;
BA_ "SignalLongName" SG_ 2155085824 DSCDS_MassgTyp "Driver Seat Control Display Status : Massage Type";
BA_ "VNSigAllNodes" SG_ 2155085824 DSCDS_MassgTyp 1;
BA_ "GenSigSendType" SG_ 2155085824 DSCDS_Massg 10;
BA_ "GenSigSendOnInit" SG_ 2155085824 DSCDS_Massg 2;
BA_ "SignalType" SG_ 2155085824 DSCDS_Massg "ENM";
BA_ "PacketOrder" SG_ 2155085824 DSCDS_Massg 1;
BA_ "SignalLongName" SG_ 2155085824 DSCDS_Massg "Driver Seat Control Display Status : Massage";
BA_ "VNSigAllNodes" SG_ 2155085824 DSCDS_Massg 1;
BA_ "GenSigDeltaValue" SG_ 2155069440 DSAP_UnsdRsrvd 1;
BA_ "GenSigSendType" SG_ 2155069440 DSAP_UnsdRsrvd 12;
BA_ "GenSigSendOnInit" SG_ 2155069440 DSAP_UnsdRsrvd 2;
BA_ "SignalType" SG_ 2155069440 DSAP_UnsdRsrvd "UNM";
BA_ "PacketOrder" SG_ 2155069440 DSAP_UnsdRsrvd 16;
BA_ "SignalLongName" SG_ 2155069440 DSAP_UnsdRsrvd "Driver Seat Actuator Priority : Unused and Reserved";
BA_ "VNSigAllNodes" SG_ 2155069440 DSAP_UnsdRsrvd 1;
BA_ "GenSigDeltaValue" SG_ 2155069440 DSAP_DispSz 1;
BA_ "GenSigSendType" SG_ 2155069440 DSAP_DispSz 12;
BA_ "GenSigSendOnInit" SG_ 2155069440 DSAP_DispSz 2;
BA_ "SignalType" SG_ 2155069440 DSAP_DispSz "UNM";
BA_ "PacketOrder" SG_ 2155069440 DSAP_DispSz 15;
BA_ "SignalLongName" SG_ 2155069440 DSAP_DispSz "Driver Seat Actuator Priority : Display Size";
BA_ "VNSigAllNodes" SG_ 2155069440 DSAP_DispSz 1;
BA_ "GenSigDeltaValue" SG_ 2155069440 DSAP_CshLgthAdjFdRr 1;
BA_ "GenSigSendType" SG_ 2155069440 DSAP_CshLgthAdjFdRr 12;
BA_ "GenSigSendOnInit" SG_ 2155069440 DSAP_CshLgthAdjFdRr 2;
BA_ "SignalType" SG_ 2155069440 DSAP_CshLgthAdjFdRr "UNM";
BA_ "PacketOrder" SG_ 2155069440 DSAP_CshLgthAdjFdRr 14;
BA_ "SignalLongName" SG_ 2155069440 DSAP_CshLgthAdjFdRr "Driver Seat Actuator Priority : Cushion Length Adjustment Forward/Rearward";
BA_ "VNSigAllNodes" SG_ 2155069440 DSAP_CshLgthAdjFdRr 1;
BA_ "GenSigDeltaValue" SG_ 2155069440 DSAP_BkCshBlstrInOut 1;
BA_ "GenSigSendType" SG_ 2155069440 DSAP_BkCshBlstrInOut 12;
BA_ "GenSigSendOnInit" SG_ 2155069440 DSAP_BkCshBlstrInOut 2;
BA_ "SignalType" SG_ 2155069440 DSAP_BkCshBlstrInOut "UNM";
BA_ "PacketOrder" SG_ 2155069440 DSAP_BkCshBlstrInOut 13;
BA_ "SignalLongName" SG_ 2155069440 DSAP_BkCshBlstrInOut "Driver Seat Actuator Priority : Back and Cushion Bolster In/Out";
BA_ "VNSigAllNodes" SG_ 2155069440 DSAP_BkCshBlstrInOut 1;
BA_ "GenSigDeltaValue" SG_ 2155069440 DSAP_CshBlstrInOut 1;
BA_ "GenSigSendType" SG_ 2155069440 DSAP_CshBlstrInOut 12;
BA_ "GenSigSendOnInit" SG_ 2155069440 DSAP_CshBlstrInOut 2;
BA_ "SignalType" SG_ 2155069440 DSAP_CshBlstrInOut "UNM";
BA_ "PacketOrder" SG_ 2155069440 DSAP_CshBlstrInOut 12;
BA_ "SignalLongName" SG_ 2155069440 DSAP_CshBlstrInOut "Driver Seat Actuator Priority : Cushion Bolster In/Out";
BA_ "VNSigAllNodes" SG_ 2155069440 DSAP_CshBlstrInOut 1;
BA_ "GenSigDeltaValue" SG_ 2155069440 DSAP_BkBlstrInOut 1;
BA_ "GenSigSendType" SG_ 2155069440 DSAP_BkBlstrInOut 12;
BA_ "GenSigSendOnInit" SG_ 2155069440 DSAP_BkBlstrInOut 2;
BA_ "SignalType" SG_ 2155069440 DSAP_BkBlstrInOut "UNM";
BA_ "PacketOrder" SG_ 2155069440 DSAP_BkBlstrInOut 11;
BA_ "SignalLongName" SG_ 2155069440 DSAP_BkBlstrInOut "Driver Seat Actuator Priority : Back Bolster In/Out";
BA_ "VNSigAllNodes" SG_ 2155069440 DSAP_BkBlstrInOut 1;
BA_ "GenSigDeltaValue" SG_ 2155069440 DSAP_LmbrUpDnFdRr 1;
BA_ "GenSigSendType" SG_ 2155069440 DSAP_LmbrUpDnFdRr 12;
BA_ "GenSigSendOnInit" SG_ 2155069440 DSAP_LmbrUpDnFdRr 2;
BA_ "SignalType" SG_ 2155069440 DSAP_LmbrUpDnFdRr "UNM";
BA_ "PacketOrder" SG_ 2155069440 DSAP_LmbrUpDnFdRr 10;
BA_ "SignalLongName" SG_ 2155069440 DSAP_LmbrUpDnFdRr "Driver Seat Actuator Priority : Lumbar Up/Down and Forward/Rearward";
BA_ "VNSigAllNodes" SG_ 2155069440 DSAP_LmbrUpDnFdRr 1;
BA_ "GenSigDeltaValue" SG_ 2155069440 DSAP_LmbrFwdRr 1;
BA_ "GenSigSendType" SG_ 2155069440 DSAP_LmbrFwdRr 12;
BA_ "GenSigSendOnInit" SG_ 2155069440 DSAP_LmbrFwdRr 2;
BA_ "SignalType" SG_ 2155069440 DSAP_LmbrFwdRr "UNM";
BA_ "PacketOrder" SG_ 2155069440 DSAP_LmbrFwdRr 9;
BA_ "SignalLongName" SG_ 2155069440 DSAP_LmbrFwdRr "Driver Seat Actuator Priority : Lumbar Forward/Rearward";
BA_ "VNSigAllNodes" SG_ 2155069440 DSAP_LmbrFwdRr 1;
BA_ "GenSigDeltaValue" SG_ 2155069440 DSAP_LmbrUpDwn 1;
BA_ "GenSigSendType" SG_ 2155069440 DSAP_LmbrUpDwn 12;
BA_ "GenSigSendOnInit" SG_ 2155069440 DSAP_LmbrUpDwn 2;
BA_ "SignalType" SG_ 2155069440 DSAP_LmbrUpDwn "UNM";
BA_ "PacketOrder" SG_ 2155069440 DSAP_LmbrUpDwn 8;
BA_ "SignalLongName" SG_ 2155069440 DSAP_LmbrUpDwn "Driver Seat Actuator Priority : Lumbar Up/Down";
BA_ "VNSigAllNodes" SG_ 2155069440 DSAP_LmbrUpDwn 1;
BA_ "GenSigDeltaValue" SG_ 2155069440 DSAP_UprShldrFwdRr 1;
BA_ "GenSigSendType" SG_ 2155069440 DSAP_UprShldrFwdRr 12;
BA_ "GenSigSendOnInit" SG_ 2155069440 DSAP_UprShldrFwdRr 2;
BA_ "SignalType" SG_ 2155069440 DSAP_UprShldrFwdRr "UNM";
BA_ "PacketOrder" SG_ 2155069440 DSAP_UprShldrFwdRr 7;
BA_ "SignalLongName" SG_ 2155069440 DSAP_UprShldrFwdRr "Driver Seat Actuator Priority : Upper Shoulder Forward/Rearward";
BA_ "VNSigAllNodes" SG_ 2155069440 DSAP_UprShldrFwdRr 1;
BA_ "GenSigDeltaValue" SG_ 2155069440 DSAP_HdrstTltFwdRr 1;
BA_ "GenSigSendType" SG_ 2155069440 DSAP_HdrstTltFwdRr 12;
BA_ "GenSigSendOnInit" SG_ 2155069440 DSAP_HdrstTltFwdRr 2;
BA_ "SignalType" SG_ 2155069440 DSAP_HdrstTltFwdRr "UNM";
BA_ "PacketOrder" SG_ 2155069440 DSAP_HdrstTltFwdRr 6;
BA_ "SignalLongName" SG_ 2155069440 DSAP_HdrstTltFwdRr "Driver Seat Actuator Priority : Headrest Tilt Forward/Rearward";
BA_ "VNSigAllNodes" SG_ 2155069440 DSAP_HdrstTltFwdRr 1;
BA_ "GenSigDeltaValue" SG_ 2155069440 DSAP_HdrstWngsInOut 1;
BA_ "GenSigSendType" SG_ 2155069440 DSAP_HdrstWngsInOut 12;
BA_ "GenSigSendOnInit" SG_ 2155069440 DSAP_HdrstWngsInOut 2;
BA_ "SignalType" SG_ 2155069440 DSAP_HdrstWngsInOut "UNM";
BA_ "PacketOrder" SG_ 2155069440 DSAP_HdrstWngsInOut 5;
BA_ "SignalLongName" SG_ 2155069440 DSAP_HdrstWngsInOut "Driver Seat Actuator Priority : Headrest Wings Inward/Outward";
BA_ "VNSigAllNodes" SG_ 2155069440 DSAP_HdrstWngsInOut 1;
BA_ "GenSigDeltaValue" SG_ 2155069440 DSAP_HdrstUpDnFdRr 1;
BA_ "GenSigSendType" SG_ 2155069440 DSAP_HdrstUpDnFdRr 12;
BA_ "GenSigSendOnInit" SG_ 2155069440 DSAP_HdrstUpDnFdRr 2;
BA_ "SignalType" SG_ 2155069440 DSAP_HdrstUpDnFdRr "UNM";
BA_ "PacketOrder" SG_ 2155069440 DSAP_HdrstUpDnFdRr 4;
BA_ "SignalLongName" SG_ 2155069440 DSAP_HdrstUpDnFdRr "Driver Seat Actuator Priority : Headrest Up/Down and Forward/Rearward";
BA_ "VNSigAllNodes" SG_ 2155069440 DSAP_HdrstUpDnFdRr 1;
BA_ "GenSigDeltaValue" SG_ 2155069440 DSAP_HdrstFwdRrwd 1;
BA_ "GenSigSendType" SG_ 2155069440 DSAP_HdrstFwdRrwd 12;
BA_ "GenSigSendOnInit" SG_ 2155069440 DSAP_HdrstFwdRrwd 2;
BA_ "SignalType" SG_ 2155069440 DSAP_HdrstFwdRrwd "UNM";
BA_ "PacketOrder" SG_ 2155069440 DSAP_HdrstFwdRrwd 3;
BA_ "SignalLongName" SG_ 2155069440 DSAP_HdrstFwdRrwd "Driver Seat Actuator Priority : Headrest Forward/Rearward";
BA_ "VNSigAllNodes" SG_ 2155069440 DSAP_HdrstFwdRrwd 1;
BA_ "GenSigDeltaValue" SG_ 2155069440 DSAP_HdrstUpDn 1;
BA_ "GenSigSendType" SG_ 2155069440 DSAP_HdrstUpDn 12;
BA_ "GenSigSendOnInit" SG_ 2155069440 DSAP_HdrstUpDn 2;
BA_ "SignalType" SG_ 2155069440 DSAP_HdrstUpDn "UNM";
BA_ "PacketOrder" SG_ 2155069440 DSAP_HdrstUpDn 2;
BA_ "SignalLongName" SG_ 2155069440 DSAP_HdrstUpDn "Driver Seat Actuator Priority : Headrest Up/Down";
BA_ "VNSigAllNodes" SG_ 2155069440 DSAP_HdrstUpDn 1;
BA_ "GenSigDeltaValue" SG_ 2155069440 DSAP_Massg 1;
BA_ "GenSigSendType" SG_ 2155069440 DSAP_Massg 12;
BA_ "GenSigSendOnInit" SG_ 2155069440 DSAP_Massg 2;
BA_ "SignalType" SG_ 2155069440 DSAP_Massg "UNM";
BA_ "PacketOrder" SG_ 2155069440 DSAP_Massg 1;
BA_ "SignalLongName" SG_ 2155069440 DSAP_Massg "Driver Seat Actuator Priority : Massage";
BA_ "VNSigAllNodes" SG_ 2155069440 DSAP_Massg 1;
BA_ "GenSigSendType" SG_ 2156937216 WiFiPssPhrsDgts17to24 10;
BA_ "GenSigSendOnInit" SG_ 2156937216 WiFiPssPhrsDgts17to24 2;
BA_ "SignalType" SG_ 2156937216 WiFiPssPhrsDgts17to24 "ASC";
BA_ "SignalLongName" SG_ 2156937216 WiFiPssPhrsDgts17to24 "WiFi Pass Phrase Digits 17 to 24";
BA_ "VNSigAllNodes" SG_ 2156937216 WiFiPssPhrsDgts17to24 1;
BA_ "GenSigSendType" SG_ 2156929024 WiFiPssPhrsDgts9to16 10;
BA_ "GenSigSendOnInit" SG_ 2156929024 WiFiPssPhrsDgts9to16 2;
BA_ "SignalType" SG_ 2156929024 WiFiPssPhrsDgts9to16 "ASC";
BA_ "SignalLongName" SG_ 2156929024 WiFiPssPhrsDgts9to16 "WiFi Pass Phrase Digits 9 to 16";
BA_ "VNSigAllNodes" SG_ 2156929024 WiFiPssPhrsDgts9to16 1;
BA_ "GenSigSendType" SG_ 2156920832 WiFiPssPhrsDgts1to8 10;
BA_ "GenSigSendOnInit" SG_ 2156920832 WiFiPssPhrsDgts1to8 2;
BA_ "SignalType" SG_ 2156920832 WiFiPssPhrsDgts1to8 "ASC";
BA_ "SignalLongName" SG_ 2156920832 WiFiPssPhrsDgts1to8 "WiFi Pass Phrase Digits 1 to 8";
BA_ "VNSigAllNodes" SG_ 2156920832 WiFiPssPhrsDgts1to8 1;
BA_ "GenSigSendType" SG_ 2156871680 WiFiSSIDDgts17to24 10;
BA_ "GenSigSendOnInit" SG_ 2156871680 WiFiSSIDDgts17to24 2;
BA_ "SignalType" SG_ 2156871680 WiFiSSIDDgts17to24 "ASC";
BA_ "SignalLongName" SG_ 2156871680 WiFiSSIDDgts17to24 "WiFi Service Set Identifier Digits 17 to 24";
BA_ "VNSigAllNodes" SG_ 2156871680 WiFiSSIDDgts17to24 1;
BA_ "GenSigSendType" SG_ 2156863488 WiFiSSIDDgts9to16 10;
BA_ "GenSigSendOnInit" SG_ 2156863488 WiFiSSIDDgts9to16 2;
BA_ "SignalType" SG_ 2156863488 WiFiSSIDDgts9to16 "ASC";
BA_ "SignalLongName" SG_ 2156863488 WiFiSSIDDgts9to16 "WiFi Service Set Identifier Digits 9 to 16";
BA_ "VNSigAllNodes" SG_ 2156863488 WiFiSSIDDgts9to16 1;
BA_ "GenSigSendType" SG_ 2156855296 WiFiSSIDDgts1to8 10;
BA_ "GenSigSendOnInit" SG_ 2156855296 WiFiSSIDDgts1to8 2;
BA_ "SignalType" SG_ 2156855296 WiFiSSIDDgts1to8 "ASC";
BA_ "SignalLongName" SG_ 2156855296 WiFiSSIDDgts1to8 "WiFi Service Set Identifier Digits 1 to 8";
BA_ "VNSigAllNodes" SG_ 2156855296 WiFiSSIDDgts1to8 1;
BA_ "GenSigDeltaValue" SG_ 2152480768 PDRLLI_LstLpTmSecs 1;
BA_ "GenSigSendType" SG_ 2152480768 PDRLLI_LstLpTmSecs 12;
BA_ "GenSigSendOnInit" SG_ 2152480768 PDRLLI_LstLpTmSecs 1;
BA_ "VNSigInfotainment" SG_ 2152480768 PDRLLI_LstLpTmSecs 1;
BA_ "SignalType" SG_ 2152480768 PDRLLI_LstLpTmSecs "UNM";
BA_ "PacketOrder" SG_ 2152480768 PDRLLI_LstLpTmSecs 2;
BA_ "SignalLongName" SG_ 2152480768 PDRLLI_LstLpTmSecs "Performance Data Recorder Last Lap Information : Last Lap Time Seconds";
BA_ "VNSigAllNodes" SG_ 2152480768 PDRLLI_LstLpTmSecs 1;
BA_ "GenSigDeltaValue" SG_ 2152480768 PDRLLI_LstLpTmMins 1;
BA_ "GenSigSendType" SG_ 2152480768 PDRLLI_LstLpTmMins 12;
BA_ "GenSigSendOnInit" SG_ 2152480768 PDRLLI_LstLpTmMins 1;
BA_ "VNSigInfotainment" SG_ 2152480768 PDRLLI_LstLpTmMins 1;
BA_ "SignalType" SG_ 2152480768 PDRLLI_LstLpTmMins "UNM";
BA_ "PacketOrder" SG_ 2152480768 PDRLLI_LstLpTmMins 1;
BA_ "SignalLongName" SG_ 2152480768 PDRLLI_LstLpTmMins "Performance Data Recorder Last Lap Information : Last Lap Time Minutes";
BA_ "VNSigAllNodes" SG_ 2152480768 PDRLLI_LstLpTmMins 1;
BA_ "GenSigDeltaValue" SG_ 2152480768 PDRLLI_LstLpTm100s 1;
BA_ "GenSigSendType" SG_ 2152480768 PDRLLI_LstLpTm100s 12;
BA_ "GenSigSendOnInit" SG_ 2152480768 PDRLLI_LstLpTm100s 1;
BA_ "VNSigInfotainment" SG_ 2152480768 PDRLLI_LstLpTm100s 1;
BA_ "SignalType" SG_ 2152480768 PDRLLI_LstLpTm100s "UNM";
BA_ "PacketOrder" SG_ 2152480768 PDRLLI_LstLpTm100s 3;
BA_ "SignalLongName" SG_ 2152480768 PDRLLI_LstLpTm100s "Performance Data Recorder Last Lap Information : Last Lap Time Hundredths of a Second";
BA_ "VNSigAllNodes" SG_ 2152480768 PDRLLI_LstLpTm100s 1;
BA_ "GenSigDeltaValue" SG_ 2152480768 PDRBLI_BstLpTmSecs 1;
BA_ "GenSigSendType" SG_ 2152480768 PDRBLI_BstLpTmSecs 12;
BA_ "GenSigSendOnInit" SG_ 2152480768 PDRBLI_BstLpTmSecs 1;
BA_ "VNSigInfotainment" SG_ 2152480768 PDRBLI_BstLpTmSecs 1;
BA_ "SignalType" SG_ 2152480768 PDRBLI_BstLpTmSecs "UNM";
BA_ "PacketOrder" SG_ 2152480768 PDRBLI_BstLpTmSecs 2;
BA_ "SignalLongName" SG_ 2152480768 PDRBLI_BstLpTmSecs "Performance Data Recorder Best Lap Information : Best Lap Time Seconds";
BA_ "VNSigAllNodes" SG_ 2152480768 PDRBLI_BstLpTmSecs 1;
BA_ "GenSigDeltaValue" SG_ 2152480768 PDRBLI_BstLpTmMins 1;
BA_ "GenSigSendType" SG_ 2152480768 PDRBLI_BstLpTmMins 12;
BA_ "GenSigSendOnInit" SG_ 2152480768 PDRBLI_BstLpTmMins 1;
BA_ "VNSigInfotainment" SG_ 2152480768 PDRBLI_BstLpTmMins 1;
BA_ "SignalType" SG_ 2152480768 PDRBLI_BstLpTmMins "UNM";
BA_ "PacketOrder" SG_ 2152480768 PDRBLI_BstLpTmMins 1;
BA_ "SignalLongName" SG_ 2152480768 PDRBLI_BstLpTmMins "Performance Data Recorder Best Lap Information : Best Lap Time Minutes";
BA_ "VNSigAllNodes" SG_ 2152480768 PDRBLI_BstLpTmMins 1;
BA_ "GenSigDeltaValue" SG_ 2152480768 PDRBLI_BstLpTm100s 1;
BA_ "GenSigSendType" SG_ 2152480768 PDRBLI_BstLpTm100s 12;
BA_ "GenSigSendOnInit" SG_ 2152480768 PDRBLI_BstLpTm100s 1;
BA_ "VNSigInfotainment" SG_ 2152480768 PDRBLI_BstLpTm100s 1;
BA_ "SignalType" SG_ 2152480768 PDRBLI_BstLpTm100s "UNM";
BA_ "PacketOrder" SG_ 2152480768 PDRBLI_BstLpTm100s 3;
BA_ "SignalLongName" SG_ 2152480768 PDRBLI_BstLpTm100s "Performance Data Recorder Best Lap Information : Best Lap Time Hundredths of a Second";
BA_ "VNSigAllNodes" SG_ 2152480768 PDRBLI_BstLpTm100s 1;
BA_ "GenSigDeltaValue" SG_ 2152497152 PDRRI_LpDiffTm10s 1;
BA_ "GenSigSendType" SG_ 2152497152 PDRRI_LpDiffTm10s 12;
BA_ "VNSigInfotainment" SG_ 2152497152 PDRRI_LpDiffTm10s 1;
BA_ "SignalType" SG_ 2152497152 PDRRI_LpDiffTm10s "UNM";
BA_ "PacketOrder" SG_ 2152497152 PDRRI_LpDiffTm10s 5;
BA_ "SignalLongName" SG_ 2152497152 PDRRI_LpDiffTm10s "Performance Data Recorder Realtime Information : Lap Differential Time Tenths of a Second";
BA_ "VNSigAllNodes" SG_ 2152497152 PDRRI_LpDiffTm10s 1;
BA_ "GenSigDeltaValue" SG_ 2152497152 PDRRI_LpDiffTmSecs 1;
BA_ "GenSigSendType" SG_ 2152497152 PDRRI_LpDiffTmSecs 12;
BA_ "VNSigInfotainment" SG_ 2152497152 PDRRI_LpDiffTmSecs 1;
BA_ "SignalType" SG_ 2152497152 PDRRI_LpDiffTmSecs "UNM";
BA_ "PacketOrder" SG_ 2152497152 PDRRI_LpDiffTmSecs 4;
BA_ "SignalLongName" SG_ 2152497152 PDRRI_LpDiffTmSecs "Performance Data Recorder Realtime Information : Lap Differential Time Seconds";
BA_ "VNSigAllNodes" SG_ 2152497152 PDRRI_LpDiffTmSecs 1;
BA_ "GenSigDeltaValue" SG_ 2152497152 PDRRI_CrLpTm10sSec 1;
BA_ "GenSigSendType" SG_ 2152497152 PDRRI_CrLpTm10sSec 12;
BA_ "VNSigInfotainment" SG_ 2152497152 PDRRI_CrLpTm10sSec 1;
BA_ "SignalType" SG_ 2152497152 PDRRI_CrLpTm10sSec "UNM";
BA_ "PacketOrder" SG_ 2152497152 PDRRI_CrLpTm10sSec 3;
BA_ "SignalLongName" SG_ 2152497152 PDRRI_CrLpTm10sSec "Performance Data Recorder Realtime Information : Current Lap Time Tenths of a Second";
BA_ "VNSigAllNodes" SG_ 2152497152 PDRRI_CrLpTm10sSec 1;
BA_ "GenSigDeltaValue" SG_ 2152497152 PDRRI_CrLpTmSecs 1;
BA_ "GenSigSendType" SG_ 2152497152 PDRRI_CrLpTmSecs 12;
BA_ "VNSigInfotainment" SG_ 2152497152 PDRRI_CrLpTmSecs 1;
BA_ "SignalType" SG_ 2152497152 PDRRI_CrLpTmSecs "UNM";
BA_ "PacketOrder" SG_ 2152497152 PDRRI_CrLpTmSecs 2;
BA_ "SignalLongName" SG_ 2152497152 PDRRI_CrLpTmSecs "Performance Data Recorder Realtime Information : Current Lap Time Seconds";
BA_ "VNSigAllNodes" SG_ 2152497152 PDRRI_CrLpTmSecs 1;
BA_ "GenSigDeltaValue" SG_ 2152497152 PDRRI_CrLpTmMins 1;
BA_ "GenSigSendType" SG_ 2152497152 PDRRI_CrLpTmMins 12;
BA_ "VNSigInfotainment" SG_ 2152497152 PDRRI_CrLpTmMins 1;
BA_ "SignalType" SG_ 2152497152 PDRRI_CrLpTmMins "UNM";
BA_ "PacketOrder" SG_ 2152497152 PDRRI_CrLpTmMins 1;
BA_ "SignalLongName" SG_ 2152497152 PDRRI_CrLpTmMins "Performance Data Recorder Realtime Information : Current Lap Time Minutes";
BA_ "VNSigAllNodes" SG_ 2152497152 PDRRI_CrLpTmMins 1;
BA_ "GenSigSendType" SG_ 2153791488 ArtcldRngBrdSt 10;
BA_ "GenSigSendOnInit" SG_ 2153791488 ArtcldRngBrdSt 1;
BA_ "SignalType" SG_ 2153791488 ArtcldRngBrdSt "ENM";
BA_ "SignalLongName" SG_ 2153791488 ArtcldRngBrdSt "Articulated Running Board State";
BA_ "VNSigAllNodes" SG_ 2153791488 ArtcldRngBrdSt 1;
BA_ "GenSigDeltaValue" SG_ 2149883904 BTPR_RspVal 1;
BA_ "GenSigSendType" SG_ 2149883904 BTPR_RspVal 12;
BA_ "SignalType" SG_ 2149883904 BTPR_RspVal "UNM";
BA_ "PacketOrder" SG_ 2149883904 BTPR_RspVal 3;
BA_ "SignalLongName" SG_ 2149883904 BTPR_RspVal "Bluetooth Tethering Pairing Response : Response Value";
BA_ "VNSigAllNodes" SG_ 2149883904 BTPR_RspVal 1;
BA_ "GenSigSendType" SG_ 2149883904 BTPR_RspInfoAvail 10;
BA_ "SignalType" SG_ 2149883904 BTPR_RspInfoAvail "BLN";
BA_ "PacketOrder" SG_ 2149883904 BTPR_RspInfoAvail 2;
BA_ "SignalLongName" SG_ 2149883904 BTPR_RspInfoAvail "Bluetooth Tethering Pairing Response : Response Information Available";
BA_ "VNSigAllNodes" SG_ 2149883904 BTPR_RspInfoAvail 1;
BA_ "GenSigSendType" SG_ 2149883904 BTPR_RspStat 10;
BA_ "SignalType" SG_ 2149883904 BTPR_RspStat "ENM";
BA_ "PacketOrder" SG_ 2149883904 BTPR_RspStat 1;
BA_ "SignalLongName" SG_ 2149883904 BTPR_RspStat "Bluetooth Tethering Pairing Response : Response Status";
BA_ "VNSigAllNodes" SG_ 2149883904 BTPR_RspStat 1;
BA_ "GenSigSendType" SG_ 2150252544 ECHG_YAxisMaxVal 10;
BA_ "GenSigSendOnInit" SG_ 2150252544 ECHG_YAxisMaxVal 1;
BA_ "VNSigInfotainment" SG_ 2150252544 ECHG_YAxisMaxVal 1;
BA_ "SignalType" SG_ 2150252544 ECHG_YAxisMaxVal "ENM";
BA_ "PacketOrder" SG_ 2150252544 ECHG_YAxisMaxVal 14;
BA_ "SignalLongName" SG_ 2150252544 ECHG_YAxisMaxVal "Energy Consumption History Graph : Y Axis Maximum Value";
BA_ "VNSigAllNodes" SG_ 2150252544 ECHG_YAxisMaxVal 1;
BA_ "GenSigSendType" SG_ 2150252544 ECHG_XAxisTkMrkIntvl 10;
BA_ "GenSigSendOnInit" SG_ 2150252544 ECHG_XAxisTkMrkIntvl 1;
BA_ "VNSigInfotainment" SG_ 2150252544 ECHG_XAxisTkMrkIntvl 1;
BA_ "SignalType" SG_ 2150252544 ECHG_XAxisTkMrkIntvl "ENM";
BA_ "PacketOrder" SG_ 2150252544 ECHG_XAxisTkMrkIntvl 13;
BA_ "SignalLongName" SG_ 2150252544 ECHG_XAxisTkMrkIntvl "Energy Consumption History Graph : X Axis Tick Mark Interval";
BA_ "VNSigAllNodes" SG_ 2150252544 ECHG_XAxisTkMrkIntvl 1;
BA_ "GenSigDeltaValue" SG_ 2150252544 ECHG_Column10 1;
BA_ "GenSigSendType" SG_ 2150252544 ECHG_Column10 12;
BA_ "GenSigSendOnInit" SG_ 2150252544 ECHG_Column10 1;
BA_ "VNSigInfotainment" SG_ 2150252544 ECHG_Column10 1;
BA_ "SignalType" SG_ 2150252544 ECHG_Column10 "UNM";
BA_ "PacketOrder" SG_ 2150252544 ECHG_Column10 12;
BA_ "SignalLongName" SG_ 2150252544 ECHG_Column10 "Energy Consumption History Graph : Column 10";
BA_ "VNSigAllNodes" SG_ 2150252544 ECHG_Column10 1;
BA_ "GenSigDeltaValue" SG_ 2150252544 ECHG_Column09 1;
BA_ "GenSigSendType" SG_ 2150252544 ECHG_Column09 12;
BA_ "GenSigSendOnInit" SG_ 2150252544 ECHG_Column09 1;
BA_ "VNSigInfotainment" SG_ 2150252544 ECHG_Column09 1;
BA_ "SignalType" SG_ 2150252544 ECHG_Column09 "UNM";
BA_ "PacketOrder" SG_ 2150252544 ECHG_Column09 11;
BA_ "SignalLongName" SG_ 2150252544 ECHG_Column09 "Energy Consumption History Graph : Column 09";
BA_ "VNSigAllNodes" SG_ 2150252544 ECHG_Column09 1;
BA_ "GenSigDeltaValue" SG_ 2150252544 ECHG_Column08 1;
BA_ "GenSigSendType" SG_ 2150252544 ECHG_Column08 12;
BA_ "GenSigSendOnInit" SG_ 2150252544 ECHG_Column08 1;
BA_ "VNSigInfotainment" SG_ 2150252544 ECHG_Column08 1;
BA_ "SignalType" SG_ 2150252544 ECHG_Column08 "UNM";
BA_ "PacketOrder" SG_ 2150252544 ECHG_Column08 10;
BA_ "SignalLongName" SG_ 2150252544 ECHG_Column08 "Energy Consumption History Graph : Column 08";
BA_ "VNSigAllNodes" SG_ 2150252544 ECHG_Column08 1;
BA_ "GenSigDeltaValue" SG_ 2150252544 ECHG_Column07 1;
BA_ "GenSigSendType" SG_ 2150252544 ECHG_Column07 12;
BA_ "GenSigSendOnInit" SG_ 2150252544 ECHG_Column07 1;
BA_ "VNSigInfotainment" SG_ 2150252544 ECHG_Column07 1;
BA_ "SignalType" SG_ 2150252544 ECHG_Column07 "UNM";
BA_ "PacketOrder" SG_ 2150252544 ECHG_Column07 9;
BA_ "SignalLongName" SG_ 2150252544 ECHG_Column07 "Energy Consumption History Graph : Column 07";
BA_ "VNSigAllNodes" SG_ 2150252544 ECHG_Column07 1;
BA_ "GenSigDeltaValue" SG_ 2150252544 ECHG_Column06 1;
BA_ "GenSigSendType" SG_ 2150252544 ECHG_Column06 12;
BA_ "GenSigSendOnInit" SG_ 2150252544 ECHG_Column06 1;
BA_ "VNSigInfotainment" SG_ 2150252544 ECHG_Column06 1;
BA_ "SignalType" SG_ 2150252544 ECHG_Column06 "UNM";
BA_ "PacketOrder" SG_ 2150252544 ECHG_Column06 8;
BA_ "SignalLongName" SG_ 2150252544 ECHG_Column06 "Energy Consumption History Graph : Column 06";
BA_ "VNSigAllNodes" SG_ 2150252544 ECHG_Column06 1;
BA_ "GenSigDeltaValue" SG_ 2150252544 ECHG_Column05 1;
BA_ "GenSigSendType" SG_ 2150252544 ECHG_Column05 12;
BA_ "GenSigSendOnInit" SG_ 2150252544 ECHG_Column05 1;
BA_ "VNSigInfotainment" SG_ 2150252544 ECHG_Column05 1;
BA_ "SignalType" SG_ 2150252544 ECHG_Column05 "UNM";
BA_ "PacketOrder" SG_ 2150252544 ECHG_Column05 7;
BA_ "SignalLongName" SG_ 2150252544 ECHG_Column05 "Energy Consumption History Graph : Column 05";
BA_ "VNSigAllNodes" SG_ 2150252544 ECHG_Column05 1;
BA_ "GenSigDeltaValue" SG_ 2150252544 ECHG_Column04 1;
BA_ "GenSigSendType" SG_ 2150252544 ECHG_Column04 12;
BA_ "GenSigSendOnInit" SG_ 2150252544 ECHG_Column04 1;
BA_ "VNSigInfotainment" SG_ 2150252544 ECHG_Column04 1;
BA_ "SignalType" SG_ 2150252544 ECHG_Column04 "UNM";
BA_ "PacketOrder" SG_ 2150252544 ECHG_Column04 6;
BA_ "SignalLongName" SG_ 2150252544 ECHG_Column04 "Energy Consumption History Graph : Column 04";
BA_ "VNSigAllNodes" SG_ 2150252544 ECHG_Column04 1;
BA_ "GenSigDeltaValue" SG_ 2150252544 ECHG_Column03 1;
BA_ "GenSigSendType" SG_ 2150252544 ECHG_Column03 12;
BA_ "GenSigSendOnInit" SG_ 2150252544 ECHG_Column03 1;
BA_ "VNSigInfotainment" SG_ 2150252544 ECHG_Column03 1;
BA_ "SignalType" SG_ 2150252544 ECHG_Column03 "UNM";
BA_ "PacketOrder" SG_ 2150252544 ECHG_Column03 5;
BA_ "SignalLongName" SG_ 2150252544 ECHG_Column03 "Energy Consumption History Graph : Column 03";
BA_ "VNSigAllNodes" SG_ 2150252544 ECHG_Column03 1;
BA_ "GenSigDeltaValue" SG_ 2150252544 ECHG_Column02 1;
BA_ "GenSigSendType" SG_ 2150252544 ECHG_Column02 12;
BA_ "GenSigSendOnInit" SG_ 2150252544 ECHG_Column02 1;
BA_ "VNSigInfotainment" SG_ 2150252544 ECHG_Column02 1;
BA_ "SignalType" SG_ 2150252544 ECHG_Column02 "UNM";
BA_ "PacketOrder" SG_ 2150252544 ECHG_Column02 4;
BA_ "SignalLongName" SG_ 2150252544 ECHG_Column02 "Energy Consumption History Graph : Column 02";
BA_ "VNSigAllNodes" SG_ 2150252544 ECHG_Column02 1;
BA_ "GenSigDeltaValue" SG_ 2150252544 ECHG_Column01 1;
BA_ "GenSigSendType" SG_ 2150252544 ECHG_Column01 12;
BA_ "GenSigSendOnInit" SG_ 2150252544 ECHG_Column01 1;
BA_ "VNSigInfotainment" SG_ 2150252544 ECHG_Column01 1;
BA_ "SignalType" SG_ 2150252544 ECHG_Column01 "UNM";
BA_ "PacketOrder" SG_ 2150252544 ECHG_Column01 3;
BA_ "SignalLongName" SG_ 2150252544 ECHG_Column01 "Energy Consumption History Graph : Column 01";
BA_ "VNSigAllNodes" SG_ 2150252544 ECHG_Column01 1;
BA_ "GenSigDeltaValue" SG_ 2150252544 ECHG_EngyCnsmdAvg 1;
BA_ "GenSigSendType" SG_ 2150252544 ECHG_EngyCnsmdAvg 12;
BA_ "GenSigSendOnInit" SG_ 2150252544 ECHG_EngyCnsmdAvg 1;
BA_ "VNSigInfotainment" SG_ 2150252544 ECHG_EngyCnsmdAvg 1;
BA_ "SignalType" SG_ 2150252544 ECHG_EngyCnsmdAvg "UNM";
BA_ "PacketOrder" SG_ 2150252544 ECHG_EngyCnsmdAvg 2;
BA_ "SignalLongName" SG_ 2150252544 ECHG_EngyCnsmdAvg "Energy Consumption History Graph : Energy Consumed Average";
BA_ "VNSigAllNodes" SG_ 2150252544 ECHG_EngyCnsmdAvg 1;
BA_ "GenSigSendType" SG_ 2150252544 ECHG_MeasUnit 10;
BA_ "GenSigSendOnInit" SG_ 2150252544 ECHG_MeasUnit 1;
BA_ "VNSigInfotainment" SG_ 2150252544 ECHG_MeasUnit 1;
BA_ "SignalType" SG_ 2150252544 ECHG_MeasUnit "ENM";
BA_ "PacketOrder" SG_ 2150252544 ECHG_MeasUnit 1;
BA_ "SignalLongName" SG_ 2150252544 ECHG_MeasUnit "Energy Consumption History Graph : Measurement Unit";
BA_ "VNSigAllNodes" SG_ 2150252544 ECHG_MeasUnit 1;
BA_ "GenSigDeltaValue" SG_ 2150391808 EngRunAtvTm 1;
BA_ "GenSigSendType" SG_ 2150391808 EngRunAtvTm 12;
BA_ "GenSigSendOnInit" SG_ 2150391808 EngRunAtvTm 1;
BA_ "SignalType" SG_ 2150391808 EngRunAtvTm "UNM";
BA_ "SignalLongName" SG_ 2150391808 EngRunAtvTm "Engine Run Active Time";
BA_ "VNSigAllNodes" SG_ 2150391808 EngRunAtvTm 1;
BA_ "GenSigDeltaValue" SG_ 2150391808 EngIdlAtvTm 1;
BA_ "GenSigSendType" SG_ 2150391808 EngIdlAtvTm 12;
BA_ "GenSigSendOnInit" SG_ 2150391808 EngIdlAtvTm 1;
BA_ "SignalType" SG_ 2150391808 EngIdlAtvTm "UNM";
BA_ "SignalLongName" SG_ 2150391808 EngIdlAtvTm "Engine Idle Active Time";
BA_ "VNSigAllNodes" SG_ 2150391808 EngIdlAtvTm 1;
BA_ "SignalType" SG_ 2155913216 PFAS_SrvPedAlrtIO "BLN";
BA_ "PacketOrder" SG_ 2155913216 PFAS_SrvPedAlrtIO 7;
BA_ "SignalLongName" SG_ 2155913216 PFAS_SrvPedAlrtIO "Pedestrian Friendly Alert Status : Service Pedestrian Friendly Alert Indication On";
BA_ "VNSigAllNodes" SG_ 2155913216 PFAS_SrvPedAlrtIO 1;
BA_ "SignalType" SG_ 2155913216 PFAS_PFASysStat "ENM";
BA_ "PacketOrder" SG_ 2155913216 PFAS_PFASysStat 6;
BA_ "SignalLongName" SG_ 2155913216 PFAS_PFASysStat "Pedestrian Friendly Alert Status : Pedestrian Friendly Alert System Status";
BA_ "VNSigAllNodes" SG_ 2155913216 PFAS_PFASysStat 1;
BA_ "SignalType" SG_ 2155913216 PFAS_PFASndVolCtrl "UNM";
BA_ "PacketOrder" SG_ 2155913216 PFAS_PFASndVolCtrl 5;
BA_ "SignalLongName" SG_ 2155913216 PFAS_PFASndVolCtrl "Pedestrian Friendly Alert Status : Pedestrian Friendly Alert Sound Volume Control";
BA_ "VNSigAllNodes" SG_ 2155913216 PFAS_PFASndVolCtrl 1;
BA_ "SignalType" SG_ 2155913216 PFAS_PFASndGenEn "BLN";
BA_ "PacketOrder" SG_ 2155913216 PFAS_PFASndGenEn 1;
BA_ "SignalLongName" SG_ 2155913216 PFAS_PFASndGenEn "Pedestrian Friendly Alert Status : Pedestrian Friendly Alert Sound Generation Enable";
BA_ "VNSigAllNodes" SG_ 2155913216 PFAS_PFASndGenEn 1;
BA_ "SignalType" SG_ 2155913216 PFAS_PFARevSnd "ENM";
BA_ "PacketOrder" SG_ 2155913216 PFAS_PFARevSnd 3;
BA_ "SignalLongName" SG_ 2155913216 PFAS_PFARevSnd "Pedestrian Friendly Alert Status : Pedestrian Friendly Alert Reverse Sound";
BA_ "VNSigAllNodes" SG_ 2155913216 PFAS_PFARevSnd 1;
BA_ "SignalType" SG_ 2155913216 PFAS_PFAFwdSnd "ENM";
BA_ "PacketOrder" SG_ 2155913216 PFAS_PFAFwdSnd 2;
BA_ "SignalLongName" SG_ 2155913216 PFAS_PFAFwdSnd "Pedestrian Friendly Alert Status : Pedestrian Friendly Alert Forward Sound";
BA_ "VNSigAllNodes" SG_ 2155913216 PFAS_PFAFwdSnd 1;
BA_ "SignalType" SG_ 2155913216 PFAS_PFACrsOvrSpd "UNM";
BA_ "PacketOrder" SG_ 2155913216 PFAS_PFACrsOvrSpd 4;
BA_ "SignalLongName" SG_ 2155913216 PFAS_PFACrsOvrSpd "Pedestrian Friendly Alert Status : Pedestrian Friendly Alert Crossover Speed";
BA_ "VNSigAllNodes" SG_ 2155913216 PFAS_PFACrsOvrSpd 1;
BA_ "SignalType" SG_ 2155913216 PedFrndlyAlrtCsSetAvl "BLN";
BA_ "SignalLongName" SG_ 2155913216 PedFrndlyAlrtCsSetAvl "Pedestrian Friendly Alert Customization Setting Available";
BA_ "VNSigAllNodes" SG_ 2155913216 PedFrndlyAlrtCsSetAvl 1;
BA_ "SignalType" SG_ 2155913216 PedFrndlyAlrtCsCrStVal "ENM";
BA_ "SignalLongName" SG_ 2155913216 PedFrndlyAlrtCsCrStVal "Pedestrian Friendly Alert Customization Current Setting Value";
BA_ "VNSigAllNodes" SG_ 2155913216 PedFrndlyAlrtCsCrStVal 1;
BA_ "SignalType" SG_ 2155913216 DslExhFldRmngDstHRs "UNM";
BA_ "SignalLongName" SG_ 2155913216 DslExhFldRmngDstHRs "Diesel Exhaust Fluid Remaining Distance High Resolution";
BA_ "VNSigAllNodes" SG_ 2155913216 DslExhFldRmngDstHRs 1;
BA_ "SignalType" SG_ 2155913216 DslExhFluidLvlPrcntV "ENM";
BA_ "SignalLongName" SG_ 2155913216 DslExhFluidLvlPrcntV "Diesel Exhaust Fluid Level Percent Validity";
BA_ "VNSigAllNodes" SG_ 2155913216 DslExhFluidLvlPrcntV 1;
BA_ "SignalType" SG_ 2155913216 DslExhFluidLvlPrcnt "UNM";
BA_ "SignalLongName" SG_ 2155913216 DslExhFluidLvlPrcnt "Diesel Exhaust Fluid Level Percent";
BA_ "VNSigAllNodes" SG_ 2155913216 DslExhFluidLvlPrcnt 1;
BA_ "SignalType" SG_ 2155913216 DslEmnsOBDMrkt "ENM";
BA_ "SignalLongName" SG_ 2155913216 DslEmnsOBDMrkt "Diesel Emissions OBD Market";
BA_ "VNSigAllNodes" SG_ 2155913216 DslEmnsOBDMrkt 1;
BA_ "SignalType" SG_ 2155913216 DslExhFldRmngDstHRsV "ENM";
BA_ "SignalLongName" SG_ 2155913216 DslExhFldRmngDstHRsV "Diesel Exhaust Fluid Remaining Distance High Resolution Validity";
BA_ "VNSigAllNodes" SG_ 2155913216 DslExhFldRmngDstHRsV 1;
BA_ "SignalType" SG_ 2034 DgnInf "UNM";
BA_ "SignalLongName" SG_ 2034 DgnInf "Diagnostic Information";
BA_ "VNSigDiagnostic" SG_ 2034 DgnInf 1;
BA_ "VNSigAllNodes" SG_ 2034 DgnInf 1;
BA_ "SignalType" SG_ 2032 DgnInf "UNM";
BA_ "SignalLongName" SG_ 2032 DgnInf "Diagnostic Information";
BA_ "VNSigDiagnostic" SG_ 2032 DgnInf 1;
BA_ "VNSigAllNodes" SG_ 2032 DgnInf 1;
BA_ "SignalType" SG_ 2152095744 SPMCA_SusPrfMd6Avl "BLN";
BA_ "PacketOrder" SG_ 2152095744 SPMCA_SusPrfMd6Avl 6;
BA_ "SignalLongName" SG_ 2152095744 SPMCA_SusPrfMd6Avl "Suspension Performance Mode Customization Available : Suspension Performance Mode 6 Available";
BA_ "VNSigAllNodes" SG_ 2152095744 SPMCA_SusPrfMd6Avl 1;
BA_ "SignalType" SG_ 2152095744 SPMCA_SusPrfMd5Avl "BLN";
BA_ "PacketOrder" SG_ 2152095744 SPMCA_SusPrfMd5Avl 5;
BA_ "SignalLongName" SG_ 2152095744 SPMCA_SusPrfMd5Avl "Suspension Performance Mode Customization Available : Suspension Performance Mode 5 Available";
BA_ "VNSigAllNodes" SG_ 2152095744 SPMCA_SusPrfMd5Avl 1;
BA_ "SignalType" SG_ 2152095744 SPMCA_SusPrfMd4Avl "BLN";
BA_ "PacketOrder" SG_ 2152095744 SPMCA_SusPrfMd4Avl 4;
BA_ "SignalLongName" SG_ 2152095744 SPMCA_SusPrfMd4Avl "Suspension Performance Mode Customization Available : Suspension Performance Mode 4 Available";
BA_ "VNSigAllNodes" SG_ 2152095744 SPMCA_SusPrfMd4Avl 1;
BA_ "SignalType" SG_ 2152095744 SPMCA_SusPrfMd3Avl "BLN";
BA_ "PacketOrder" SG_ 2152095744 SPMCA_SusPrfMd3Avl 3;
BA_ "SignalLongName" SG_ 2152095744 SPMCA_SusPrfMd3Avl "Suspension Performance Mode Customization Available : Suspension Performance Mode 3 Available";
BA_ "VNSigAllNodes" SG_ 2152095744 SPMCA_SusPrfMd3Avl 1;
BA_ "SignalType" SG_ 2152095744 SPMCA_SusPrfMd2Avl "BLN";
BA_ "PacketOrder" SG_ 2152095744 SPMCA_SusPrfMd2Avl 2;
BA_ "SignalLongName" SG_ 2152095744 SPMCA_SusPrfMd2Avl "Suspension Performance Mode Customization Available : Suspension Performance Mode 2 Available";
BA_ "VNSigAllNodes" SG_ 2152095744 SPMCA_SusPrfMd2Avl 1;
BA_ "SignalType" SG_ 2152095744 SPMCA_SusPrfMd1Avl "BLN";
BA_ "PacketOrder" SG_ 2152095744 SPMCA_SusPrfMd1Avl 1;
BA_ "SignalLongName" SG_ 2152095744 SPMCA_SusPrfMd1Avl "Suspension Performance Mode Customization Available : Suspension Performance Mode 1 Available";
BA_ "VNSigAllNodes" SG_ 2152095744 SPMCA_SusPrfMd1Avl 1;
BA_ "SignalType" SG_ 2152095744 SPMCA_StrPrfMd6Avl "BLN";
BA_ "PacketOrder" SG_ 2152095744 SPMCA_StrPrfMd6Avl 6;
BA_ "SignalLongName" SG_ 2152095744 SPMCA_StrPrfMd6Avl "Steering Performance Mode Customization Available : Steering Performance Mode 6 Available";
BA_ "VNSigAllNodes" SG_ 2152095744 SPMCA_StrPrfMd6Avl 1;
BA_ "SignalType" SG_ 2152095744 SPMCA_StrPrfMd5Avl "BLN";
BA_ "PacketOrder" SG_ 2152095744 SPMCA_StrPrfMd5Avl 5;
BA_ "SignalLongName" SG_ 2152095744 SPMCA_StrPrfMd5Avl "Steering Performance Mode Customization Available : Steering Performance Mode 5 Available";
BA_ "VNSigAllNodes" SG_ 2152095744 SPMCA_StrPrfMd5Avl 1;
BA_ "SignalType" SG_ 2152095744 SPMCA_StrPrfMd4Avl "BLN";
BA_ "PacketOrder" SG_ 2152095744 SPMCA_StrPrfMd4Avl 4;
BA_ "SignalLongName" SG_ 2152095744 SPMCA_StrPrfMd4Avl "Steering Performance Mode Customization Available : Steering Performance Mode 4 Available";
BA_ "VNSigAllNodes" SG_ 2152095744 SPMCA_StrPrfMd4Avl 1;
BA_ "SignalType" SG_ 2152095744 SPMCA_StrPrfMd3Avl "BLN";
BA_ "PacketOrder" SG_ 2152095744 SPMCA_StrPrfMd3Avl 3;
BA_ "SignalLongName" SG_ 2152095744 SPMCA_StrPrfMd3Avl "Steering Performance Mode Customization Available : Steering Performance Mode 3 Available";
BA_ "VNSigAllNodes" SG_ 2152095744 SPMCA_StrPrfMd3Avl 1;
BA_ "SignalType" SG_ 2152095744 SPMCA_StrPrfMd2Avl "BLN";
BA_ "PacketOrder" SG_ 2152095744 SPMCA_StrPrfMd2Avl 2;
BA_ "SignalLongName" SG_ 2152095744 SPMCA_StrPrfMd2Avl "Steering Performance Mode Customization Available : Steering Performance Mode 2 Available";
BA_ "VNSigAllNodes" SG_ 2152095744 SPMCA_StrPrfMd2Avl 1;
BA_ "SignalType" SG_ 2152095744 SPMCA_StrPrfMd1Avl "BLN";
BA_ "PacketOrder" SG_ 2152095744 SPMCA_StrPrfMd1Avl 1;
BA_ "SignalLongName" SG_ 2152095744 SPMCA_StrPrfMd1Avl "Steering Performance Mode Customization Available : Steering Performance Mode 1 Available";
BA_ "VNSigAllNodes" SG_ 2152095744 SPMCA_StrPrfMd1Avl 1;
BA_ "SignalType" SG_ 2152095744 SPMCA_SndPrfMd6Avl "BLN";
BA_ "PacketOrder" SG_ 2152095744 SPMCA_SndPrfMd6Avl 6;
BA_ "SignalLongName" SG_ 2152095744 SPMCA_SndPrfMd6Avl "Sound Performance Mode Customization Available : Sound Performance Mode 6 Available";
BA_ "VNSigAllNodes" SG_ 2152095744 SPMCA_SndPrfMd6Avl 1;
BA_ "SignalType" SG_ 2152095744 SPMCA_SndPrfMd5Avl "BLN";
BA_ "PacketOrder" SG_ 2152095744 SPMCA_SndPrfMd5Avl 5;
BA_ "SignalLongName" SG_ 2152095744 SPMCA_SndPrfMd5Avl "Sound Performance Mode Customization Available : Sound Performance Mode 5 Available";
BA_ "VNSigAllNodes" SG_ 2152095744 SPMCA_SndPrfMd5Avl 1;
BA_ "SignalType" SG_ 2152095744 SPMCA_SndPrfMd4Avl "BLN";
BA_ "PacketOrder" SG_ 2152095744 SPMCA_SndPrfMd4Avl 4;
BA_ "SignalLongName" SG_ 2152095744 SPMCA_SndPrfMd4Avl "Sound Performance Mode Customization Available : Sound Performance Mode 4 Available";
BA_ "VNSigAllNodes" SG_ 2152095744 SPMCA_SndPrfMd4Avl 1;
BA_ "SignalType" SG_ 2152095744 SPMCA_SndPrfMd3Avl "BLN";
BA_ "PacketOrder" SG_ 2152095744 SPMCA_SndPrfMd3Avl 3;
BA_ "SignalLongName" SG_ 2152095744 SPMCA_SndPrfMd3Avl "Sound Performance Mode Customization Available : Sound Performance Mode 3 Available";
BA_ "VNSigAllNodes" SG_ 2152095744 SPMCA_SndPrfMd3Avl 1;
BA_ "SignalType" SG_ 2152095744 SPMCA_SndPrfMd2Avl "BLN";
BA_ "PacketOrder" SG_ 2152095744 SPMCA_SndPrfMd2Avl 2;
BA_ "SignalLongName" SG_ 2152095744 SPMCA_SndPrfMd2Avl "Sound Performance Mode Customization Available : Sound Performance Mode 2 Available";
BA_ "VNSigAllNodes" SG_ 2152095744 SPMCA_SndPrfMd2Avl 1;
BA_ "SignalType" SG_ 2152095744 SPMCA_SndPrfMd1Avl "BLN";
BA_ "PacketOrder" SG_ 2152095744 SPMCA_SndPrfMd1Avl 1;
BA_ "SignalLongName" SG_ 2152095744 SPMCA_SndPrfMd1Avl "Sound Performance Mode Customization Available : Sound Performance Mode 1 Available";
BA_ "VNSigAllNodes" SG_ 2152095744 SPMCA_SndPrfMd1Avl 1;
BA_ "SignalType" SG_ 2152095744 DPMCA_DispPrfMd6Avl "BLN";
BA_ "PacketOrder" SG_ 2152095744 DPMCA_DispPrfMd6Avl 6;
BA_ "SignalLongName" SG_ 2152095744 DPMCA_DispPrfMd6Avl "Display Performance Mode Customization Available : Display Performance Mode 6 Available";
BA_ "VNSigAllNodes" SG_ 2152095744 DPMCA_DispPrfMd6Avl 1;
BA_ "SignalType" SG_ 2152095744 DPMCA_DispPrfMd5Avl "BLN";
BA_ "PacketOrder" SG_ 2152095744 DPMCA_DispPrfMd5Avl 5;
BA_ "SignalLongName" SG_ 2152095744 DPMCA_DispPrfMd5Avl "Display Performance Mode Customization Available : Display Performance Mode 5 Available";
BA_ "VNSigAllNodes" SG_ 2152095744 DPMCA_DispPrfMd5Avl 1;
BA_ "SignalType" SG_ 2152095744 DPMCA_DispPrfMd4Avl "BLN";
BA_ "PacketOrder" SG_ 2152095744 DPMCA_DispPrfMd4Avl 4;
BA_ "SignalLongName" SG_ 2152095744 DPMCA_DispPrfMd4Avl "Display Performance Mode Customization Available : Display Performance Mode 4 Available";
BA_ "VNSigAllNodes" SG_ 2152095744 DPMCA_DispPrfMd4Avl 1;
BA_ "SignalType" SG_ 2152095744 DPMCA_DispPrfMd3Avl "BLN";
BA_ "PacketOrder" SG_ 2152095744 DPMCA_DispPrfMd3Avl 3;
BA_ "SignalLongName" SG_ 2152095744 DPMCA_DispPrfMd3Avl "Display Performance Mode Customization Available : Display Performance Mode 3 Available";
BA_ "VNSigAllNodes" SG_ 2152095744 DPMCA_DispPrfMd3Avl 1;
BA_ "SignalType" SG_ 2152095744 DPMCA_DispPrfMd2Avl "BLN";
BA_ "PacketOrder" SG_ 2152095744 DPMCA_DispPrfMd2Avl 2;
BA_ "SignalLongName" SG_ 2152095744 DPMCA_DispPrfMd2Avl "Display Performance Mode Customization Available : Display Performance Mode 2 Available";
BA_ "VNSigAllNodes" SG_ 2152095744 DPMCA_DispPrfMd2Avl 1;
BA_ "SignalType" SG_ 2152095744 DPMCA_DispPrfMd1Avl "BLN";
BA_ "PacketOrder" SG_ 2152095744 DPMCA_DispPrfMd1Avl 1;
BA_ "SignalLongName" SG_ 2152095744 DPMCA_DispPrfMd1Avl "Display Performance Mode Customization Available : Display Performance Mode 1 Available";
BA_ "VNSigAllNodes" SG_ 2152095744 DPMCA_DispPrfMd1Avl 1;
BA_ "SignalType" SG_ 2152095744 DPMCA_DrvlPrfMd6Avl "BLN";
BA_ "PacketOrder" SG_ 2152095744 DPMCA_DrvlPrfMd6Avl 6;
BA_ "SignalLongName" SG_ 2152095744 DPMCA_DrvlPrfMd6Avl "Driveline Performance Mode Customization Available : Driveline Performance Mode 6 Available";
BA_ "VNSigAllNodes" SG_ 2152095744 DPMCA_DrvlPrfMd6Avl 1;
BA_ "SignalType" SG_ 2152095744 DPMCA_DrvlPrfMd5Avl "BLN";
BA_ "PacketOrder" SG_ 2152095744 DPMCA_DrvlPrfMd5Avl 5;
BA_ "SignalLongName" SG_ 2152095744 DPMCA_DrvlPrfMd5Avl "Driveline Performance Mode Customization Available : Driveline Performance Mode 5 Available";
BA_ "VNSigAllNodes" SG_ 2152095744 DPMCA_DrvlPrfMd5Avl 1;
BA_ "SignalType" SG_ 2152095744 DPMCA_DrvlPrfMd4Avl "BLN";
BA_ "PacketOrder" SG_ 2152095744 DPMCA_DrvlPrfMd4Avl 4;
BA_ "SignalLongName" SG_ 2152095744 DPMCA_DrvlPrfMd4Avl "Driveline Performance Mode Customization Available : Driveline Performance Mode 4 Available";
BA_ "VNSigAllNodes" SG_ 2152095744 DPMCA_DrvlPrfMd4Avl 1;
BA_ "SignalType" SG_ 2152095744 DPMCA_DrvlPrfMd3Avl "BLN";
BA_ "PacketOrder" SG_ 2152095744 DPMCA_DrvlPrfMd3Avl 3;
BA_ "SignalLongName" SG_ 2152095744 DPMCA_DrvlPrfMd3Avl "Driveline Performance Mode Customization Available : Driveline Performance Mode 3 Available";
BA_ "VNSigAllNodes" SG_ 2152095744 DPMCA_DrvlPrfMd3Avl 1;
BA_ "SignalType" SG_ 2152095744 DPMCA_DrvlPrfMd2Avl "BLN";
BA_ "PacketOrder" SG_ 2152095744 DPMCA_DrvlPrfMd2Avl 2;
BA_ "SignalLongName" SG_ 2152095744 DPMCA_DrvlPrfMd2Avl "Driveline Performance Mode Customization Available : Driveline Performance Mode 2 Available";
BA_ "VNSigAllNodes" SG_ 2152095744 DPMCA_DrvlPrfMd2Avl 1;
BA_ "SignalType" SG_ 2152095744 DPMCA_DrvlPrfMd1Avl "BLN";
BA_ "PacketOrder" SG_ 2152095744 DPMCA_DrvlPrfMd1Avl 1;
BA_ "SignalLongName" SG_ 2152095744 DPMCA_DrvlPrfMd1Avl "Driveline Performance Mode Customization Available : Driveline Performance Mode 1 Available";
BA_ "VNSigAllNodes" SG_ 2152095744 DPMCA_DrvlPrfMd1Avl 1;
BA_ "GenSigSendType" SG_ 2156945408 WiFiSSIDDgts1to8_Mp 10;
BA_ "GenSigSendOnInit" SG_ 2156945408 WiFiSSIDDgts1to8_Mp 2;
BA_ "SignalType" SG_ 2156945408 WiFiSSIDDgts1to8_Mp "ASC";
BA_ "SignalLongName" SG_ 2156945408 WiFiSSIDDgts1to8_Mp "WiFi Service Set Identifier Digits 1 to 8 Map";
BA_ "VNSigAllNodes" SG_ 2156945408 WiFiSSIDDgts1to8_Mp 1;
BA_ "GenSigDeltaValue" SG_ 2152611840 OBTCR_Prty 1;
BA_ "GenSigSendType" SG_ 2152611840 OBTCR_Prty 12;
BA_ "VNSigInfotainment" SG_ 2152611840 OBTCR_Prty 1;
BA_ "SignalType" SG_ 2152611840 OBTCR_Prty "UNM";
BA_ "PacketOrder" SG_ 2152611840 OBTCR_Prty 2;
BA_ "SignalLongName" SG_ 2152611840 OBTCR_Prty "On Board Tester Coordination Request : Priority";
BA_ "VNSigAllNodes" SG_ 2152611840 OBTCR_Prty 1;
BA_ "GenSigSendType" SG_ 2152611840 OBTCR_Actv 10;
BA_ "VNSigInfotainment" SG_ 2152611840 OBTCR_Actv 1;
BA_ "SignalType" SG_ 2152611840 OBTCR_Actv "BLN";
BA_ "PacketOrder" SG_ 2152611840 OBTCR_Actv 1;
BA_ "SignalLongName" SG_ 2152611840 OBTCR_Actv "On Board Tester Coordination Request : Active";
BA_ "VNSigAllNodes" SG_ 2152611840 OBTCR_Actv 1;
BA_ "GenSigDeltaValue" SG_ 2152611840 OBTCReqstrID 1;
BA_ "GenSigSendType" SG_ 2152611840 OBTCReqstrID 12;
BA_ "GenSigSendOnInit" SG_ 2152611840 OBTCReqstrID 1;
BA_ "VNSigInfotainment" SG_ 2152611840 OBTCReqstrID 1;
BA_ "SignalType" SG_ 2152611840 OBTCReqstrID "UNM";
BA_ "SignalLongName" SG_ 2152611840 OBTCReqstrID "On Board Tester Coordination Requester ID";
BA_ "VNSigAllNodes" SG_ 2152611840 OBTCReqstrID 1;
BA_ "GenSigSendType" SG_ 2152611840 OBTCReqstrStat 10;
BA_ "GenSigSendOnInit" SG_ 2152611840 OBTCReqstrStat 1;
BA_ "VNSigInfotainment" SG_ 2152611840 OBTCReqstrStat 1;
BA_ "SignalType" SG_ 2152611840 OBTCReqstrStat "ENM";
BA_ "SignalLongName" SG_ 2152611840 OBTCReqstrStat "On Board Tester Coordination Requester Status";
BA_ "VNSigAllNodes" SG_ 2152611840 OBTCReqstrStat 1;
BA_ "SignalType" SG_ 2153308160 RdHVltBatPckVltV "ENM";
BA_ "SignalLongName" SG_ 2153308160 RdHVltBatPckVltV "Redundant High Voltage Battery Pack Voltage Validity";
BA_ "VNSigAllNodes" SG_ 2153308160 RdHVltBatPckVltV 1;
BA_ "SignalType" SG_ 2153308160 RdHVltBatPckVltM "ENM";
BA_ "SignalLongName" SG_ 2153308160 RdHVltBatPckVltM "Redundant High Voltage Battery Pack Voltage Mask";
BA_ "VNSigAllNodes" SG_ 2153308160 RdHVltBatPckVltM 1;
BA_ "GenSigSendOnInit" SG_ 2153308160 RdHVltBatPckVlt 1;
BA_ "SignalType" SG_ 2153308160 RdHVltBatPckVlt "UNM";
BA_ "SignalLongName" SG_ 2153308160 RdHVltBatPckVlt "Redundant High Voltage Battery Pack Voltage";
BA_ "VNSigAllNodes" SG_ 2153308160 RdHVltBatPckVlt 1;
BA_ "GenSigSendOnInit" SG_ 2153308160 RdHVltBatPckCrntV 1;
BA_ "SignalType" SG_ 2153308160 RdHVltBatPckCrntV "ENM";
BA_ "SignalLongName" SG_ 2153308160 RdHVltBatPckCrntV "Redundant High Voltage Battery Pack Current Validity";
BA_ "VNSigAllNodes" SG_ 2153308160 RdHVltBatPckCrntV 1;
BA_ "GenSigSendOnInit" SG_ 2153308160 RdHVltBatPckCrntM 1;
BA_ "SignalType" SG_ 2153308160 RdHVltBatPckCrntM "ENM";
BA_ "SignalLongName" SG_ 2153308160 RdHVltBatPckCrntM "Redundant High Voltage Battery Pack Current Mask";
BA_ "VNSigAllNodes" SG_ 2153308160 RdHVltBatPckCrntM 1;
BA_ "GenSigSendOnInit" SG_ 2153308160 RdHVltBatPckCrnt 1;
BA_ "SignalType" SG_ 2153308160 RdHVltBatPckCrnt "SNM";
BA_ "SignalLongName" SG_ 2153308160 RdHVltBatPckCrnt "Redundant High Voltage Battery Pack Current";
BA_ "VNSigAllNodes" SG_ 2153308160 RdHVltBatPckCrnt 1;
BA_ "GenSigSendType" SG_ 2155970560 ClmCntLdShdLvlRq 10;
BA_ "SignalType" SG_ 2155970560 ClmCntLdShdLvlRq "ENM";
BA_ "SignalLongName" SG_ 2155970560 ClmCntLdShdLvlRq "Climate Control Load Shedding Level Request";
BA_ "VNSigAllNodes" SG_ 2155970560 ClmCntLdShdLvlRq 1;
BA_ "GenSigSendType" SG_ 2155970560 ClmCntBatSaverIO 10;
BA_ "SignalType" SG_ 2155970560 ClmCntBatSaverIO "BLN";
BA_ "SignalLongName" SG_ 2155970560 ClmCntBatSaverIO "Climate Control Battery Saver Indication On";
BA_ "VNSigAllNodes" SG_ 2155970560 ClmCntBatSaverIO 1;
BA_ "GenSigSendType" SG_ 2151178240 TrlrMirVGlnCustSetReq 10;
BA_ "SignalType" SG_ 2151178240 TrlrMirVGlnCustSetReq "ENM";
BA_ "SignalLongName" SG_ 2151178240 TrlrMirVGlnCustSetReq "Trailering Mirror Video Guidelines Customization Setting Request";
BA_ "VNSigAllNodes" SG_ 2151178240 TrlrMirVGlnCustSetReq 1;
BA_ "GenSigSendType" SG_ 2151178240 TrlrMirVEnCustSetReq 10;
BA_ "SignalType" SG_ 2151178240 TrlrMirVEnCustSetReq "ENM";
BA_ "SignalLongName" SG_ 2151178240 TrlrMirVEnCustSetReq "Trailering Mirror Video Enable Customization Setting Request";
BA_ "VNSigAllNodes" SG_ 2151178240 TrlrMirVEnCustSetReq 1;
BA_ "GenSigSendType" SG_ 2151178240 JacknfDetCustSetReq 10;
BA_ "SignalType" SG_ 2151178240 JacknfDetCustSetReq "ENM";
BA_ "SignalLongName" SG_ 2151178240 JacknfDetCustSetReq "Jack Knife Detection Customization Setting Request";
BA_ "VNSigAllNodes" SG_ 2151178240 JacknfDetCustSetReq 1;
BA_ "GenSigSendType" SG_ 2151178240 CrgBdVwLtCustSetReq 10;
BA_ "SignalType" SG_ 2151178240 CrgBdVwLtCustSetReq "ENM";
BA_ "SignalLongName" SG_ 2151178240 CrgBdVwLtCustSetReq "Cargo Bed View Auto Lighting Customization Setting Request";
BA_ "VNSigAllNodes" SG_ 2151178240 CrgBdVwLtCustSetReq 1;
BA_ "GenSigSendType" SG_ 2151178240 AFLGPSCstStReq 10;
BA_ "SignalType" SG_ 2151178240 AFLGPSCstStReq "ENM";
BA_ "SignalLongName" SG_ 2151178240 AFLGPSCstStReq "Adaptive Forward Lighting With GPS Customization Setting Request";
BA_ "VNSigAllNodes" SG_ 2151178240 AFLGPSCstStReq 1;
BA_ "GenSigSendType" SG_ 2151178240 AFLCstStReq 10;
BA_ "SignalType" SG_ 2151178240 AFLCstStReq "ENM";
BA_ "SignalLongName" SG_ 2151178240 AFLCstStReq "Adaptive Forward Lighting Customization Setting Request";
BA_ "VNSigAllNodes" SG_ 2151178240 AFLCstStReq 1;
BA_ "GenSigSendType" SG_ 2151178240 LtRtHnTrCstStReq 10;
BA_ "SignalType" SG_ 2151178240 LtRtHnTrCstStReq "ENM";
BA_ "SignalLongName" SG_ 2151178240 LtRtHnTrCstStReq "Left Right Hand Traffic Customization Setting Request";
BA_ "VNSigAllNodes" SG_ 2151178240 LtRtHnTrCstStReq 1;
BA_ "GenSigSendType" SG_ 2151178240 AdpHgBmAsSnCsStRq 10;
BA_ "SignalType" SG_ 2151178240 AdpHgBmAsSnCsStRq "ENM";
BA_ "SignalLongName" SG_ 2151178240 AdpHgBmAsSnCsStRq "Adaptive High Beam Assist With Sensitivity Customization Setting Request";
BA_ "VNSigAllNodes" SG_ 2151178240 AdpHgBmAsSnCsStRq 1;
BA_ "GenSigSendType" SG_ 2151178240 AdpHgBmAstCstStRq 10;
BA_ "SignalType" SG_ 2151178240 AdpHgBmAstCstStRq "ENM";
BA_ "SignalLongName" SG_ 2151178240 AdpHgBmAstCstStRq "Adaptive High Beam Assist Customization Setting Request";
BA_ "VNSigAllNodes" SG_ 2151178240 AdpHgBmAstCstStRq 1;
BA_ "GenSigSendType" SG_ 2151178240 LtRtHnTrGPSCstStRq 10;
BA_ "SignalType" SG_ 2151178240 LtRtHnTrGPSCstStRq "ENM";
BA_ "SignalLongName" SG_ 2151178240 LtRtHnTrGPSCstStRq "Left Right Hand Traffic With GPS Customization Setting Request";
BA_ "VNSigAllNodes" SG_ 2151178240 LtRtHnTrGPSCstStRq 1;
BA_ "GenSigSendType" SG_ 2151178240 AutHgBmAsSnCsStRq 10;
BA_ "SignalType" SG_ 2151178240 AutHgBmAsSnCsStRq "ENM";
BA_ "SignalLongName" SG_ 2151178240 AutHgBmAsSnCsStRq "Auto High Beam Assist With Sensitivity Customization Setting Request";
BA_ "VNSigAllNodes" SG_ 2151178240 AutHgBmAsSnCsStRq 1;
BA_ "GenSigSendType" SG_ 2151178240 AutHgBmAstCstStRq 10;
BA_ "SignalType" SG_ 2151178240 AutHgBmAstCstStRq "ENM";
BA_ "SignalLongName" SG_ 2151178240 AutHgBmAstCstStRq "Auto High Beam Assist Customization Setting Request";
BA_ "VNSigAllNodes" SG_ 2151178240 AutHgBmAstCstStRq 1;
BA_ "GenSigSendType" SG_ 2154790912 AdpHgBmAsSnCsCrStVal 10;
BA_ "GenSigSendOnInit" SG_ 2154790912 AdpHgBmAsSnCsCrStVal 2;
BA_ "SignalType" SG_ 2154790912 AdpHgBmAsSnCsCrStVal "ENM";
BA_ "SignalLongName" SG_ 2154790912 AdpHgBmAsSnCsCrStVal "Adaptive High Beam Assist With Sensitivity Customization Current Setting Value";
BA_ "VNSigAllNodes" SG_ 2154790912 AdpHgBmAsSnCsCrStVal 1;
BA_ "GenSigSendType" SG_ 2154790912 AdpHgBmAsSnCsStAvl 10;
BA_ "GenSigSendOnInit" SG_ 2154790912 AdpHgBmAsSnCsStAvl 2;
BA_ "SignalType" SG_ 2154790912 AdpHgBmAsSnCsStAvl "BLN";
BA_ "SignalLongName" SG_ 2154790912 AdpHgBmAsSnCsStAvl "Adaptive High Beam Assist With Sensitivity Customization Setting Available";
BA_ "VNSigAllNodes" SG_ 2154790912 AdpHgBmAsSnCsStAvl 1;
BA_ "GenSigSendType" SG_ 2154790912 AdpHgBmAsCsCrStVal 10;
BA_ "GenSigSendOnInit" SG_ 2154790912 AdpHgBmAsCsCrStVal 2;
BA_ "SignalType" SG_ 2154790912 AdpHgBmAsCsCrStVal "ENM";
BA_ "SignalLongName" SG_ 2154790912 AdpHgBmAsCsCrStVal "Adaptive High Beam Assist Customization Current Setting Value";
BA_ "VNSigAllNodes" SG_ 2154790912 AdpHgBmAsCsCrStVal 1;
BA_ "GenSigSendType" SG_ 2154790912 AdpHgBmAsCsStAvl 10;
BA_ "GenSigSendOnInit" SG_ 2154790912 AdpHgBmAsCsStAvl 2;
BA_ "SignalType" SG_ 2154790912 AdpHgBmAsCsStAvl "BLN";
BA_ "SignalLongName" SG_ 2154790912 AdpHgBmAsCsStAvl "Adaptive High Beam Assist Customization Setting Available";
BA_ "VNSigAllNodes" SG_ 2154790912 AdpHgBmAsCsStAvl 1;
BA_ "GenSigSendType" SG_ 2154790912 AutHgBmAsCsCrStVal 10;
BA_ "GenSigSendOnInit" SG_ 2154790912 AutHgBmAsCsCrStVal 2;
BA_ "SignalType" SG_ 2154790912 AutHgBmAsCsCrStVal "ENM";
BA_ "SignalLongName" SG_ 2154790912 AutHgBmAsCsCrStVal "Auto High Beam Assist Customization Current Setting Value";
BA_ "VNSigAllNodes" SG_ 2154790912 AutHgBmAsCsCrStVal 1;
BA_ "GenSigSendType" SG_ 2154790912 AutHgBmAsSnCsStAvl 10;
BA_ "GenSigSendOnInit" SG_ 2154790912 AutHgBmAsSnCsStAvl 2;
BA_ "SignalType" SG_ 2154790912 AutHgBmAsSnCsStAvl "BLN";
BA_ "SignalLongName" SG_ 2154790912 AutHgBmAsSnCsStAvl "Auto High Beam Assist With Sensitivity Customization Setting Available";
BA_ "VNSigAllNodes" SG_ 2154790912 AutHgBmAsSnCsStAvl 1;
BA_ "GenSigSendType" SG_ 2154790912 AutHgBmAsSnCsCrStVa 10;
BA_ "GenSigSendOnInit" SG_ 2154790912 AutHgBmAsSnCsCrStVa 2;
BA_ "SignalType" SG_ 2154790912 AutHgBmAsSnCsCrStVa "ENM";
BA_ "SignalLongName" SG_ 2154790912 AutHgBmAsSnCsCrStVa "Auto High Beam Assist With Sensitivity Customization Current Setting Value";
BA_ "VNSigAllNodes" SG_ 2154790912 AutHgBmAsSnCsCrStVa 1;
BA_ "GenSigSendType" SG_ 2154790912 AutHgBmAsCsStAvl 10;
BA_ "GenSigSendOnInit" SG_ 2154790912 AutHgBmAsCsStAvl 2;
BA_ "SignalType" SG_ 2154790912 AutHgBmAsCsStAvl "BLN";
BA_ "SignalLongName" SG_ 2154790912 AutHgBmAsCsStAvl "Auto High Beam Assist Customization Setting Available";
BA_ "VNSigAllNodes" SG_ 2154790912 AutHgBmAsCsStAvl 1;
BA_REL_ "GenSigSuprvResp" BU_SG_REL_ CSM_LS SG_ 2152775680 CrgBdVwLtCustSetVal 1;
BA_REL_ "GenSigSuprvResp" BU_SG_REL_ RadioHead_LS SG_ 2152775680 CrgBdVwLtCustSetVal 1;
BA_REL_ "GenSigSuprvResp" BU_SG_REL_ CSM_LS SG_ 2152775680 CrgBdVwLtCustSetAvl 1;
BA_REL_ "GenSigSuprvResp" BU_SG_REL_ RadioHead_LS SG_ 2152775680 CrgBdVwLtCustSetAvl 1;
BA_REL_ "GenSigSuprvResp" BU_SG_REL_ CSM_LS SG_ 2152775680 TrlrMirVGlnCustSetVal 1;
BA_REL_ "GenSigSuprvResp" BU_SG_REL_ RadioHead_LS SG_ 2152775680 TrlrMirVGlnCustSetVal 1;
BA_REL_ "GenSigSuprvResp" BU_SG_REL_ CSM_LS SG_ 2152775680 TrlrMirVGlnCustSetAvl 1;
BA_REL_ "GenSigSuprvResp" BU_SG_REL_ RadioHead_LS SG_ 2152775680 TrlrMirVGlnCustSetAvl 1;
BA_REL_ "GenSigSuprvResp" BU_SG_REL_ CSM_LS SG_ 2152775680 TrlrMirVEnCustSetVal 1;
BA_REL_ "GenSigSuprvResp" BU_SG_REL_ RadioHead_LS SG_ 2152775680 TrlrMirVEnCustSetVal 1;
BA_REL_ "GenSigSuprvResp" BU_SG_REL_ CSM_LS SG_ 2152775680 TrlrMirVEnCustSetAvl 1;
BA_REL_ "GenSigSuprvResp" BU_SG_REL_ RadioHead_LS SG_ 2152775680 TrlrMirVEnCustSetAvl 1;
BA_REL_ "GenSigSuprvResp" BU_SG_REL_ CSM_LS SG_ 2152775680 TrlrArtcltnAnglCalStat 1;
BA_REL_ "GenSigSuprvResp" BU_SG_REL_ RadioHead_LS SG_ 2152775680 TrlrArtcltnAnglCalStat 1;
BA_REL_ "GenSigSuprvResp" BU_SG_REL_ CSM_LS SG_ 2152775680 InvTrlrAx1CamRollAlgnd 1;
BA_REL_ "GenSigSuprvResp" BU_SG_REL_ RadioHead_LS SG_ 2152775680 InvTrlrAx1CamRollAlgnd 1;
BA_REL_ "GenSigSuprvResp" BU_SG_REL_ CSM_LS SG_ 2152775680 InvTrlrAx1CamPtchAlgnd 1;
BA_REL_ "GenSigSuprvResp" BU_SG_REL_ RadioHead_LS SG_ 2152775680 InvTrlrAx1CamPtchAlgnd 1;
BA_REL_ "GenSigSuprvResp" BU_SG_REL_ CSM_LS SG_ 2152775680 InvTrlrAx1CamYAlgnd 1;
BA_REL_ "GenSigSuprvResp" BU_SG_REL_ RadioHead_LS SG_ 2152775680 InvTrlrAx1CamYAlgnd 1;
BA_REL_ "GenSigSuprvResp" BU_SG_REL_ CSM_LS SG_ 2152775680 InvTrlrAx1CamXAlgnd 1;
BA_REL_ "GenSigSuprvResp" BU_SG_REL_ RadioHead_LS SG_ 2152775680 InvTrlrAx1CamXAlgnd 1;
BA_REL_ "GenSigRxStartValue" BU_SG_REL_ CSM_LS SG_ 2152775680 RPDCA_Resrv3Avail "0";
BA_REL_ "GenSigRxStartValue" BU_SG_REL_ RadioHead_LS SG_ 2152775680 RPDCA_Resrv3Avail "0";
BA_REL_ "GenSigRxStartValue" BU_SG_REL_ CSM_LS SG_ 2152775680 RPDCA_Resrv2Avail "0";
BA_REL_ "GenSigRxStartValue" BU_SG_REL_ RadioHead_LS SG_ 2152775680 RPDCA_Resrv2Avail "0";
BA_REL_ "GenSigRxStartValue" BU_SG_REL_ CSM_LS SG_ 2152775680 RPDCA_Resrv1Avail "0";
BA_REL_ "GenSigRxStartValue" BU_SG_REL_ RadioHead_LS SG_ 2152775680 RPDCA_Resrv1Avail "0";
BA_REL_ "GenSigRxStartValue" BU_SG_REL_ CSM_LS SG_ 2152775680 RPDCA_AlrtBrkAvail "0";
BA_REL_ "GenSigRxStartValue" BU_SG_REL_ RadioHead_LS SG_ 2152775680 RPDCA_AlrtBrkAvail "0";
BA_REL_ "GenSigRxStartValue" BU_SG_REL_ CSM_LS SG_ 2152775680 RPDCA_AlrtAvail "0";
BA_REL_ "GenSigRxStartValue" BU_SG_REL_ RadioHead_LS SG_ 2152775680 RPDCA_AlrtAvail "0";
BA_REL_ "GenSigRxStartValue" BU_SG_REL_ CSM_LS SG_ 2152775680 RPDCA_OnAvail "1";
BA_REL_ "GenSigRxStartValue" BU_SG_REL_ RadioHead_LS SG_ 2152775680 RPDCA_OnAvail "1";
BA_REL_ "GenSigRxStartValue" BU_SG_REL_ CSM_LS SG_ 2152775680 RPDCA_OfAvail "1";
BA_REL_ "GenSigRxStartValue" BU_SG_REL_ RadioHead_LS SG_ 2152775680 RPDCA_OfAvail "1";
BA_REL_ "GenSigSuprvResp" BU_SG_REL_ MSM_P_LS SG_ 2152775680 JacknfDetRHapSReqSN 1;
BA_REL_ "GenSigSuprvResp" BU_SG_REL_ MSM_LS SG_ 2152775680 JacknfDetRHapSReqSN 1;
BA_REL_ "GenSigSuprvResp" BU_SG_REL_ MSM_P_LS SG_ 2152775680 JacknfDetRHapSReq 1;
BA_REL_ "GenSigSuprvResp" BU_SG_REL_ MSM_LS SG_ 2152775680 JacknfDetRHapSReq 1;
BA_REL_ "GenSigSuprvResp" BU_SG_REL_ MSM_P_LS SG_ 2152775680 JacknfDetLHapSReqSN 1;
BA_REL_ "GenSigSuprvResp" BU_SG_REL_ MSM_LS SG_ 2152775680 JacknfDetLHapSReqSN 1;
BA_REL_ "GenSigSuprvResp" BU_SG_REL_ MSM_P_LS SG_ 2152775680 JacknfDetLHapSReq 1;
BA_REL_ "GenSigSuprvResp" BU_SG_REL_ MSM_LS SG_ 2152775680 JacknfDetLHapSReq 1;
BA_REL_ "GenSigSuprvResp" BU_SG_REL_ CSM_LS SG_ 2152775680 JacknfDetCustSetVal 1;
BA_REL_ "GenSigSuprvResp" BU_SG_REL_ RadioHead_LS SG_ 2152775680 JacknfDetCustSetVal 1;
BA_REL_ "GenSigSuprvResp" BU_SG_REL_ CSM_LS SG_ 2152775680 JacknfDetCustSetAvl 1;
BA_REL_ "GenSigSuprvResp" BU_SG_REL_ RadioHead_LS SG_ 2152775680 JacknfDetCustSetAvl 1;
BA_REL_ "GenSigSuprvResp" BU_SG_REL_ CSM_LS SG_ 2152775680 DispTrgdVidOn 1;
BA_REL_ "GenSigSuprvResp" BU_SG_REL_ RadioHead_LS SG_ 2152775680 DispTrgdVidOn 1;
BA_REL_ "GenSigSuprvResp" BU_SG_REL_ CSM_LS SG_ 2152775680 a_360DegVidFetrPrsnt 1;
BA_REL_ "GenSigSuprvResp" BU_SG_REL_ RadioHead_LS SG_ 2152775680 a_360DegVidFetrPrsnt 1;
BA_REL_ "GenSigSuprvResp" BU_SG_REL_ CSM_LS SG_ 2152775680 TrgdVidRecFetrPrsnt 1;
BA_REL_ "GenSigSuprvResp" BU_SG_REL_ RadioHead_LS SG_ 2152775680 TrgdVidRecFetrPrsnt 1;
BA_REL_ "GenSigSuprvResp" BU_SG_REL_ MSM_P_LS SG_ 2152775680 RrPdDetHptcStVbRq 1;
BA_REL_ "GenSigSuprvResp" BU_SG_REL_ MSM_LS SG_ 2152775680 RrPdDetHptcStVbRq 1;
BA_REL_ "GenSigSuprvResp" BU_SG_REL_ MSM_P_LS SG_ 2152775680 RrPdDetHptcStVbRqSeqN 1;
BA_REL_ "GenSigSuprvResp" BU_SG_REL_ MSM_LS SG_ 2152775680 RrPdDetHptcStVbRqSeqN 1;
BA_REL_ "GenSigSuprvResp" BU_SG_REL_ CSM_LS SG_ 2152775680 DispSmrtTwVidOn 1;
BA_REL_ "GenSigSuprvResp" BU_SG_REL_ RadioHead_LS SG_ 2152775680 DispSmrtTwVidOn 1;
BA_REL_ "GenSigSuprvResp" BU_SG_REL_ CSM_LS SG_ 2152775680 DispFrt360CamOn 1;
BA_REL_ "GenSigSuprvResp" BU_SG_REL_ RadioHead_LS SG_ 2152775680 DispFrt360CamOn 1;
BA_REL_ "GenSigSuprvResp" BU_SG_REL_ BCM_LS SG_ 2153865216 TnDrvStBltShftIntrlkCsStRq 1;
BA_REL_ "GenSigSuprvResp" BU_SG_REL_ BCM_LS SG_ 2153865216 StBltShftIntrlkCsStRq 1;
BA_REL_ "GenSigSuprvResp" BU_SG_REL_ BCM_LS SG_ 2153865216 TeenDrvReq 1;
BA_REL_ "GenSigSuprvResp" BU_SG_REL_ BCM_LS SG_ 2153865216 TeenDrvPinCd 1;
BA_REL_ "GenSigSuprvResp" BU_SG_REL_ BCM_LS SG_ 2153865216 TnDrvSpdLmtCstStReq 1;
BA_REL_ "GenSigSuprvResp" BU_SG_REL_ BCM_LS SG_ 2153865216 TDOWCSR_StatReq 1;
BA_REL_ "GenSigSuprvResp" BU_SG_REL_ BCM_LS SG_ 2153865216 TDOWCSR_IncSwAct 1;
BA_REL_ "GenSigSuprvResp" BU_SG_REL_ BCM_LS SG_ 2153865216 TDOWCSR_DecSwAct 1;
BA_REL_ "GenSigSuprvResp" BU_SG_REL_ IPC_LS SG_ 2153840640 TnDrvDRLOffUnbIO 1;
BA_REL_ "GenSigSuprvResp" BU_SG_REL_ IPC_LS SG_ 2153840640 TnDrvALCOffUnbIO 1;
BA_REL_ "GenSigSuprvResp" BU_SG_REL_ V2V_LS SG_ 2153824256 TeenDrvAct 1;
BA_REL_ "GenSigSuprvResp" BU_SG_REL_ SBZA_R_LS SG_ 2153824256 TeenDrvAct 1;
BA_REL_ "GenSigSuprvResp" BU_SG_REL_ IPC_LS SG_ 2153824256 TeenDrvAct 1;
BA_REL_ "GenSigSuprvResp" BU_SG_REL_ SBZA_L_LS SG_ 2153824256 TeenDrvAct 1;
BA_REL_ "GenSigSuprvResp" BU_SG_REL_ SBZA_L_LS SG_ 2153824256 TeenDrvAct 1;
BA_REL_ "GenSigSuprvResp" BU_SG_REL_ UPA_LS SG_ 2153824256 TeenDrvAct 1;
BA_REL_ "GenSigSuprvResp" BU_SG_REL_ APA_LS SG_ 2153824256 TeenDrvAct 1;
BA_REL_ "GenSigSuprvResp" BU_SG_REL_ VIS2_LS SG_ 2153824256 TeenDrvAct 1;
BA_REL_ "GenSigSuprvResp" BU_SG_REL_ FCM_LS SG_ 2153824256 TeenDrvAct 1;
BA_REL_ "GenSigSuprvResp" BU_SG_REL_ FCM_LS SG_ 2153824256 TeenDrvAct 1;
BA_REL_ "GenSigSuprvResp" BU_SG_REL_ FCM_LS SG_ 2153824256 TeenDrvAct 1;
BA_REL_ "GenSigSuprvResp" BU_SG_REL_ FCM_LS SG_ 2153824256 TeenDrvAct 1;
BA_REL_ "GenSigSuprvResp" BU_SG_REL_ EOCM_F_LS SG_ 2153824256 TeenDrvAct 1;
BA_REL_ "GenSigSuprvResp" BU_SG_REL_ EOCM_F_LS SG_ 2153824256 TeenDrvAct 1;
BA_REL_ "GenSigSuprvResp" BU_SG_REL_ EOCM_F_LS SG_ 2153824256 TeenDrvAct 1;
BA_REL_ "GenSigSuprvResp" BU_SG_REL_ EOCM_F_LS SG_ 2153824256 TeenDrvAct 1;
BA_REL_ "GenSigSuprvResp" BU_SG_REL_ IPC_LS SG_ 2153824256 TnDrvGapAdjUnbIO 1;
BA_REL_ "GenSigSuprvResp" BU_SG_REL_ IPC_LS SG_ 2153824256 TnDrvOvrSpdIO 1;
BA_REL_ "GenSigSuprvResp" BU_SG_REL_ IPC_LS SG_ 2153824256 TDOWCCSV_CrStVl 1;
BA_REL_ "GenSigSuprvResp" BU_SG_REL_ IPC_LS SG_ 2153824256 TDOWCCSV_CrStat 1;
BA_REL_ "GenSigSuprvResp" BU_SG_REL_ IPC_LS SG_ 2153824256 TDSLCCSV_SpLmtStat 1;
BA_REL_ "GenSigSuprvResp" BU_SG_REL_ IPC_LS SG_ 2153824256 TDSLCCSV_SpLmDisVl 1;
BA_REL_ "GenSigSuprvResp" BU_SG_REL_ MSM_RR_LS SG_ 2155134976 PsngrSetRrwdMvmnt 1;
BA_REL_ "GenSigSuprvResp" BU_SG_REL_ EOCM2B_K1_LS SG_ 2155085824 StrgColUpDwnPos 1;
BA_REL_ "GenSigSuprvResp" BU_SG_REL_ EOCM2A_K1_LS SG_ 2155085824 StrgColUpDwnPos 1;
BA_REL_ "GenSigSuprvResp" BU_SG_REL_ EOCM2B_K1_LS SG_ 2155085824 CPMAPINFO4 1;
BA_REL_ "GenSigSuprvResp" BU_SG_REL_ EOCM2A_K1_LS SG_ 2155085824 CPMAPINFO4 1;
BA_REL_ "GenSigSuprvResp" BU_SG_REL_ EOCM2B_K1_LS SG_ 2155085824 StrgColInOutPos 1;
BA_REL_ "GenSigSuprvResp" BU_SG_REL_ EOCM2A_K1_LS SG_ 2155085824 StrgColInOutPos 1;
BA_REL_ "GenSigSuprvResp" BU_SG_REL_ EOCM2B_K1_LS SG_ 2155085824 StrgColCommsFlt 1;
BA_REL_ "GenSigSuprvResp" BU_SG_REL_ EOCM2A_K1_LS SG_ 2155085824 StrgColCommsFlt 1;
BA_REL_ "GenSigSuprvResp" BU_SG_REL_ IPC_LS SG_ 2153791488 ArtcldRngBrdSt 1;
BA_REL_ "GenSigSuprvResp" BU_SG_REL_ ONSTAR_LS SG_ 2149883904 BTPR_RspVal 1;
BA_REL_ "GenSigSuprvResp" BU_SG_REL_ ONSTAR_LS SG_ 2149883904 BTPR_RspInfoAvail 1;
BA_REL_ "GenSigSuprvResp" BU_SG_REL_ ONSTAR_LS SG_ 2149883904 BTPR_RspStat 1;
BA_REL_ "GenSigSuprvResp" BU_SG_REL_ CSM_LS SG_ 2150252544 ECHG_YAxisMaxVal 1;
BA_REL_ "GenSigSuprvResp" BU_SG_REL_ RadioHead_LS SG_ 2150252544 ECHG_YAxisMaxVal 1;
BA_REL_ "GenSigSuprvResp" BU_SG_REL_ CSM_LS SG_ 2150252544 ECHG_XAxisTkMrkIntvl 1;
BA_REL_ "GenSigSuprvResp" BU_SG_REL_ RadioHead_LS SG_ 2150252544 ECHG_XAxisTkMrkIntvl 1;
BA_REL_ "GenSigSuprvResp" BU_SG_REL_ CSM_LS SG_ 2150252544 ECHG_Column10 1;
BA_REL_ "GenSigSuprvResp" BU_SG_REL_ RadioHead_LS SG_ 2150252544 ECHG_Column10 1;
BA_REL_ "GenSigSuprvResp" BU_SG_REL_ CSM_LS SG_ 2150252544 ECHG_Column09 1;
BA_REL_ "GenSigSuprvResp" BU_SG_REL_ RadioHead_LS SG_ 2150252544 ECHG_Column09 1;
BA_REL_ "GenSigSuprvResp" BU_SG_REL_ CSM_LS SG_ 2150252544 ECHG_Column08 1;
BA_REL_ "GenSigSuprvResp" BU_SG_REL_ RadioHead_LS SG_ 2150252544 ECHG_Column08 1;
BA_REL_ "GenSigSuprvResp" BU_SG_REL_ CSM_LS SG_ 2150252544 ECHG_Column07 1;
BA_REL_ "GenSigSuprvResp" BU_SG_REL_ RadioHead_LS SG_ 2150252544 ECHG_Column07 1;
BA_REL_ "GenSigSuprvResp" BU_SG_REL_ CSM_LS SG_ 2150252544 ECHG_Column06 1;
BA_REL_ "GenSigSuprvResp" BU_SG_REL_ RadioHead_LS SG_ 2150252544 ECHG_Column06 1;
BA_REL_ "GenSigSuprvResp" BU_SG_REL_ CSM_LS SG_ 2150252544 ECHG_Column05 1;
BA_REL_ "GenSigSuprvResp" BU_SG_REL_ RadioHead_LS SG_ 2150252544 ECHG_Column05 1;
BA_REL_ "GenSigSuprvResp" BU_SG_REL_ CSM_LS SG_ 2150252544 ECHG_Column04 1;
BA_REL_ "GenSigSuprvResp" BU_SG_REL_ RadioHead_LS SG_ 2150252544 ECHG_Column04 1;
BA_REL_ "GenSigSuprvResp" BU_SG_REL_ CSM_LS SG_ 2150252544 ECHG_Column03 1;
BA_REL_ "GenSigSuprvResp" BU_SG_REL_ RadioHead_LS SG_ 2150252544 ECHG_Column03 1;
BA_REL_ "GenSigSuprvResp" BU_SG_REL_ CSM_LS SG_ 2150252544 ECHG_Column02 1;
BA_REL_ "GenSigSuprvResp" BU_SG_REL_ RadioHead_LS SG_ 2150252544 ECHG_Column02 1;
BA_REL_ "GenSigSuprvResp" BU_SG_REL_ CSM_LS SG_ 2150252544 ECHG_Column01 1;
BA_REL_ "GenSigSuprvResp" BU_SG_REL_ RadioHead_LS SG_ 2150252544 ECHG_Column01 1;
BA_REL_ "GenSigSuprvResp" BU_SG_REL_ CSM_LS SG_ 2150252544 ECHG_EngyCnsmdAvg 1;
BA_REL_ "GenSigSuprvResp" BU_SG_REL_ RadioHead_LS SG_ 2150252544 ECHG_EngyCnsmdAvg 1;
BA_REL_ "GenSigSuprvResp" BU_SG_REL_ CSM_LS SG_ 2150252544 ECHG_MeasUnit 1;
BA_REL_ "GenSigSuprvResp" BU_SG_REL_ RadioHead_LS SG_ 2150252544 ECHG_MeasUnit 1;
BA_REL_ "GenSigSuprvResp" BU_SG_REL_ BCM_LS SG_ 2150391808 EngRunAtvTm 1;
BA_REL_ "GenSigSuprvResp" BU_SG_REL_ BCM_LS SG_ 2150391808 EngIdlAtvTm 1;
BA_REL_ "GenSigSuprvResp" BU_SG_REL_ IPC_LS SG_ 2155913216 PFAS_SrvPedAlrtIO 1;
BA_REL_ "GenSigSuprvResp" BU_SG_REL_ IPC_LS SG_ 2155913216 PFAS_PFASysStat 1;
BA_REL_ "GenSigSuprvResp" BU_SG_REL_ IPC_LS SG_ 2155913216 PFAS_PFASndVolCtrl 1;
BA_REL_ "GenSigSuprvResp" BU_SG_REL_ IPC_LS SG_ 2155913216 PFAS_PFASndGenEn 1;
BA_REL_ "GenSigSuprvResp" BU_SG_REL_ IPC_LS SG_ 2155913216 PFAS_PFARevSnd 1;
BA_REL_ "GenSigSuprvResp" BU_SG_REL_ IPC_LS SG_ 2155913216 PFAS_PFAFwdSnd 1;
BA_REL_ "GenSigSuprvResp" BU_SG_REL_ IPC_LS SG_ 2155913216 PFAS_PFACrsOvrSpd 1;
BA_REL_ "GenSigSuprvResp" BU_SG_REL_ CSM_LS SG_ 2155913216 PedFrndlyAlrtCsSetAvl 1;
BA_REL_ "GenSigSuprvResp" BU_SG_REL_ RadioHead_LS SG_ 2155913216 PedFrndlyAlrtCsSetAvl 1;
BA_REL_ "GenSigSuprvResp" BU_SG_REL_ CSM_LS SG_ 2155913216 PedFrndlyAlrtCsCrStVal 1;
BA_REL_ "GenSigSuprvResp" BU_SG_REL_ RadioHead_LS SG_ 2155913216 PedFrndlyAlrtCsCrStVal 1;
BA_REL_ "GenSigSuprvResp" BU_SG_REL_ IPC_LS SG_ 2155913216 DslExhFldRmngDstHRs 1;
BA_REL_ "GenSigSuprvResp" BU_SG_REL_ IPC_LS SG_ 2155913216 DslExhFluidLvlPrcnt 1;
BA_REL_ "GenSigSuprvResp" BU_SG_REL_ IPC_LS SG_ 2155913216 DslEmnsOBDMrkt 1;
BA_REL_ "GenSigSuprvResp" BU_SG_REL_ CSM_LS SG_ 2152095744 SPMCA_SusPrfMd6Avl 1;
BA_REL_ "GenSigSuprvResp" BU_SG_REL_ RadioHead_LS SG_ 2152095744 SPMCA_SusPrfMd6Avl 1;
BA_REL_ "GenSigSuprvResp" BU_SG_REL_ CSM_LS SG_ 2152095744 SPMCA_SusPrfMd5Avl 1;
BA_REL_ "GenSigSuprvResp" BU_SG_REL_ RadioHead_LS SG_ 2152095744 SPMCA_SusPrfMd5Avl 1;
BA_REL_ "GenSigSuprvResp" BU_SG_REL_ CSM_LS SG_ 2152095744 SPMCA_SusPrfMd4Avl 1;
BA_REL_ "GenSigSuprvResp" BU_SG_REL_ RadioHead_LS SG_ 2152095744 SPMCA_SusPrfMd4Avl 1;
BA_REL_ "GenSigSuprvResp" BU_SG_REL_ CSM_LS SG_ 2152095744 SPMCA_SusPrfMd3Avl 1;
BA_REL_ "GenSigSuprvResp" BU_SG_REL_ RadioHead_LS SG_ 2152095744 SPMCA_SusPrfMd3Avl 1;
BA_REL_ "GenSigSuprvResp" BU_SG_REL_ CSM_LS SG_ 2152095744 SPMCA_SusPrfMd2Avl 1;
BA_REL_ "GenSigSuprvResp" BU_SG_REL_ RadioHead_LS SG_ 2152095744 SPMCA_SusPrfMd2Avl 1;
BA_REL_ "GenSigSuprvResp" BU_SG_REL_ CSM_LS SG_ 2152095744 SPMCA_SusPrfMd1Avl 1;
BA_REL_ "GenSigSuprvResp" BU_SG_REL_ RadioHead_LS SG_ 2152095744 SPMCA_SusPrfMd1Avl 1;
BA_REL_ "GenSigSuprvResp" BU_SG_REL_ CSM_LS SG_ 2152095744 SPMCA_StrPrfMd6Avl 1;
BA_REL_ "GenSigSuprvResp" BU_SG_REL_ RadioHead_LS SG_ 2152095744 SPMCA_StrPrfMd6Avl 1;
BA_REL_ "GenSigSuprvResp" BU_SG_REL_ CSM_LS SG_ 2152095744 SPMCA_StrPrfMd5Avl 1;
BA_REL_ "GenSigSuprvResp" BU_SG_REL_ RadioHead_LS SG_ 2152095744 SPMCA_StrPrfMd5Avl 1;
BA_REL_ "GenSigSuprvResp" BU_SG_REL_ CSM_LS SG_ 2152095744 SPMCA_StrPrfMd4Avl 1;
BA_REL_ "GenSigSuprvResp" BU_SG_REL_ RadioHead_LS SG_ 2152095744 SPMCA_StrPrfMd4Avl 1;
BA_REL_ "GenSigSuprvResp" BU_SG_REL_ CSM_LS SG_ 2152095744 SPMCA_StrPrfMd3Avl 1;
BA_REL_ "GenSigSuprvResp" BU_SG_REL_ RadioHead_LS SG_ 2152095744 SPMCA_StrPrfMd3Avl 1;
BA_REL_ "GenSigSuprvResp" BU_SG_REL_ CSM_LS SG_ 2152095744 SPMCA_StrPrfMd2Avl 1;
BA_REL_ "GenSigSuprvResp" BU_SG_REL_ RadioHead_LS SG_ 2152095744 SPMCA_StrPrfMd2Avl 1;
BA_REL_ "GenSigSuprvResp" BU_SG_REL_ CSM_LS SG_ 2152095744 SPMCA_StrPrfMd1Avl 1;
BA_REL_ "GenSigSuprvResp" BU_SG_REL_ RadioHead_LS SG_ 2152095744 SPMCA_StrPrfMd1Avl 1;
BA_REL_ "GenSigSuprvResp" BU_SG_REL_ CSM_LS SG_ 2152095744 SPMCA_SndPrfMd6Avl 1;
BA_REL_ "GenSigSuprvResp" BU_SG_REL_ RadioHead_LS SG_ 2152095744 SPMCA_SndPrfMd6Avl 1;
BA_REL_ "GenSigSuprvResp" BU_SG_REL_ CSM_LS SG_ 2152095744 SPMCA_SndPrfMd5Avl 1;
BA_REL_ "GenSigSuprvResp" BU_SG_REL_ RadioHead_LS SG_ 2152095744 SPMCA_SndPrfMd5Avl 1;
BA_REL_ "GenSigSuprvResp" BU_SG_REL_ CSM_LS SG_ 2152095744 SPMCA_SndPrfMd4Avl 1;
BA_REL_ "GenSigSuprvResp" BU_SG_REL_ RadioHead_LS SG_ 2152095744 SPMCA_SndPrfMd4Avl 1;
BA_REL_ "GenSigSuprvResp" BU_SG_REL_ CSM_LS SG_ 2152095744 SPMCA_SndPrfMd3Avl 1;
BA_REL_ "GenSigSuprvResp" BU_SG_REL_ RadioHead_LS SG_ 2152095744 SPMCA_SndPrfMd3Avl 1;
BA_REL_ "GenSigSuprvResp" BU_SG_REL_ CSM_LS SG_ 2152095744 SPMCA_SndPrfMd2Avl 1;
BA_REL_ "GenSigSuprvResp" BU_SG_REL_ RadioHead_LS SG_ 2152095744 SPMCA_SndPrfMd2Avl 1;
BA_REL_ "GenSigSuprvResp" BU_SG_REL_ CSM_LS SG_ 2152095744 SPMCA_SndPrfMd1Avl 1;
BA_REL_ "GenSigSuprvResp" BU_SG_REL_ RadioHead_LS SG_ 2152095744 SPMCA_SndPrfMd1Avl 1;
BA_REL_ "GenSigSuprvResp" BU_SG_REL_ CSM_LS SG_ 2152095744 DPMCA_DispPrfMd6Avl 1;
BA_REL_ "GenSigSuprvResp" BU_SG_REL_ CSM_LS SG_ 2152095744 DPMCA_DispPrfMd6Avl 1;
BA_REL_ "GenSigSuprvResp" BU_SG_REL_ RadioHead_LS SG_ 2152095744 DPMCA_DispPrfMd6Avl 1;
BA_REL_ "GenSigSuprvResp" BU_SG_REL_ RadioHead_LS SG_ 2152095744 DPMCA_DispPrfMd6Avl 1;
BA_REL_ "GenSigSuprvResp" BU_SG_REL_ CSM_LS SG_ 2152095744 DPMCA_DispPrfMd5Avl 1;
BA_REL_ "GenSigSuprvResp" BU_SG_REL_ CSM_LS SG_ 2152095744 DPMCA_DispPrfMd5Avl 1;
BA_REL_ "GenSigSuprvResp" BU_SG_REL_ RadioHead_LS SG_ 2152095744 DPMCA_DispPrfMd5Avl 1;
BA_REL_ "GenSigSuprvResp" BU_SG_REL_ RadioHead_LS SG_ 2152095744 DPMCA_DispPrfMd5Avl 1;
BA_REL_ "GenSigSuprvResp" BU_SG_REL_ CSM_LS SG_ 2152095744 DPMCA_DispPrfMd4Avl 1;
BA_REL_ "GenSigSuprvResp" BU_SG_REL_ CSM_LS SG_ 2152095744 DPMCA_DispPrfMd4Avl 1;
BA_REL_ "GenSigSuprvResp" BU_SG_REL_ RadioHead_LS SG_ 2152095744 DPMCA_DispPrfMd4Avl 1;
BA_REL_ "GenSigSuprvResp" BU_SG_REL_ RadioHead_LS SG_ 2152095744 DPMCA_DispPrfMd4Avl 1;
BA_REL_ "GenSigSuprvResp" BU_SG_REL_ CSM_LS SG_ 2152095744 DPMCA_DispPrfMd3Avl 1;
BA_REL_ "GenSigSuprvResp" BU_SG_REL_ CSM_LS SG_ 2152095744 DPMCA_DispPrfMd3Avl 1;
BA_REL_ "GenSigSuprvResp" BU_SG_REL_ RadioHead_LS SG_ 2152095744 DPMCA_DispPrfMd3Avl 1;
BA_REL_ "GenSigSuprvResp" BU_SG_REL_ RadioHead_LS SG_ 2152095744 DPMCA_DispPrfMd3Avl 1;
BA_REL_ "GenSigSuprvResp" BU_SG_REL_ CSM_LS SG_ 2152095744 DPMCA_DispPrfMd2Avl 1;
BA_REL_ "GenSigSuprvResp" BU_SG_REL_ CSM_LS SG_ 2152095744 DPMCA_DispPrfMd2Avl 1;
BA_REL_ "GenSigSuprvResp" BU_SG_REL_ RadioHead_LS SG_ 2152095744 DPMCA_DispPrfMd2Avl 1;
BA_REL_ "GenSigSuprvResp" BU_SG_REL_ RadioHead_LS SG_ 2152095744 DPMCA_DispPrfMd2Avl 1;
BA_REL_ "GenSigSuprvResp" BU_SG_REL_ CSM_LS SG_ 2152095744 DPMCA_DispPrfMd1Avl 1;
BA_REL_ "GenSigSuprvResp" BU_SG_REL_ CSM_LS SG_ 2152095744 DPMCA_DispPrfMd1Avl 1;
BA_REL_ "GenSigSuprvResp" BU_SG_REL_ RadioHead_LS SG_ 2152095744 DPMCA_DispPrfMd1Avl 1;
BA_REL_ "GenSigSuprvResp" BU_SG_REL_ RadioHead_LS SG_ 2152095744 DPMCA_DispPrfMd1Avl 1;
BA_REL_ "GenSigSuprvResp" BU_SG_REL_ CSM_LS SG_ 2152095744 DPMCA_DrvlPrfMd6Avl 1;
BA_REL_ "GenSigSuprvResp" BU_SG_REL_ CSM_LS SG_ 2152095744 DPMCA_DrvlPrfMd6Avl 1;
BA_REL_ "GenSigSuprvResp" BU_SG_REL_ RadioHead_LS SG_ 2152095744 DPMCA_DrvlPrfMd6Avl 1;
BA_REL_ "GenSigSuprvResp" BU_SG_REL_ RadioHead_LS SG_ 2152095744 DPMCA_DrvlPrfMd6Avl 1;
BA_REL_ "GenSigSuprvResp" BU_SG_REL_ CSM_LS SG_ 2152095744 DPMCA_DrvlPrfMd5Avl 1;
BA_REL_ "GenSigSuprvResp" BU_SG_REL_ CSM_LS SG_ 2152095744 DPMCA_DrvlPrfMd5Avl 1;
BA_REL_ "GenSigSuprvResp" BU_SG_REL_ RadioHead_LS SG_ 2152095744 DPMCA_DrvlPrfMd5Avl 1;
BA_REL_ "GenSigSuprvResp" BU_SG_REL_ RadioHead_LS SG_ 2152095744 DPMCA_DrvlPrfMd5Avl 1;
BA_REL_ "GenSigSuprvResp" BU_SG_REL_ CSM_LS SG_ 2152095744 DPMCA_DrvlPrfMd4Avl 1;
BA_REL_ "GenSigSuprvResp" BU_SG_REL_ CSM_LS SG_ 2152095744 DPMCA_DrvlPrfMd4Avl 1;
BA_REL_ "GenSigSuprvResp" BU_SG_REL_ RadioHead_LS SG_ 2152095744 DPMCA_DrvlPrfMd4Avl 1;
BA_REL_ "GenSigSuprvResp" BU_SG_REL_ RadioHead_LS SG_ 2152095744 DPMCA_DrvlPrfMd4Avl 1;
BA_REL_ "GenSigSuprvResp" BU_SG_REL_ CSM_LS SG_ 2152095744 DPMCA_DrvlPrfMd3Avl 1;
BA_REL_ "GenSigSuprvResp" BU_SG_REL_ CSM_LS SG_ 2152095744 DPMCA_DrvlPrfMd3Avl 1;
BA_REL_ "GenSigSuprvResp" BU_SG_REL_ RadioHead_LS SG_ 2152095744 DPMCA_DrvlPrfMd3Avl 1;
BA_REL_ "GenSigSuprvResp" BU_SG_REL_ RadioHead_LS SG_ 2152095744 DPMCA_DrvlPrfMd3Avl 1;
BA_REL_ "GenSigSuprvResp" BU_SG_REL_ CSM_LS SG_ 2152095744 DPMCA_DrvlPrfMd2Avl 1;
BA_REL_ "GenSigSuprvResp" BU_SG_REL_ CSM_LS SG_ 2152095744 DPMCA_DrvlPrfMd2Avl 1;
BA_REL_ "GenSigSuprvResp" BU_SG_REL_ RadioHead_LS SG_ 2152095744 DPMCA_DrvlPrfMd2Avl 1;
BA_REL_ "GenSigSuprvResp" BU_SG_REL_ RadioHead_LS SG_ 2152095744 DPMCA_DrvlPrfMd2Avl 1;
BA_REL_ "GenSigSuprvResp" BU_SG_REL_ CSM_LS SG_ 2152095744 DPMCA_DrvlPrfMd1Avl 1;
BA_REL_ "GenSigSuprvResp" BU_SG_REL_ CSM_LS SG_ 2152095744 DPMCA_DrvlPrfMd1Avl 1;
BA_REL_ "GenSigSuprvResp" BU_SG_REL_ RadioHead_LS SG_ 2152095744 DPMCA_DrvlPrfMd1Avl 1;
BA_REL_ "GenSigSuprvResp" BU_SG_REL_ RadioHead_LS SG_ 2152095744 DPMCA_DrvlPrfMd1Avl 1;
BA_REL_ "GenSigSuprvResp" BU_SG_REL_ EOCM2A_K1_LS SG_ 2156945408 WiFiSSIDDgts1to8_Mp 1;
BA_REL_ "GenSigSuprvResp" BU_SG_REL_ EOCM2B_K1_LS SG_ 2156945408 WiFiSSIDDgts1to8_Mp 1;
BA_REL_ "GenSigSuprvResp" BU_SG_REL_ TCP_LS SG_ 2152611840 OBTCReqstrID 1;
BA_REL_ "GenSigSuprvResp" BU_SG_REL_ TCP_LS SG_ 2152611840 OBTCReqstrStat 1;
BA_REL_ "GenSigSuprvResp" BU_SG_REL_ IPC_LS SG_ 2153308160 RdHVltBatPckVlt 1;
BA_REL_ "GenSigSuprvResp" BU_SG_REL_ CSM_LS SG_ 2153308160 RdHVltBatPckVlt 1;
BA_REL_ "GenSigSuprvResp" BU_SG_REL_ RadioHead_LS SG_ 2153308160 RdHVltBatPckVlt 1;
BA_REL_ "GenSigSuprvResp" BU_SG_REL_ IPC_LS SG_ 2153308160 RdHVltBatPckCrnt 1;
BA_REL_ "GenSigSuprvResp" BU_SG_REL_ CSM_LS SG_ 2153308160 RdHVltBatPckCrnt 1;
BA_REL_ "GenSigSuprvResp" BU_SG_REL_ RadioHead_LS SG_ 2153308160 RdHVltBatPckCrnt 1;
BA_REL_ "GenSigSuprvResp" BU_SG_REL_ MSM_P_LS SG_ 2155970560 ClmCntLdShdLvlRq 1;
BA_REL_ "GenSigSuprvResp" BU_SG_REL_ HVSM_F_LS SG_ 2155970560 ClmCntLdShdLvlRq 1;
BA_REL_ "GenSigSuprvResp" BU_SG_REL_ MSM_LS SG_ 2155970560 ClmCntLdShdLvlRq 1;
BA_REL_ "GenSigSuprvResp" BU_SG_REL_ IPC_LS SG_ 2155970560 ClmCntBatSaverIO 1;
BA_REL_ "GenSigSuprvResp" BU_SG_REL_ VPM_LS SG_ 2151178240 TrlrMirVGlnCustSetReq 1;
BA_REL_ "GenSigSuprvResp" BU_SG_REL_ VPM_LS SG_ 2151178240 TrlrMirVEnCustSetReq 1;
BA_REL_ "GenSigSuprvResp" BU_SG_REL_ VPM_LS SG_ 2151178240 JacknfDetCustSetReq 1;
BA_REL_ "GenSigSuprvResp" BU_SG_REL_ VPM_LS SG_ 2151178240 CrgBdVwLtCustSetReq 1;
BA_REL_ "GenSigSuprvResp" BU_SG_REL_ EOCM2B_K2_LS SG_ 2151178240 AFLGPSCstStReq 1;
BA_REL_ "GenSigSuprvResp" BU_SG_REL_ EOCM2A_K2_LS SG_ 2151178240 AFLGPSCstStReq 1;
BA_REL_ "GenSigSuprvResp" BU_SG_REL_ VIS2_LS SG_ 2151178240 AFLGPSCstStReq 1;
BA_REL_ "GenSigSuprvResp" BU_SG_REL_ FCM_LS SG_ 2151178240 AFLGPSCstStReq 1;
BA_REL_ "GenSigSuprvResp" BU_SG_REL_ HBSM_LS SG_ 2151178240 AFLGPSCstStReq 1;
BA_REL_ "GenSigSuprvResp" BU_SG_REL_ BCM_LS SG_ 2151178240 AFLGPSCstStReq 1;
BA_REL_ "GenSigSuprvResp" BU_SG_REL_ BCM_LS SG_ 2151178240 AFLGPSCstStReq 1;
BA_REL_ "GenSigSuprvResp" BU_SG_REL_ EOCM2B_K2_LS SG_ 2151178240 AFLCstStReq 1;
BA_REL_ "GenSigSuprvResp" BU_SG_REL_ EOCM2A_K2_LS SG_ 2151178240 AFLCstStReq 1;
BA_REL_ "GenSigSuprvResp" BU_SG_REL_ VIS2_LS SG_ 2151178240 AFLCstStReq 1;
BA_REL_ "GenSigSuprvResp" BU_SG_REL_ FCM_LS SG_ 2151178240 AFLCstStReq 1;
BA_REL_ "GenSigSuprvResp" BU_SG_REL_ HBSM_LS SG_ 2151178240 AFLCstStReq 1;
BA_REL_ "GenSigSuprvResp" BU_SG_REL_ BCM_LS SG_ 2151178240 AFLCstStReq 1;
BA_REL_ "GenSigSuprvResp" BU_SG_REL_ BCM_LS SG_ 2151178240 AFLCstStReq 1;
BA_REL_ "GenSigSuprvResp" BU_SG_REL_ EOCM2B_K2_LS SG_ 2151178240 AdpHgBmAsSnCsStRq 1;
BA_REL_ "GenSigSuprvResp" BU_SG_REL_ EOCM2A_K2_LS SG_ 2151178240 AdpHgBmAsSnCsStRq 1;
BA_REL_ "GenSigSuprvResp" BU_SG_REL_ VIS2_LS SG_ 2151178240 AdpHgBmAsSnCsStRq 1;
BA_REL_ "GenSigSuprvResp" BU_SG_REL_ FCM_LS SG_ 2151178240 AdpHgBmAsSnCsStRq 1;
BA_REL_ "GenSigSuprvResp" BU_SG_REL_ HBSM_LS SG_ 2151178240 AdpHgBmAsSnCsStRq 1;
BA_REL_ "GenSigSuprvResp" BU_SG_REL_ BCM_LS SG_ 2151178240 AdpHgBmAsSnCsStRq 1;
BA_REL_ "GenSigSuprvResp" BU_SG_REL_ BCM_LS SG_ 2151178240 AdpHgBmAsSnCsStRq 1;
BA_REL_ "GenSigSuprvResp" BU_SG_REL_ EOCM2B_K2_LS SG_ 2151178240 AdpHgBmAstCstStRq 1;
BA_REL_ "GenSigSuprvResp" BU_SG_REL_ EOCM2A_K2_LS SG_ 2151178240 AdpHgBmAstCstStRq 1;
BA_REL_ "GenSigSuprvResp" BU_SG_REL_ VIS2_LS SG_ 2151178240 AdpHgBmAstCstStRq 1;
BA_REL_ "GenSigSuprvResp" BU_SG_REL_ FCM_LS SG_ 2151178240 AdpHgBmAstCstStRq 1;
BA_REL_ "GenSigSuprvResp" BU_SG_REL_ HBSM_LS SG_ 2151178240 AdpHgBmAstCstStRq 1;
BA_REL_ "GenSigSuprvResp" BU_SG_REL_ BCM_LS SG_ 2151178240 AdpHgBmAstCstStRq 1;
BA_REL_ "GenSigSuprvResp" BU_SG_REL_ BCM_LS SG_ 2151178240 AdpHgBmAstCstStRq 1;
BA_REL_ "GenSigSuprvResp" BU_SG_REL_ EOCM2B_K2_LS SG_ 2151178240 AutHgBmAsSnCsStRq 1;
BA_REL_ "GenSigSuprvResp" BU_SG_REL_ EOCM2A_K2_LS SG_ 2151178240 AutHgBmAsSnCsStRq 1;
BA_REL_ "GenSigSuprvResp" BU_SG_REL_ VIS2_LS SG_ 2151178240 AutHgBmAsSnCsStRq 1;
BA_REL_ "GenSigSuprvResp" BU_SG_REL_ EOCM_F_LS SG_ 2151178240 AutHgBmAsSnCsStRq 1;
BA_REL_ "GenSigSuprvResp" BU_SG_REL_ FCM_LS SG_ 2151178240 AutHgBmAsSnCsStRq 1;
BA_REL_ "GenSigSuprvResp" BU_SG_REL_ HBSM_LS SG_ 2151178240 AutHgBmAsSnCsStRq 1;
BA_REL_ "GenSigSuprvResp" BU_SG_REL_ BCM_LS SG_ 2151178240 AutHgBmAsSnCsStRq 1;
BA_REL_ "GenSigSuprvResp" BU_SG_REL_ EOCM2B_K2_LS SG_ 2151178240 AutHgBmAstCstStRq 1;
BA_REL_ "GenSigSuprvResp" BU_SG_REL_ EOCM2A_K2_LS SG_ 2151178240 AutHgBmAstCstStRq 1;
BA_REL_ "GenSigSuprvResp" BU_SG_REL_ VIS2_LS SG_ 2151178240 AutHgBmAstCstStRq 1;
BA_REL_ "GenSigSuprvResp" BU_SG_REL_ EOCM_F_LS SG_ 2151178240 AutHgBmAstCstStRq 1;
BA_REL_ "GenSigSuprvResp" BU_SG_REL_ FCM_LS SG_ 2151178240 AutHgBmAstCstStRq 1;
BA_REL_ "GenSigSuprvResp" BU_SG_REL_ HBSM_LS SG_ 2151178240 AutHgBmAstCstStRq 1;
BA_REL_ "GenSigSuprvResp" BU_SG_REL_ BCM_LS SG_ 2151178240 AutHgBmAstCstStRq 1;
BA_REL_ "GenSigSuprvResp" BU_SG_REL_ CSM_LS SG_ 2154790912 AdpHgBmAsSnCsCrStVal 1;
BA_REL_ "GenSigSuprvResp" BU_SG_REL_ RadioHead_LS SG_ 2154790912 AdpHgBmAsSnCsCrStVal 1;
BA_REL_ "GenSigSuprvResp" BU_SG_REL_ CSM_LS SG_ 2154790912 AdpHgBmAsSnCsStAvl 1;
BA_REL_ "GenSigSuprvResp" BU_SG_REL_ RadioHead_LS SG_ 2154790912 AdpHgBmAsSnCsStAvl 1;
BA_REL_ "GenSigSuprvResp" BU_SG_REL_ CSM_LS SG_ 2154790912 AdpHgBmAsCsCrStVal 1;
BA_REL_ "GenSigSuprvResp" BU_SG_REL_ RadioHead_LS SG_ 2154790912 AdpHgBmAsCsCrStVal 1;
BA_REL_ "GenSigSuprvResp" BU_SG_REL_ CSM_LS SG_ 2154790912 AdpHgBmAsCsStAvl 1;
BA_REL_ "GenSigSuprvResp" BU_SG_REL_ RadioHead_LS SG_ 2154790912 AdpHgBmAsCsStAvl 1;
BA_REL_ "GenSigSuprvResp" BU_SG_REL_ CSM_LS SG_ 2154790912 AutHgBmAsCsCrStVal 1;
BA_REL_ "GenSigSuprvResp" BU_SG_REL_ RadioHead_LS SG_ 2154790912 AutHgBmAsCsCrStVal 1;
BA_REL_ "GenSigSuprvResp" BU_SG_REL_ CSM_LS SG_ 2154790912 AutHgBmAsSnCsStAvl 1;
BA_REL_ "GenSigSuprvResp" BU_SG_REL_ RadioHead_LS SG_ 2154790912 AutHgBmAsSnCsStAvl 1;
BA_REL_ "GenSigSuprvResp" BU_SG_REL_ CSM_LS SG_ 2154790912 AutHgBmAsSnCsCrStVa 1;
BA_REL_ "GenSigSuprvResp" BU_SG_REL_ RadioHead_LS SG_ 2154790912 AutHgBmAsSnCsCrStVa 1;
BA_REL_ "GenSigSuprvResp" BU_SG_REL_ CSM_LS SG_ 2154790912 AutHgBmAsCsStAvl 1;
BA_REL_ "GenSigSuprvResp" BU_SG_REL_ RadioHead_LS SG_ 2154790912 AutHgBmAsCsStAvl 1;
VAL_ 2152775680 CrgBdVwLtCustSetVal 3 "Unused and Reserved" 2 "On" 1 "Off" 0 "Unknown" ;
VAL_ 2152775680 CrgBdVwLtCustSetAvl 1 "true" 0 "false" ;
VAL_ 2152775680 TrlrMirVGlnCustSetVal 3 "Unused and Reserved" 2 "On" 1 "Off" 0 "Unknown" ;
VAL_ 2152775680 TrlrMirVGlnCustSetAvl 1 "true" 0 "false" ;
VAL_ 2152775680 TrlrMirVEnCustSetVal 3 "Unused and Reserved" 2 "On" 1 "Off" 0 "Unknown" ;
VAL_ 2152775680 TrlrMirVEnCustSetAvl 1 "true" 0 "false" ;
VAL_ 2152775680 TrlrArtcltnAnglCalStat 3 "Unavailable" 2 "Degraded" 1 "Available" 0 "Unknown" ;
VAL_ 2152775680 InvTrlrAx1CamRollAlgnd 1 "true" 0 "false" ;
VAL_ 2152775680 InvTrlrAx1CamPtchAlgnd 1 "true" 0 "false" ;
VAL_ 2152775680 InvTrlrAx1CamYAlgnd 1 "true" 0 "false" ;
VAL_ 2152775680 InvTrlrAx1CamXAlgnd 1 "true" 0 "false" ;
VAL_ 2152775680 RPDCA_Resrv3Avail 1 "true" 0 "false" ;
VAL_ 2152775680 RPDCA_Resrv2Avail 1 "true" 0 "false" ;
VAL_ 2152775680 RPDCA_Resrv1Avail 1 "true" 0 "false" ;
VAL_ 2152775680 RPDCA_AlrtBrkAvail 1 "true" 0 "false" ;
VAL_ 2152775680 RPDCA_AlrtAvail 1 "true" 0 "false" ;
VAL_ 2152775680 RPDCA_OnAvail 1 "true" 0 "false" ;
VAL_ 2152775680 RPDCA_OfAvail 1 "true" 0 "false" ;
VAL_ 2152775680 JacknfDetCustSetVal 3 "Unused and Reserved" 2 "On" 1 "Off" 0 "Unknown" ;
VAL_ 2152775680 JacknfDetCustSetAvl 1 "true" 0 "false" ;
VAL_ 2152775680 DispTrgdVidOn 1 "true" 0 "false" ;
VAL_ 2152775680 a_360DegVidFetrPrsnt 1 "true" 0 "false" ;
VAL_ 2152775680 TrgdVidRecFetrPrsnt 1 "true" 0 "false" ;
VAL_ 2152775680 RrPedDetCstStVal 7 "Reserved3" 6 "Reserved2" 5 "Reserved1" 4 "Alert and Brake" 3 "Alert" 2 "On" 1 "Off" 0 "No Action" ;
VAL_ 2152775680 RrPedDetCstStAvl 1 "true" 0 "false" ;
VAL_ 2152775680 PudlLmpReqstd 1 "true" 0 "false" ;
VAL_ 2152775680 SurdVwLightgCsCurrSetVal 7 "Unused and Reserved 5" 6 "Unused and Reserved 4" 5 "Unused and Reserved 3" 4 "Unused and Reserved 2" 3 "Unused and Reserved 1" 2 "ON" 1 "OFF" 0 "No Action" ;
VAL_ 2152775680 DispSmrtTwVidOn 1 "true" 0 "false" ;
VAL_ 2152775680 DispFrt360CamOn 1 "true" 0 "false" ;
VAL_ 2152775680 SurdVwLightgCsSetAvail 1 "true" 0 "false" ;
VAL_ 2153857024 TDRCADD_WOTEvnts 1 "true" 0 "false" ;
VAL_ 2153857024 TDRCADD_LDWEvnts 1 "true" 0 "false" ;
VAL_ 2153857024 TDRCADD_FCMBrEvts 1 "true" 0 "false" ;
VAL_ 2153857024 TDRCADD_DrwDrvAlrt 1 "true" 0 "false" ;
VAL_ 2153857024 TDRCADD_RCMBrEvts 1 "true" 0 "false" ;
VAL_ 2153857024 TDRCADD_FCImntAlrts 1 "true" 0 "false" ;
VAL_ 2153857024 TDRCADD_FCHdwyAlrt 1 "true" 0 "false" ;
VAL_ 2153857024 TDRCADD_StCtrlEvnts 1 "true" 0 "false" ;
VAL_ 2153857024 TDRCADD_ABSAtvEvt 1 "true" 0 "false" ;
VAL_ 2153857024 TDRCADD_TrCtrlEvnts 1 "true" 0 "false" ;
VAL_ 2153857024 TDRCADD_OvSpdEvnt 1 "true" 0 "false" ;
VAL_ 2153857024 TDRCADD_DistDrvn 1 "true" 0 "false" ;
VAL_ 2153857024 TDRCADD_MaxSpd 1 "true" 0 "false" ;
VAL_ 2153865216 TnDrvStBltShftIntrlkCsStRq 2 "On" 1 "Off" 0 "No Action" ;
VAL_ 2153865216 StBltShftIntrlkCsStRq 2 "On" 1 "Off" 0 "No Action" ;
VAL_ 2153865216 TeenDrvReq 0 "No Action" 1 "Verify Teen PIN" 2 "Update Teen PIN" 3 "Set Teen Key" 4 "Clear Teen Key" 5 "Check for Teen Key" 6 "Clear Teen Keys and PIN" 7 "Reset Report Card" 8 "Request Report Card Data" ;
VAL_ 2153865216 TnDrvSpdLmtCstStReq 0 "No Action" 1 "Off" 2 "On" ;
VAL_ 2153865216 TDOWCSR_StatReq 0 "No Action" 1 "Off" 2 "On" ;
VAL_ 2153865216 TDOWCSR_IncSwAct 1 "true" 0 "false" ;
VAL_ 2153865216 TDOWCSR_DecSwAct 1 "true" 0 "false" ;
VAL_ 2153840640 TnDrvDRLOffUnbIO 1 "true" 0 "false" ;
VAL_ 2153840640 TnDrvALCOffUnbIO 1 "true" 0 "false" ;
VAL_ 2153824256 TeenDrvAccelLimIO 1 "true" 0 "false" ;
VAL_ 2153824256 TeenDrvAct 1 "true" 0 "false" ;
VAL_ 2153824256 TeenDrvRsp 0 "No Action" 1 "Teen PIN Verified" 2 "Teen PIN Updated" 3 "Teen PIN Mismatch" 4 "Teen Key Set Complete" 5 "Teen Key Clear Complete" 6 "Key Not Present" 7 "Key Detected as Teen Key" 8 "Key Detected as NOT Teen Key" ;
VAL_ 2153824256 TeenDrvFtrAvl 1 "true" 0 "false" ;
VAL_ 2153824256 TeenDrvPINStrd 1 "true" 0 "false" ;
VAL_ 2153824256 TnDrvGapAdjUnbIO 1 "true" 0 "false" ;
VAL_ 2153824256 TnDrvOvrSpdIO 1 "true" 0 "false" ;
VAL_ 2153824256 TDOvSpdWrnCstStAvl 1 "true" 0 "false" ;
VAL_ 2153824256 TDOWCCSV_CrStat 0 "No Action" 1 "Off" 2 "On" ;
VAL_ 2153824256 TnDrvSpdLmtCstStAvl 1 "true" 0 "false" ;
VAL_ 2153824256 TDSLCCSV_SpLmtStat 0 "No Action" 1 "Off" 2 "On" ;
VAL_ 2155151360 PSMP_UnsdRsrvd 1 "true" 0 "false" ;
VAL_ 2155134976 PsngrSetRrwdMvmnt 7 "Supervised Seat Recline Rearward" 6 "Supervised Seat Rear Down" 5 "Supervised Seat Rearward" 4 "Button Memory 1 and 2 EXIT Recall" 3 "Supervised Memory Recall" 2 "Auto Easy Exit Recall" 1 "Auto Recall At Ignition On" 0 "No Auto Or Rearward Movement" ;
VAL_ 2155134976 PSCDS_DispReq 1 "true" 0 "false" ;
VAL_ 2155134976 PSCDS_DispSz 3 "Reserved" 2 "Small Size" 1 "Medium Size" 0 "Full Size" ;
VAL_ 2155134976 PSCDS_CshLgAdjFdRr 3 "Rearward" 2 "Forward" 1 "Selected - No Movement" 0 "Not Selected" ;
VAL_ 2155134976 PSCDS_BkCshBlstInOt 5 "Cushion Bolster Out" 4 "Cushion Bolster In" 3 "Back Bolster Out" 2 "Back Bolster In" 1 "Selected - No Movement" 0 "Not Selected" ;
VAL_ 2155134976 PSCDS_CshBlstrInOut 3 "Out" 2 "In" 1 "Selected - No Movement" 0 "Not Selected" ;
VAL_ 2155134976 PSCDS_BkBlstrInOut 3 "Out" 2 "In" 1 "Selected - No Movement" 0 "Not Selected" ;
VAL_ 2155134976 PSCDS_LmbrUDnFdRr 5 "Rearward" 4 "Forward" 3 "Down" 2 "Up" 1 "Selected - No Movement" 0 "Not Selected" ;
VAL_ 2155134976 PSCDS_LmbrFwdRr 3 "Rearward" 2 "Forward" 1 "Selected - No Movement" 0 "Not Selected" ;
VAL_ 2155134976 PSCDS_LmbrUpDwn 3 "Down" 2 "Up" 1 "Selected - No Movement" 0 "Not Selected" ;
VAL_ 2155134976 PSCDS_UprShldrFdRr 3 "Rearward" 2 "Forward" 1 "Selected - No Movement" 0 "Not Selected" ;
VAL_ 2155134976 PSCDS_HdrstTltFwdRr 3 "Rearward" 2 "Forward" 1 "Selected - No Movement" 0 "Not Selected" ;
VAL_ 2155134976 PSCDS_HdrstWngInOt 3 "Out" 2 "In" 1 "Selected - No Movement" 0 "Not Selected" ;
VAL_ 2155134976 PSCDS_HdrstUDnFdRr 5 "Rearward" 4 "Forward" 3 "Down" 2 "Up" 1 "Selected - No Movement" 0 "Not Selected" ;
VAL_ 2155134976 PSCDS_HdrstFwdRrwd 3 "Rearward" 2 "Forward" 1 "Selected - No Movement" 0 "Not Selected" ;
VAL_ 2155134976 PSCDS_HdrstUpDn 3 "Down" 2 "Up" 1 "Selected - No Movement" 0 "Not Selected" ;
VAL_ 2155134976 PSCDS_MassgIntsty 7 "Massage Intensity 7" 6 "Massage Intensity 6" 5 "Massage Intensity 5" 4 "Massage Intensity 4" 3 "Massage Intensity 3" 2 "Massage Intensity 2" 1 "Massage Intensity 1" 0 "Massage Off" ;
VAL_ 2155134976 PSCDS_MassgTyp 15 "Massage Type 15" 14 "Massage Type 14" 13 "Massage Type 13" 12 "Massage Type 12" 11 "Massage Type 11" 10 "Massage Type 10" 9 "Massage Type 9" 8 "Massage Type 8" 7 "Massage Type 7" 6 "Massage Type 6" 5 "Massage Type 5" 4 "Massage Type 4" 3 "Massage Type 3" 2 "Massage Type 2" 1 "Massage Type 1" 0 "Massage Off" ;
VAL_ 2155134976 PSCDS_Massg 2 "Selected Massage On" 1 "Selected Massage Off" 0 "Not Selected" ;
VAL_ 2155102208 DSMP_UnsdRsrvd 1 "true" 0 "false" ;
VAL_ 2155085824 CPMAPINFO4 1 "Hardware Or Software Error" 0 "No Hardware Or Software Error" ;
VAL_ 2155085824 StrgColCommsFlt 2 "Disabled Communications DTC" 1 "No Communications Fault" 0 "Communications Fault" ;
VAL_ 2155085824 DSCDS_DispReq 1 "true" 0 "false" ;
VAL_ 2155085824 DSCDS_DispSz 3 "Reserved" 2 "Small Size" 1 "Medium Size" 0 "Full Size" ;
VAL_ 2155085824 DSCDS_CshLgAdjFdRr 3 "Rearward" 2 "Forward" 1 "Selected - No Movement" 0 "Not Selected" ;
VAL_ 2155085824 DSCDS_BkCshBlstInOt 5 "Cushion Bolster Out" 4 "Cushion Bolster In" 3 "Back Bolster Out" 2 "Back Bolster In" 1 "Selected - No Movement" 0 "Not Selected" ;
VAL_ 2155085824 DSCDS_CshBlstrInOut 3 "Out" 2 "In" 1 "Selected - No Movement" 0 "Not Selected" ;
VAL_ 2155085824 DSCDS_BkBlstrInOut 3 "Out" 2 "In" 1 "Selected - No Movement" 0 "Not Selected" ;
VAL_ 2155085824 DSCDS_LmbrUDnFdRr 5 "Rearward" 4 "Forward" 3 "Down" 2 "Up" 1 "Selected - No Movement" 0 "Not Selected" ;
VAL_ 2155085824 DSCDS_LmbrFwdRr 3 "Rearward" 2 "Forward" 1 "Selected - No Movement" 0 "Not Selected" ;
VAL_ 2155085824 DSCDS_LmbrUpDwn 3 "Down" 2 "Up" 1 "Selected - No Movement" 0 "Not Selected" ;
VAL_ 2155085824 DSCDS_UprShldrFdRr 3 "Rearward" 2 "Forward" 1 "Selected - No Movement" 0 "Not Selected" ;
VAL_ 2155085824 DSCDS_HdrstTltFwdRr 3 "Rearward" 2 "Forward" 1 "Selected - No Movement" 0 "Not Selected" ;
VAL_ 2155085824 DSCDS_HdrstWngInOt 3 "Out" 2 "In" 1 "Selected - No Movement" 0 "Not Selected" ;
VAL_ 2155085824 DSCDS_HdrstUDnFdRr 5 "Rearward" 4 "Forward" 3 "Down" 2 "Up" 1 "Selected - No Movement" 0 "Not Selected" ;
VAL_ 2155085824 DSCDS_HdrstFwdRrwd 3 "Rearward" 2 "Forward" 1 "Selected - No Movement" 0 "Not Selected" ;
VAL_ 2155085824 DSCDS_HdrstUpDn 3 "Down" 2 "Up" 1 "Selected - No Movement" 0 "Not Selected" ;
VAL_ 2155085824 DSCDS_MassgIntsty 7 "Massage Intensity 7" 6 "Massage Intensity 6" 5 "Massage Intensity 5" 4 "Massage Intensity 4" 3 "Massage Intensity 3" 2 "Massage Intensity 2" 1 "Massage Intensity 1" 0 "Massage Off" ;
VAL_ 2155085824 DSCDS_MassgTyp 15 "Massage Type 15" 14 "Massage Type 14" 13 "Massage Type 13" 12 "Massage Type 12" 11 "Massage Type 11" 10 "Massage Type 10" 9 "Massage Type 9" 8 "Massage Type 8" 7 "Massage Type 7" 6 "Massage Type 6" 5 "Massage Type 5" 4 "Massage Type 4" 3 "Massage Type 3" 2 "Massage Type 2" 1 "Massage Type 1" 0 "Massage Off" ;
VAL_ 2155085824 DSCDS_Massg 2 "Selected Massage On" 1 "Selected Massage Off" 0 "Not Selected" ;
VAL_ 2153791488 ArtcldRngBrdSt 5 "Running Boards Inhibited" 4 "Running Boards Cargo Access" 0 "No Action" 1 "Resume Normal Operation" 2 "Running Boards Deployed" 3 "Running Boards Stowed" ;
VAL_ 2149883904 BTPR_RspInfoAvail 1 "true" 0 "false" ;
VAL_ 2149883904 BTPR_RspStat 0 "No Action" 1 "Available" 2 "Bluetooth Address" 3 "Pairing PIN" 4 "Unused and Reserved" 5 "Delete Pairing Information" 6 "Enter Bluetooth Pairing Mode" ;
VAL_ 2150252544 ECHG_YAxisMaxVal 0 "6" 1 "12" 2 "16" 3 "20" 4 "32" 5 "40" 6 "48" 7 "60" ;
VAL_ 2150252544 ECHG_XAxisTkMrkIntvl 0 "0.5" 1 "1" 2 "5" 3 "10" 4 "20" 5 "50" 6 "80" 7 "100" ;
VAL_ 2150252544 ECHG_MeasUnit 0 "km/kWh" 1 "mi/kWh" 2 "kWh/100km" 3 "km/L" 4 "mi/gal" 5 "L/100km" 6 "mi/kg" 7 "kg/100km" ;
VAL_ 2155913216 PFAS_SrvPedAlrtIO 1 "true" 0 "false" ;
VAL_ 2155913216 PFAS_PFASysStat 0 "Disable" 1 "Active" 2 "Fault" 3 "Unused and Reserved" ;
VAL_ 2155913216 PFAS_PFASndGenEn 1 "true" 0 "false" ;
VAL_ 2155913216 PFAS_PFARevSnd 0 "No Action" 1 "Sound #1" 2 "Sound #2" 3 "Sound #3" ;
VAL_ 2155913216 PFAS_PFAFwdSnd 0 "No Action" 1 "Sound #1" 2 "Sound #2" 3 "Sound #3" ;
VAL_ 2155913216 PedFrndlyAlrtCsSetAvl 1 "true" 0 "false" ;
VAL_ 2155913216 PedFrndlyAlrtCsCrStVal 0 "No Value" 1 "Off" 2 "On" ;
VAL_ 2155913216 DslExhFluidLvlPrcntV 1 "Invalid" 0 "Valid" ;
VAL_ 2155913216 DslEmnsOBDMrkt 0 "North America" 1 "Europe" ;
VAL_ 2155913216 DslExhFldRmngDstHRsV 1 "Invalid" 0 "Valid" ;
VAL_ 2152095744 SPMCA_SusPrfMd6Avl 1 "true" 0 "false" ;
VAL_ 2152095744 SPMCA_SusPrfMd5Avl 1 "true" 0 "false" ;
VAL_ 2152095744 SPMCA_SusPrfMd4Avl 1 "true" 0 "false" ;
VAL_ 2152095744 SPMCA_SusPrfMd3Avl 1 "true" 0 "false" ;
VAL_ 2152095744 SPMCA_SusPrfMd2Avl 1 "true" 0 "false" ;
VAL_ 2152095744 SPMCA_SusPrfMd1Avl 1 "true" 0 "false" ;
VAL_ 2152095744 SPMCA_StrPrfMd6Avl 1 "true" 0 "false" ;
VAL_ 2152095744 SPMCA_StrPrfMd5Avl 1 "true" 0 "false" ;
VAL_ 2152095744 SPMCA_StrPrfMd4Avl 1 "true" 0 "false" ;
VAL_ 2152095744 SPMCA_StrPrfMd3Avl 1 "true" 0 "false" ;
VAL_ 2152095744 SPMCA_StrPrfMd2Avl 1 "true" 0 "false" ;
VAL_ 2152095744 SPMCA_StrPrfMd1Avl 1 "true" 0 "false" ;
VAL_ 2152095744 SPMCA_SndPrfMd6Avl 1 "true" 0 "false" ;
VAL_ 2152095744 SPMCA_SndPrfMd5Avl 1 "true" 0 "false" ;
VAL_ 2152095744 SPMCA_SndPrfMd4Avl 1 "true" 0 "false" ;
VAL_ 2152095744 SPMCA_SndPrfMd3Avl 1 "true" 0 "false" ;
VAL_ 2152095744 SPMCA_SndPrfMd2Avl 1 "true" 0 "false" ;
VAL_ 2152095744 SPMCA_SndPrfMd1Avl 1 "true" 0 "false" ;
VAL_ 2152095744 DPMCA_DispPrfMd6Avl 1 "true" 0 "false" ;
VAL_ 2152095744 DPMCA_DispPrfMd5Avl 1 "true" 0 "false" ;
VAL_ 2152095744 DPMCA_DispPrfMd4Avl 1 "true" 0 "false" ;
VAL_ 2152095744 DPMCA_DispPrfMd3Avl 1 "true" 0 "false" ;
VAL_ 2152095744 DPMCA_DispPrfMd2Avl 1 "true" 0 "false" ;
VAL_ 2152095744 DPMCA_DispPrfMd1Avl 1 "true" 0 "false" ;
VAL_ 2152095744 DPMCA_DrvlPrfMd6Avl 1 "true" 0 "false" ;
VAL_ 2152095744 DPMCA_DrvlPrfMd5Avl 1 "true" 0 "false" ;
VAL_ 2152095744 DPMCA_DrvlPrfMd4Avl 1 "true" 0 "false" ;
VAL_ 2152095744 DPMCA_DrvlPrfMd3Avl 1 "true" 0 "false" ;
VAL_ 2152095744 DPMCA_DrvlPrfMd2Avl 1 "true" 0 "false" ;
VAL_ 2152095744 DPMCA_DrvlPrfMd1Avl 1 "true" 0 "false" ;
VAL_ 2152611840 OBTCR_Actv 1 "true" 0 "false" ;
VAL_ 2152611840 OBTCReqstrStat 3 "Off Board Tester Present" 2 "Active" 1 "Inactive" 0 "Unknown" ;
VAL_ 2153308160 RdHVltBatPckVltV 1 "Invalid" 0 "Valid" ;
VAL_ 2153308160 RdHVltBatPckVltM 1 "Use Data" 0 "Don't Use Data" ;
VAL_ 2153308160 RdHVltBatPckCrntV 1 "Invalid" 0 "Valid" ;
VAL_ 2153308160 RdHVltBatPckCrntM 1 "Use Data" 0 "Don't Use Data" ;
VAL_ 2155970560 ClmCntLdShdLvlRq 0 "No Load Shedding" 1 "Load Shed Level 1" 2 "Load Shed Level 2" 3 "Load Shed Level 3" 4 "Load Shed Level 4" ;
VAL_ 2155970560 ClmCntBatSaverIO 1 "true" 0 "false" ;
VAL_ 2151178240 TrlrMirVGlnCustSetReq 3 "Unused and Reserved" 2 "On" 1 "Off" 0 "No Action" ;
VAL_ 2151178240 TrlrMirVEnCustSetReq 3 "Unused and Reserved" 2 "On" 1 "Off" 0 "No Action" ;
VAL_ 2151178240 JacknfDetCustSetReq 3 "Unused and Reserved" 2 "On" 1 "Off" 0 "No Action" ;
VAL_ 2151178240 CrgBdVwLtCustSetReq 3 "Unused and Reserved" 2 "On" 1 "Off" 0 "No Action" ;
VAL_ 2151178240 AFLGPSCstStReq 0 "No Action" 1 "Corner And Curve Lighting Only" 2 "Intelligent Light Distribution" 3 "GPS Assistance" 4 "Reserved1" 5 "Reserved2" 6 "Reserved3" 7 "Off" ;
VAL_ 2151178240 AFLCstStReq 0 "No Action" 1 "Corner And Curve Lighting Only" 2 "Intelligent Light Distribution" 3 "Reserved1" 4 "Reserved2" 5 "Reserved3" 6 "Reserved4" 7 "Off" ;
VAL_ 2151178240 LtRtHnTrCstStReq 0 "No Action" 1 "Left Hand Traffic" 2 "Right Hand Traffic" ;
VAL_ 2151178240 AdpHgBmAsSnCsStRq 0 "No Action" 1 "Off" 2 "Normal Sensitivity" 3 "Reduced Sensitivity" 4 "Reserved1" 5 "Reserved2" 6 "Reserved3" 7 "Reserved4" ;
VAL_ 2151178240 AdpHgBmAstCstStRq 0 "No Action" 1 "Off" 2 "On" 3 "Reserved1" 4 "Reserved2" 5 "Reserved3" 6 "Reserved4" 7 "Reserved5" ;
VAL_ 2151178240 LtRtHnTrGPSCstStRq 0 "No Action" 1 "Left Hand Traffic" 2 "Right Hand Traffic" 3 "Automatic" 4 "Reserved1" 5 "Reserved2" 6 "Reserved3" 7 "Reserved4" ;
VAL_ 2151178240 AutHgBmAsSnCsStRq 0 "No Action" 1 "Off" 2 "On Normal Sensitivity" 3 "On Reduced Sensitivity" 4 "Reserved1" 5 "Reserved2" 6 "Reserved3" 7 "Reserved4" ;
VAL_ 2151178240 AutHgBmAstCstStRq 0 "No Action" 1 "Off" 2 "On" 3 "Reserved1" 4 "Reserved2" 5 "Reserved3" 6 "Reserved4" 7 "Reserved5" ;
VAL_ 2154790912 AdpHgBmAsSnCsCrStVal 0 "No Value" 1 "Off" 2 "On Normal Sensitivity" 3 "On Reduced Sensitivity" 4 "Reserved1" 5 "Reserved2" 6 "Reserved3" 7 "Reserved4" ;
VAL_ 2154790912 AdpHgBmAsSnCsStAvl 1 "true" 0 "false" ;
VAL_ 2154790912 AdpHgBmAsCsCrStVal 0 "No Value" 1 "Off" 2 "On" 3 "Reserved1" 4 "Reserved2" 5 "Reserved3" 6 "Reserved4" 7 "Reserved5" ;
VAL_ 2154790912 AdpHgBmAsCsStAvl 1 "true" 0 "false" ;
VAL_ 2154790912 AutHgBmAsCsCrStVal 0 "No Value" 1 "Off" 2 "On" 3 "Reserved1" 4 "Reserved2" 5 "Reserved3" 6 "Reserved4" 7 "Reserved5" ;
VAL_ 2154790912 AutHgBmAsSnCsStAvl 1 "true" 0 "false" ;
VAL_ 2154790912 AutHgBmAsSnCsCrStVa 0 "No Value" 1 "Off" 2 "On Normal Sensitivity" 3 "On Reduced Sensitivity" 4 "Reserved1" 5 "Reserved2" 6 "Reserved3" 7 "Reserved4" ;
VAL_ 2154790912 AutHgBmAsCsStAvl 1 "true" 0 "false" ;
SIG_GROUP_ 2152775680 RrPedDetCstAvail 1 : RPDCA_Resrv3Avail RPDCA_Resrv2Avail RPDCA_Resrv1Avail RPDCA_AlrtBrkAvail RPDCA_AlrtAvail RPDCA_OnAvail RPDCA_OfAvail;
SIG_GROUP_ 2153857024 TnDrvRptCrdAvlDspDat 1 : TDRCADD_WOTEvnts TDRCADD_LDWEvnts TDRCADD_FCMBrEvts TDRCADD_DrwDrvAlrt TDRCADD_RCMBrEvts TDRCADD_FCImntAlrts TDRCADD_FCHdwyAlrt TDRCADD_StCtrlEvnts TDRCADD_ABSAtvEvt TDRCADD_TrCtrlEvnts TDRCADD_OvSpdEvnt TDRCADD_DistDrvn TDRCADD_MaxSpd;
SIG_GROUP_ 2153865216 TDOvSpdWrnCstStReq 1 : TDOWCSR_StatReq TDOWCSR_IncSwAct TDOWCSR_DecSwAct;
SIG_GROUP_ 2153824256 TDOvSpdWrnCstCrStVl 1 : TDOWCCSV_CrStVl TDOWCCSV_CrStat;
SIG_GROUP_ 2153824256 TnDrvSpdLmtCstCrStVl 1 : TDSLCCSV_SpLmtStat TDSLCCSV_SpLmDisVl;
SIG_GROUP_ 2155151360 PsngrStMassgPrty 1 : PSMP_UnsdRsrvd PSMP_MaxDispVal PSMP_Type15 PSMP_Type14 PSMP_Type13 PSMP_Type12 PSMP_Type11 PSMP_Type10 PSMP_Type9 PSMP_Type8 PSMP_Type7 PSMP_Type6 PSMP_Type5 PSMP_Type4 PSMP_Type3 PSMP_Type2 PSMP_Type1;
SIG_GROUP_ 2155134976 PsngrStCtlDispStat 1 : PSCDS_UnsdRsrvd PSCDS_DispReq PSCDS_DispSz PSCDS_CshLgAdjFdRr PSCDS_BkCshBlstInOt PSCDS_CshBlstrInOut PSCDS_BkBlstrInOut PSCDS_LmbrUDnFdRr PSCDS_LmbrFwdRr PSCDS_LmbrUpDwn PSCDS_UprShldrFdRr PSCDS_HdrstTltFwdRr PSCDS_HdrstWngInOt PSCDS_HdrstUDnFdRr PSCDS_HdrstFwdRrwd PSCDS_HdrstUpDn PSCDS_MassgIntsty PSCDS_MassgTyp PSCDS_Massg;
SIG_GROUP_ 2155118592 PsngrStActPrty 1 : PSAP_UnsdRsrvd PSAP_DispSz PSAP_CshLgthAdjFdRr PSAP_CshBlstrInOut PSAP_BkBlstrInOut PSAP_BkCshBlstrInOut PSAP_LmbrUpDnFdRr PSAP_LmbrFwdRr PSAP_LmbrUpDwn PSAP_UprShldrFwdRr PSAP_HdrstTltFwdRr PSAP_HdrstWngsInOut PSAP_HdrstUpDnFdRr PSAP_HdrstFwdRrwd PSAP_HdrstUpDn PSAP_Massg;
SIG_GROUP_ 2155102208 DrvStMassgPrty 1 : DSMP_UnsdRsrvd DSMP_MaxDispVal DSMP_Type15 DSMP_Type14 DSMP_Type13 DSMP_Type12 DSMP_Type11 DSMP_Type10 DSMP_Type9 DSMP_Type8 DSMP_Type7 DSMP_Type6 DSMP_Type5 DSMP_Type4 DSMP_Type3 DSMP_Type2 DSMP_Type1;
SIG_GROUP_ 2155085824 DrvStCtlDispStat 1 : DSCDS_UnsdRsrvd DSCDS_DispReq DSCDS_DispSz DSCDS_CshLgAdjFdRr DSCDS_BkCshBlstInOt DSCDS_CshBlstrInOut DSCDS_BkBlstrInOut DSCDS_LmbrUDnFdRr DSCDS_LmbrFwdRr DSCDS_LmbrUpDwn DSCDS_UprShldrFdRr DSCDS_HdrstTltFwdRr DSCDS_HdrstWngInOt DSCDS_HdrstUDnFdRr DSCDS_HdrstFwdRrwd DSCDS_HdrstUpDn DSCDS_MassgIntsty DSCDS_MassgTyp DSCDS_Massg;
SIG_GROUP_ 2155069440 DrvStActPrty 1 : DSAP_UnsdRsrvd DSAP_DispSz DSAP_CshLgthAdjFdRr DSAP_BkCshBlstrInOut DSAP_CshBlstrInOut DSAP_BkBlstrInOut DSAP_LmbrUpDnFdRr DSAP_LmbrFwdRr DSAP_LmbrUpDwn DSAP_UprShldrFwdRr DSAP_HdrstTltFwdRr DSAP_HdrstWngsInOut DSAP_HdrstUpDnFdRr DSAP_HdrstFwdRrwd DSAP_HdrstUpDn DSAP_Massg;
SIG_GROUP_ 2152480768 PerfDatRecLstLpInfo 1 : PDRLLI_LstLpTmSecs PDRLLI_LstLpTmMins PDRLLI_LstLpTm100s;
SIG_GROUP_ 2152480768 PerfDatRecBstLpInfo 1 : PDRBLI_BstLpTmSecs PDRBLI_BstLpTmMins PDRBLI_BstLpTm100s;
SIG_GROUP_ 2152497152 PerfDatRecRltmInfo 1 : PDRRI_LpDiffTm10s PDRRI_LpDiffTmSecs PDRRI_CrLpTm10sSec PDRRI_CrLpTmSecs PDRRI_CrLpTmMins;
SIG_GROUP_ 2149883904 BTTethrngPrngRsp 1 : BTPR_RspVal BTPR_RspInfoAvail BTPR_RspStat;
SIG_GROUP_ 2150252544 EngyConsmpHistGrph 1 : ECHG_YAxisMaxVal ECHG_XAxisTkMrkIntvl ECHG_Column10 ECHG_Column09 ECHG_Column08 ECHG_Column07 ECHG_Column06 ECHG_Column05 ECHG_Column04 ECHG_Column03 ECHG_Column02 ECHG_Column01 ECHG_EngyCnsmdAvg ECHG_MeasUnit;
SIG_GROUP_ 2155913216 PedFrndlyAlrtStat 1 : PFAS_SrvPedAlrtIO PFAS_PFASysStat PFAS_PFASndVolCtrl PFAS_PFASndGenEn PFAS_PFARevSnd PFAS_PFAFwdSnd PFAS_PFACrsOvrSpd;
SIG_GROUP_ 2152095744 SusPerfMdCustAvl 1 : SPMCA_SusPrfMd6Avl SPMCA_SusPrfMd5Avl SPMCA_SusPrfMd4Avl SPMCA_SusPrfMd3Avl SPMCA_SusPrfMd2Avl SPMCA_SusPrfMd1Avl;
SIG_GROUP_ 2152095744 StrPerfMdCustAvl 1 : SPMCA_StrPrfMd6Avl SPMCA_StrPrfMd5Avl SPMCA_StrPrfMd4Avl SPMCA_StrPrfMd3Avl SPMCA_StrPrfMd2Avl SPMCA_StrPrfMd1Avl;
SIG_GROUP_ 2152095744 SndPerfMdCustAvl 1 : SPMCA_SndPrfMd6Avl SPMCA_SndPrfMd5Avl SPMCA_SndPrfMd4Avl SPMCA_SndPrfMd3Avl SPMCA_SndPrfMd2Avl SPMCA_SndPrfMd1Avl;
SIG_GROUP_ 2152095744 DispPerfCustMdAvl 1 : DPMCA_DispPrfMd6Avl DPMCA_DispPrfMd5Avl DPMCA_DispPrfMd4Avl DPMCA_DispPrfMd3Avl DPMCA_DispPrfMd2Avl DPMCA_DispPrfMd1Avl;
SIG_GROUP_ 2152095744 DrvlnPerfMdCustAvl 1 : DPMCA_DrvlPrfMd6Avl DPMCA_DrvlPrfMd5Avl DPMCA_DrvlPrfMd4Avl DPMCA_DrvlPrfMd3Avl DPMCA_DrvlPrfMd2Avl DPMCA_DrvlPrfMd1Avl;
SIG_GROUP_ 2152611840 OBTCReq 1 : OBTCR_Prty OBTCR_Actv;
